VERSION ""

NS_ :

BS_:

BU_:IC_MMI AVM GW AC BCM DSM_D DSM_P FSCM CWC

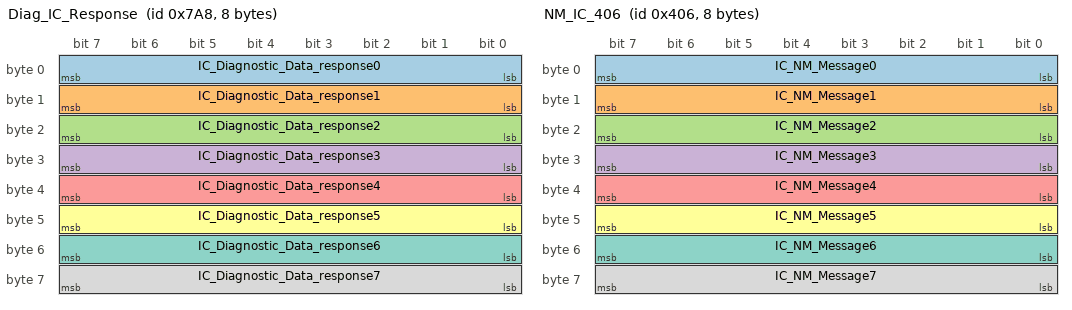
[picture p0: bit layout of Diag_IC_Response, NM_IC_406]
BO_ 1960 Diag_IC_Response: 8 IC_MMI
 SG_ IC_Diagnostic_Data_response0 : 7|8@0+ (1,0) [0|255] "" GW
 SG_ IC_Diagnostic_Data_response1 : 15|8@0+ (1,0) [0|255] "" GW
 SG_ IC_Diagnostic_Data_response2 : 23|8@0+ (1,0) [0|255] "" GW
 SG_ IC_Diagnostic_Data_response3 : 31|8@0+ (1,0) [0|255] "" GW
 SG_ IC_Diagnostic_Data_response4 : 39|8@0+ (1,0) [0|255] "" GW
 SG_ IC_Diagnostic_Data_response5 : 47|8@0+ (1,0) [0|255] "" GW
 SG_ IC_Diagnostic_Data_response6 : 55|8@0+ (1,0) [0|255] "" GW
 SG_ IC_Diagnostic_Data_response7 : 63|8@0+ (1,0) [0|255] "" GW

BO_ 1030 NM_IC_406: 8 IC_MMI
 SG_ IC_NM_Message0 : 7|8@0+ (1,0) [0|255] "" GW,AC,BCM
 SG_ IC_NM_Message1 : 15|8@0+ (1,0) [0|255] "" GW,AC,BCM
 SG_ IC_NM_Message2 : 23|8@0+ (1,0) [0|255] "" GW,AC,BCM
 SG_ IC_NM_Message3 : 31|8@0+ (1,0) [0|255] "" GW,AC,BCM
 SG_ IC_NM_Message4 : 39|8@0+ (1,0) [0|255] "" GW,AC,BCM
 SG_ IC_NM_Message5 : 47|8@0+ (1,0) [0|255] "" GW,AC,BCM
 SG_ IC_NM_Message6 : 55|8@0+ (1,0) [0|255] "" GW,AC,BCM
 SG_ IC_NM_Message7 : 63|8@0+ (1,0) [0|255] "" GW,AC,BCM

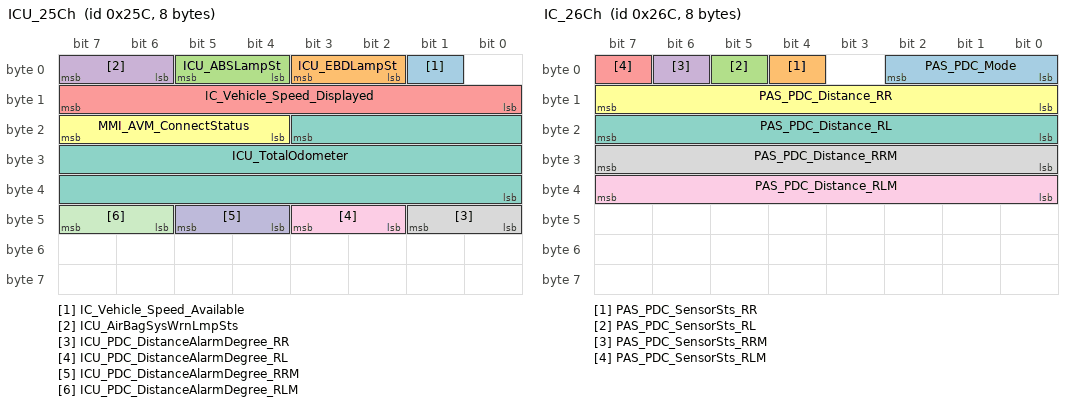
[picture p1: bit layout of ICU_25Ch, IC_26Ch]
BO_ 604 ICU_25Ch: 8 IC_MMI
 SG_ IC_Vehicle_Speed_Available : 1|1@0+ (1,0) [0|1] "" GW
 SG_ ICU_EBDLampSt : 3|2@0+ (1,0) [0|3] "" GW
 SG_ ICU_ABSLampSt : 5|2@0+ (1,0) [0|3] "" GW
 SG_ ICU_AirBagSysWrnLmpSts : 7|2@0+ (1,0) [0|3] "" GW
 SG_ IC_Vehicle_Speed_Displayed : 15|8@0+ (1,0) [0|255] "km/h" GW
 SG_ MMI_AVM_ConnectStatus : 23|4@0+ (1,0) [0|15] "" AVM,GW
 SG_ ICU_TotalOdometer : 19|20@0+ (1,0) [0|999999] "Km" AVM,GW,BCM
 SG_ ICU_PDC_DistanceAlarmDegree_RR : 41|2@0+ (1,0) [0|3] "" GW
 SG_ ICU_PDC_DistanceAlarmDegree_RL : 43|2@0+ (1,0) [0|3] "" GW
 SG_ ICU_PDC_DistanceAlarmDegree_RRM : 45|2@0+ (1,0) [0|3] "" GW
 SG_ ICU_PDC_DistanceAlarmDegree_RLM : 47|2@0+ (1,0) [0|3] "" GW

BO_ 620 IC_26Ch: 8 IC_MMI
 SG_ PAS_PDC_Mode : 2|3@0+ (1,0) [0|7] "" GW
 SG_ PAS_PDC_SensorSts_RR : 4|1@0+ (1,0) [0|1] "" GW
 SG_ PAS_PDC_SensorSts_RL : 5|1@0+ (1,0) [0|1] "" GW
 SG_ PAS_PDC_SensorSts_RRM : 6|1@0+ (1,0) [0|1] "" GW
 SG_ PAS_PDC_SensorSts_RLM : 7|1@0+ (1,0) [0|1] "" GW
 SG_ PAS_PDC_Distance_RR : 15|8@0+ (0.01,0) [0|1.5] "m" GW
 SG_ PAS_PDC_Distance_RL : 23|8@0+ (0.01,0) [0|1.5] "m" GW
 SG_ PAS_PDC_Distance_RRM : 31|8@0+ (0.01,0) [0|1.5] "m" GW
 SG_ PAS_PDC_Distance_RLM : 39|8@0+ (0.01,0) [0|1.5] "m" GW

BO_ 648 MMI_288h: 8 IC_MMI
 SG_ MMI_ACAUTOReqValid : 0|1@0+ (1,0) [0|1] "" GW,AC
 SG_ MMI_ACAUTOReq : 1|1@0+ (1,0) [0|1] "" GW,AC
 SG_ MMI_ACCompressorReqValid : 2|1@0+ (1,0) [0|1] "" GW,AC
 SG_ MMI_ACCompressorReq : 3|1@0+ (1,0) [0|1] "" GW,AC
 SG_ MMI_ACMaxReqValid : 4|1@0+ (1,0) [0|1] "" GW,AC
 SG_ MMI_ACMaxReq : 5|1@0+ (1,0) [0|1] "" GW,AC
 SG_ MMI_ACOFFReqValid : 6|1@0+ (1,0) [0|1] "" GW,AC
 SG_ MMI_ACOFFReq : 7|1@0+ (1,0) [0|1] "" GW,AC
 SG_ MMI_InsideTempIncDecReqValid : 8|1@0+ (1,0) [0|1] "" GW,AC
 SG_ MMI_InsideTempIncDecReq : 9|1@0+ (1,0) [0|1] "" GW,AC
 SG_ MMI_BLOWERReqValid : 10|1@0+ (1,0) [0|1] "" GW,AC
 SG_ MMI_BLOWERReq : 11|1@0+ (1,0) [0|1] "" GW,AC
 SG_ MMI_ACBlowModeReqValid : 12|1@0+ (1,0) [0|1] "" GW,AC
 SG_ MMI_ACBlowModeReq : 15|3@0+ (1,0) [0|7] "" GW,AC
 SG_ MMI_CirculatingModeSetValid : 16|1@0+ (1,0) [0|1] "" GW,AC
 SG_ MMI_CirculatingModeSet : 17|1@0+ (1,0) [0|1] "" GW,AC
 SG_ MMI_InsideTempSetValid : 18|1@0+ (1,0) [0|1] "" GW,AC
 SG_ MMI_InsideTempSet : 23|5@0+ (0.5,18) [18|32] "℃" GW,AC
 SG_ MMI_SeatHeatReq_right : 25|2@0+ (1,0) [0|3] "" GW,AC
 SG_ MMI_SeatHeatReq_left : 27|2@0+ (1,0) [0|3] "" GW,AC
 SG_ MMI_BLOWERGearSetValid : 28|1@0+ (1,0) [0|1] "" GW,AC
 SG_ MMI_BLOWERGearSet : 31|3@0+ (1,0) [0|7] "" GW,AC
 SG_ MMI_FrontDeforstReq : 33|2@0+ (1,0) [0|3] "" GW,AC
 SG_ MMI_RearDeforstReq : 35|2@0+ (1,0) [0|3] "" GW,AC
 SG_ MMI_EnergyRecoveryContr : 38|3@0+ (1,0) [0|7] "" GW
 SG_ MMI_RearViewMirrorHeatReq : 41|2@0+ (1,0) [0|3] "" GW,AC
 SG_ MMI_AnionNegativeIonReq : 43|2@0+ (1,0) [0|3] "" GW,AC

BO_ 370 MMI_172h: 8 IC_MMI
 SG_ MMI_LDW_Main_Switch : 0|1@0+ (1,0) [0|1] "" GW
 SG_ MMI_LDW_Switch_Available : 1|1@0+ (1,0) [0|1] "" GW
 SG_ MMI_FCW_Sensitivity : 3|2@0+ (1,0) [0|3] "" GW
 SG_ MMI_FCW_Main_Switch : 4|1@0+ (1,0) [0|1] "" GW
 SG_ MMI_FCW_Switch_Available : 5|1@0+ (1,0) [0|1] "" GW
 SG_ MMI_AEB_Main_Switch : 6|1@0+ (1,0) [0|1] "" GW
 SG_ MMI_AEB_Switch_Available : 7|1@0+ (1,0) [0|1] "" GW
 SG_ MMI_TSR_Main_Switch : 10|1@0+ (1,0) [0|1] "" GW
 SG_ MMI_TSR_Switch_Available : 11|1@0+ (1,0) [0|1] "" GW
 SG_ MMI_IHC_Main_Switch : 12|1@0+ (1,0) [0|1] "" GW
 SG_ MMI_IHC_Switch_Available : 13|1@0+ (1,0) [0|1] "" GW
 SG_ MMI_LDW_Sensitivity : 15|2@0+ (1,0) [0|3] "" GW
 SG_ MMI_BSD_Main_Switch : 16|1@0+ (1,0) [0|1] "" GW
 SG_ MMI_BSD_Switch_Available : 17|1@0+ (1,0) [0|1] "" GW
 SG_ MMI_BSD_Sensitivity : 19|2@0+ (1,0) [0|3] "" GW
 SG_ MMI_EPS_ModeSwitch : 22|3@0+ (1,0) [0|7] "" GW
 SG_ MMI_PauseContinueChrgRQ : 25|2@0+ (1,0) [0|3] "" GW
 SG_ MMI_WCBS_CstSwitch : 26|1@0+ (1,0) [0|1] "" GW
 SG_ MMI_OperationMode : 30|3@0+ (1,0) [0|7] "" GW
 SG_ MMI_ChrgMaxPower : 38|7@0+ (1,0) [0|100] "%" GW
 SG_ MMI_ChrgCurrentSet : 47|8@0+ (0.1,0) [0|25.5] "A" GW

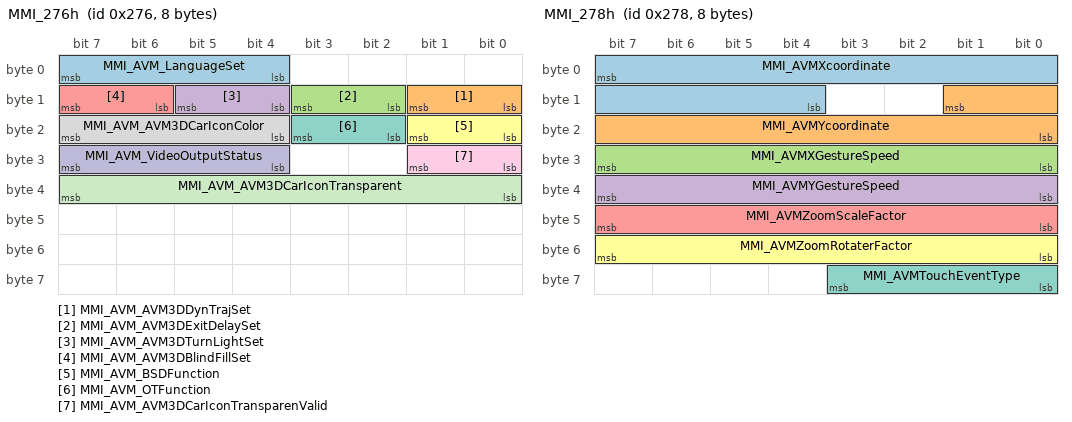
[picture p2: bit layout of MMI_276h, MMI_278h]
BO_ 630 MMI_276h: 8 IC_MMI
 SG_ MMI_AVM_LanguageSet : 7|4@0+ (1,0) [0|15] "" AVM,GW
 SG_ MMI_AVM_AVM3DDynTrajSet : 9|2@0+ (1,0) [0|3] "" AVM,GW
 SG_ MMI_AVM_AVM3DExitDelaySet : 11|2@0+ (1,0) [0|3] "" AVM,GW
 SG_ MMI_AVM_AVM3DTurnLightSet : 13|2@0+ (1,0) [0|3] "" AVM,GW
 SG_ MMI_AVM_AVM3DBlindFillSet : 15|2@0+ (1,0) [0|3] "" AVM,GW
 SG_ MMI_AVM_BSDFunction : 17|2@0+ (1,0) [0|3] "" AVM,GW
 SG_ MMI_AVM_OTFunction : 19|2@0+ (1,0) [0|3] "" AVM,GW
 SG_ MMI_AVM_AVM3DCarIconColor : 23|4@0+ (1,0) [0|15] "" AVM,GW
 SG_ MMI_AVM_AVM3DCarIconTransparenValid : 25|2@0+ (1,0) [0|3] "" AVM,GW
 SG_ MMI_AVM_VideoOutputStatus : 31|4@0+ (1,0) [0|15] "" AVM,GW
 SG_ MMI_AVM_AVM3DCarIconTransparent : 39|8@0+ (1,0) [0|100] "%" AVM,GW

BO_ 632 MMI_278h: 8 IC_MMI
 SG_ MMI_AVMXcoordinate : 7|12@0+ (1,0) [0|4094] "" AVM,GW
 SG_ MMI_AVMYcoordinate : 9|10@0+ (1,0) [0|1022] "" AVM,GW
 SG_ MMI_AVMXGestureSpeed : 31|8@0+ (1,0) [0|254] "pixels/100ms" AVM,GW
 SG_ MMI_AVMYGestureSpeed : 39|8@0+ (1,0) [0|254] "pixels/100ms" AVM,GW
 SG_ MMI_AVMZoomScaleFactor : 47|8@0+ (1,0) [0|254] "" AVM,GW
 SG_ MMI_AVMZoomRotaterFactor : 55|8@0+ (1,0) [0|254] "" AVM,GW
 SG_ MMI_AVMTouchEventType : 59|4@0+ (1,0) [0|15] "" AVM,GW

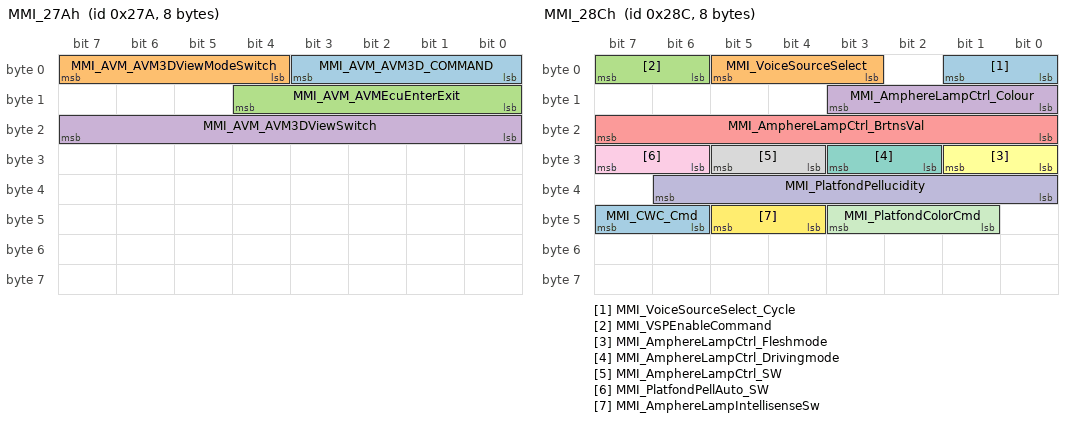
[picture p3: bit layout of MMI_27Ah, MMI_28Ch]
BO_ 634 MMI_27Ah: 8 IC_MMI
 SG_ MMI_AVM_AVM3D_COMMAND : 3|4@0+ (1,0) [0|15] "" AVM,GW
 SG_ MMI_AVM_AVM3DViewModeSwitch : 7|4@0+ (1,0) [0|15] "" AVM,GW
 SG_ MMI_AVM_AVMEcuEnterExit : 12|5@0+ (1,0) [0|31] "" AVM,GW
 SG_ MMI_AVM_AVM3DViewSwitch : 23|8@0+ (1,0) [0|255] "" AVM,GW

BO_ 652 MMI_28Ch: 8 IC_MMI
 SG_ MMI_VoiceSourceSelect_Cycle : 1|2@0+ (1,0) [0|3] "" GW
 SG_ MMI_VoiceSourceSelect : 5|3@0+ (1,0) [0|7] "" GW
 SG_ MMI_VSPEnableCommand : 7|2@0+ (1,0) [0|3] "" GW
 SG_ MMI_AmphereLampCtrl_Colour : 11|4@0+ (1,0) [0|15] "" GW
 SG_ MMI_AmphereLampCtrl_BrtnsVal : 23|8@0+ (1,0) [0|100] "" GW
 SG_ MMI_AmphereLampCtrl_Fleshmode : 25|2@0+ (1,0) [0|3] "" GW
 SG_ MMI_AmphereLampCtrl_Drivingmode : 27|2@0+ (1,0) [0|3] "" GW
 SG_ MMI_AmphereLampCtrl_SW : 29|2@0+ (1,0) [0|3] "" GW
 SG_ MMI_PlatfondPellAuto_SW : 31|2@0+ (1,0) [0|3] "" Vector__XXX
 SG_ MMI_PlatfondPellucidity : 38|7@0+ (1,0) [0|100] "%" Vector__XXX
 SG_ MMI_PlatfondColorCmd : 43|3@0+ (1,0) [0|7] "" GW
 SG_ MMI_AmphereLampIntellisenseSw : 45|2@0+ (1,0) [0|3] "" GW
 SG_ MMI_CWC_Cmd : 47|2@0+ (1,0) [0|3] "" GW,CWC

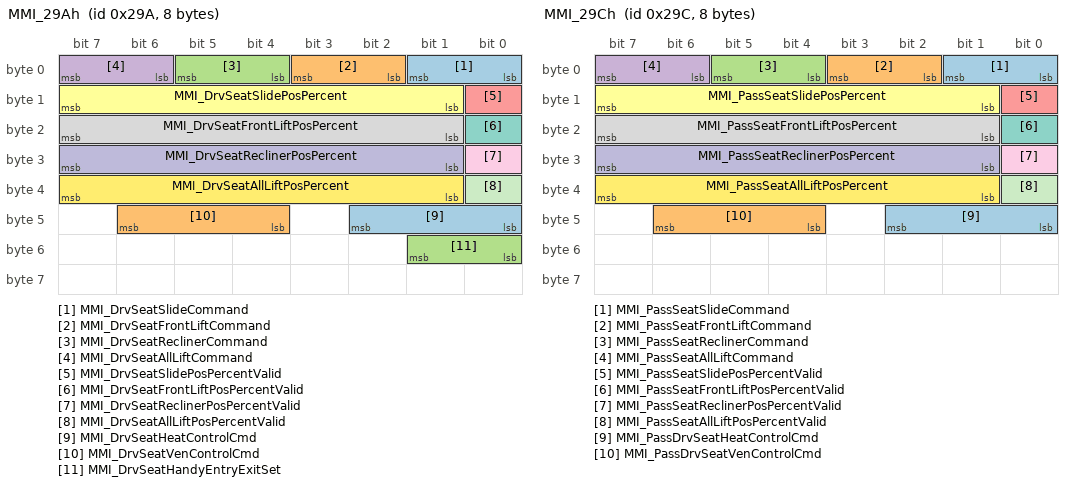
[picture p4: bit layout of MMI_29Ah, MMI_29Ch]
BO_ 666 MMI_29Ah: 8 IC_MMI
 SG_ MMI_DrvSeatSlideCommand : 1|2@0+ (1,0) [0|3] "" DSM_D
 SG_ MMI_DrvSeatFrontLiftCommand : 3|2@0+ (1,0) [0|3] "" DSM_D
 SG_ MMI_DrvSeatReclinerCommand : 5|2@0+ (1,0) [0|3] "" DSM_D
 SG_ MMI_DrvSeatAllLiftCommand : 7|2@0+ (1,0) [0|3] "" DSM_D
 SG_ MMI_DrvSeatSlidePosPercentValid : 8|1@0+ (1,0) [0|1] "" DSM_D
 SG_ MMI_DrvSeatSlidePosPercent : 15|7@0+ (1,0) [0|100] "%" DSM_D
 SG_ MMI_DrvSeatFrontLiftPosPercentValid : 16|1@0+ (1,0) [0|1] "" DSM_D
 SG_ MMI_DrvSeatFrontLiftPosPercent : 23|7@0+ (1,0) [0|100] "%" DSM_D
 SG_ MMI_DrvSeatReclinerPosPercentValid : 24|1@0+ (1,0) [0|1] "" DSM_D
 SG_ MMI_DrvSeatReclinerPosPercent : 31|7@0+ (1,0) [0|100] "%" DSM_D
 SG_ MMI_DrvSeatAllLiftPosPercentValid : 32|1@0+ (1,0) [0|1] "" DSM_D
 SG_ MMI_DrvSeatAllLiftPosPercent : 39|7@0+ (1,0) [0|100] "%" DSM_D
 SG_ MMI_DrvSeatHeatControlCmd : 42|3@0+ (1,0) [0|7] "" FSCM
 SG_ MMI_DrvSeatVenControlCmd : 46|3@0+ (1,0) [0|7] "" FSCM
 SG_ MMI_DrvSeatHandyEntryExitSet : 49|2@0+ (1,0) [0|3] "" DSM_D

BO_ 668 MMI_29Ch: 8 IC_MMI
 SG_ MMI_PassSeatSlideCommand : 1|2@0+ (1,0) [0|3] "" DSM_P
 SG_ MMI_PassSeatFrontLiftCommand : 3|2@0+ (1,0) [0|3] "" DSM_P
 SG_ MMI_PassSeatReclinerCommand : 5|2@0+ (1,0) [0|3] "" DSM_P
 SG_ MMI_PassSeatAllLiftCommand : 7|2@0+ (1,0) [0|3] "" DSM_P
 SG_ MMI_PassSeatSlidePosPercentValid : 8|1@0+ (1,0) [0|1] "" DSM_P
 SG_ MMI_PassSeatSlidePosPercent : 15|7@0+ (1,0) [0|100] "%" DSM_P
 SG_ MMI_PassSeatFrontLiftPosPercentValid : 16|1@0+ (1,0) [0|1] "" DSM_P
 SG_ MMI_PassSeatFrontLiftPosPercent : 23|7@0+ (1,0) [0|100] "%" DSM_P
 SG_ MMI_PassSeatReclinerPosPercentValid : 24|1@0+ (1,0) [0|1] "" DSM_P
 SG_ MMI_PassSeatReclinerPosPercent : 31|7@0+ (1,0) [0|100] "%" DSM_P
 SG_ MMI_PassSeatAllLiftPosPercentValid : 32|1@0+ (1,0) [0|1] "" DSM_P
 SG_ MMI_PassSeatAllLiftPosPercent : 39|7@0+ (1,0) [0|100] "%" DSM_P
 SG_ MMI_PassDrvSeatHeatControlCmd : 42|3@0+ (1,0) [0|7] "" FSCM
 SG_ MMI_PassDrvSeatVenControlCmd : 46|3@0+ (1,0) [0|7] "" FSCM

BO_ 670 MMI_29Eh: 8 IC_MMI
 SG_ MMI_HazardLightCmd : 1|2@0+ (1,0) [0|3] "" BCM
 SG_ MMI_BCMLightCmd : 3|2@0+ (1,0) [0|3] "" BCM
 SG_ MMI_TailgateCmd : 5|2@0+ (1,0) [0|3] "" BCM
 SG_ MMI_RearViewCmd : 7|2@0+ (1,0) [0|3] "" BCM
 SG_ MMI_DoorLockCmd : 11|2@0+ (1,0) [0|3] "" BCM
 SG_ MMI_LowBeamLightCmd : 13|2@0+ (1,0) [0|3] "" BCM
 SG_ MMI_HighBeamLightCmd : 15|2@0+ (1,0) [0|3] "" BCM
 SG_ MMI_FoglightCmd : 17|2@0+ (1,0) [0|3] "" BCM
 SG_ MMI_WiperCmd : 20|3@0+ (1,0) [0|7] "" BCM
 SG_ MMI_FronLeftDoorWindowCmd : 23|3@0+ (1,0) [0|7] "" BCM
 SG_ MMI_FronRightDoorWindowCmd : 26|3@0+ (1,0) [0|7] "" BCM
 SG_ MMI_RearLeftDoorWindowCmd : 29|3@0+ (1,0) [0|7] "" BCM
 SG_ MMI_FourDoorWindowCmd : 33|2@0+ (1,0) [0|3] "" BCM
 SG_ MMI_FrontDoorWindowCmd : 35|2@0+ (1,0) [0|3] "" BCM
 SG_ MMI_AutolightSWCmd : 37|2@0+ (1,0) [0|3] "" BCM
 SG_ MMI_RainAutoClsWindowCmd : 39|2@0+ (1,0) [0|3] "" BCM
 SG_ MMI_RearRightDoorWindowCmd : 42|3@0+ (1,0) [0|7] "" BCM
 SG_ MMI_RearViewMirrorSelect : 47|2@0+ (1,0) [0|3] "" BCM
 SG_ MMI_RearViewMirrorUpDown : 49|2@0+ (1,0) [0|3] "" BCM
 SG_ MMI_RearViewMirrorLeftRight : 51|2@0+ (1,0) [0|3] "" BCM
 SG_ MMI_LockVehicleWarmingTip : 53|2@0+ (1,0) [0|3] "" BCM
 SG_ MMI_UnlockVehicleOpenCourtesyLampSW : 55|2@0+ (1,0) [0|3] "" BCM
 SG_ MMI_AccLampSet : 59|2@0+ (1,0) [0|3] "" BCM
 SG_ MMI_RearViewMirrorAutoFoldFuc : 61|2@0+ (1,0) [0|3] "" BCM

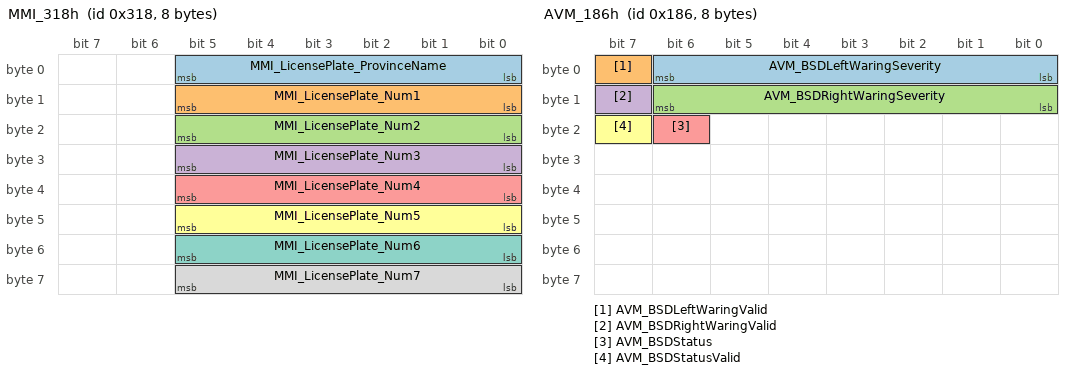
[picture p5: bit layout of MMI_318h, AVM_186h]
BO_ 792 MMI_318h: 8 IC_MMI
 SG_ MMI_LicensePlate_ProvinceName : 5|6@0+ (1,0) [0|31] "" AVM,GW
 SG_ MMI_LicensePlate_Num1 : 13|6@0+ (1,0) [0|36] "" AVM,GW
 SG_ MMI_LicensePlate_Num2 : 21|6@0+ (1,0) [0|36] "" AVM,GW
 SG_ MMI_LicensePlate_Num3 : 29|6@0+ (1,0) [0|36] "" AVM,GW
 SG_ MMI_LicensePlate_Num4 : 37|6@0+ (1,0) [0|36] "" AVM,GW
 SG_ MMI_LicensePlate_Num5 : 45|6@0+ (1,0) [0|36] "" AVM,GW
 SG_ MMI_LicensePlate_Num6 : 53|6@0+ (1,0) [0|36] "" AVM,GW
 SG_ MMI_LicensePlate_Num7 : 61|6@0+ (1,0) [0|36] "" AVM,GW

BO_ 390 AVM_186h: 8 AVM
 SG_ AVM_BSDLeftWaringSeverity : 6|7@0+ (1,0) [0|126] "" IC_MMI
 SG_ AVM_BSDLeftWaringValid : 7|1@0+ (1,0) [0|1] "" IC_MMI
 SG_ AVM_BSDRightWaringSeverity : 14|7@0+ (1,0) [0|126] "" IC_MMI
 SG_ AVM_BSDRightWaringValid : 15|1@0+ (1,0) [0|1] "" IC_MMI
 SG_ AVM_BSDStatus : 22|1@0+ (1,0) [0|1] "" IC_MMI
 SG_ AVM_BSDStatusValid : 23|1@0+ (1,0) [0|1] "" IC_MMI

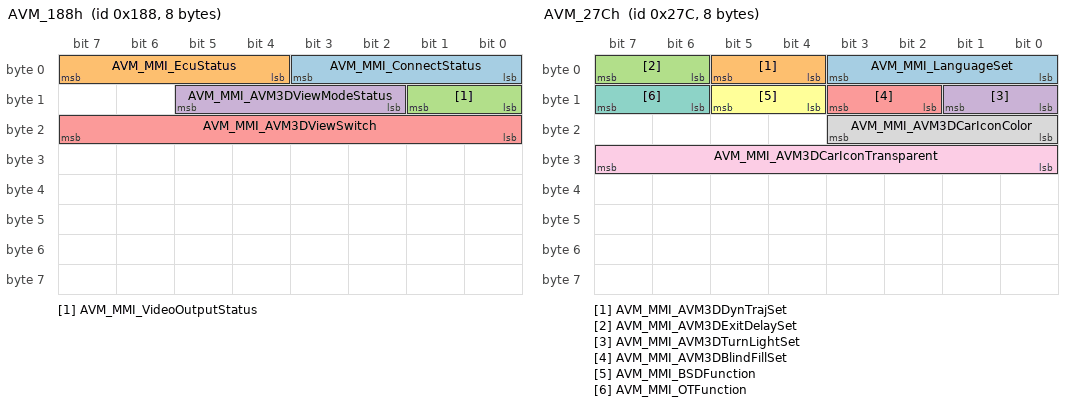
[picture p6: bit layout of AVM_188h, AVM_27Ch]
BO_ 392 AVM_188h: 8 AVM
 SG_ AVM_MMI_ConnectStatus : 3|4@0+ (1,0) [0|7] "" IC_MMI
 SG_ AVM_MMI_EcuStatus : 7|4@0+ (1,0) [0|3] "" IC_MMI
 SG_ AVM_MMI_VideoOutputStatus : 9|2@0+ (1,0) [0|3] "" IC_MMI
 SG_ AVM_MMI_AVM3DViewModeStatus : 13|4@0+ (1,0) [0|15] "" IC_MMI
 SG_ AVM_MMI_AVM3DViewSwitch : 23|8@0+ (1,0) [0|255] "" IC_MMI

BO_ 636 AVM_27Ch: 8 AVM
 SG_ AVM_MMI_LanguageSet : 3|4@0+ (1,0) [0|15] "" IC_MMI
 SG_ AVM_MMI_AVM3DDynTrajSet : 5|2@0+ (1,0) [0|3] "" IC_MMI
 SG_ AVM_MMI_AVM3DExitDelaySet : 7|2@0+ (1,0) [0|3] "" IC_MMI
 SG_ AVM_MMI_AVM3DTurnLightSet : 9|2@0+ (1,0) [0|3] "" IC_MMI
 SG_ AVM_MMI_AVM3DBlindFillSet : 11|2@0+ (1,0) [0|3] "" IC_MMI
 SG_ AVM_MMI_BSDFunction : 13|2@0+ (1,0) [0|3] "" IC_MMI
 SG_ AVM_MMI_OTFunction : 15|2@0+ (1,0) [0|3] "" IC_MMI
 SG_ AVM_MMI_AVM3DCarIconColor : 19|4@0+ (1,0) [0|15] "" IC_MMI
 SG_ AVM_MMI_AVM3DCarIconTransparent : 31|8@0+ (1,0) [0|100] "%" IC_MMI

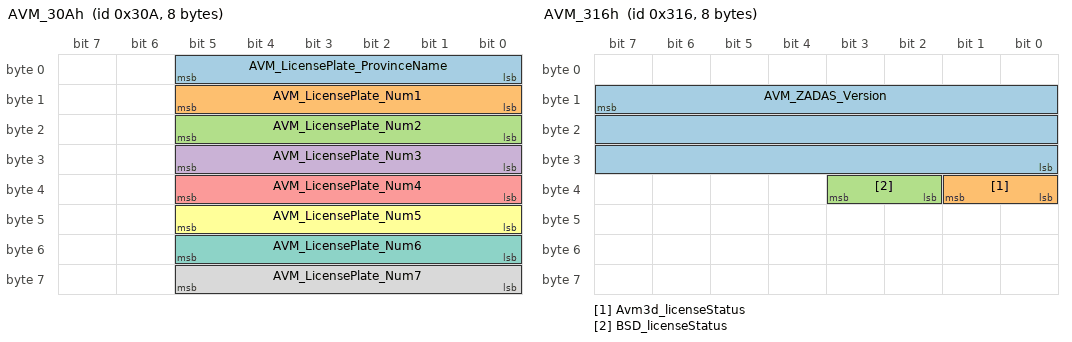
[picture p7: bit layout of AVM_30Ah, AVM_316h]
BO_ 778 AVM_30Ah: 8 AVM
 SG_ AVM_LicensePlate_ProvinceName : 5|6@0+ (1,0) [0|31] "" IC_MMI
 SG_ AVM_LicensePlate_Num1 : 13|6@0+ (1,0) [0|36] "" IC_MMI
 SG_ AVM_LicensePlate_Num2 : 21|6@0+ (1,0) [0|36] "" IC_MMI
 SG_ AVM_LicensePlate_Num3 : 29|6@0+ (1,0) [0|36] "" IC_MMI
 SG_ AVM_LicensePlate_Num4 : 37|6@0+ (1,0) [0|36] "" IC_MMI
 SG_ AVM_LicensePlate_Num5 : 45|6@0+ (1,0) [0|36] "" IC_MMI
 SG_ AVM_LicensePlate_Num6 : 53|6@0+ (1,0) [0|36] "" IC_MMI
 SG_ AVM_LicensePlate_Num7 : 61|6@0+ (1,0) [0|36] "" IC_MMI

BO_ 788 AVM_314h: 8 AVM
 SG_ AVM_MCU_Version : 15|24@0+ (1,0) [0|16777214] "" IC_MMI
 SG_ AVM_BSP_Version : 39|24@0+ (1,0) [0|16777214] "" IC_MMI

BO_ 790 AVM_316h: 8 AVM
 SG_ AVM_ZADAS_Version : 15|24@0+ (1,0) [0|16777214] "" IC_MMI
 SG_ Avm3d_licenseStatus : 33|2@0+ (1,0) [0|3] "" IC_MMI
 SG_ BSD_licenseStatus : 35|2@0+ (1,0) [0|3] "" IC_MMI

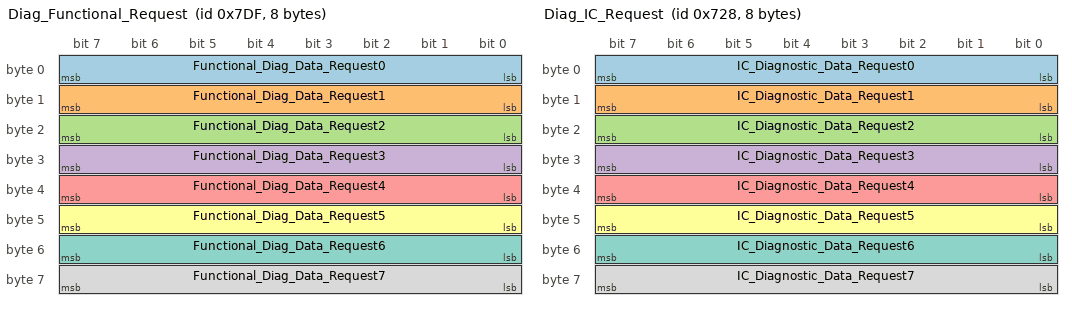
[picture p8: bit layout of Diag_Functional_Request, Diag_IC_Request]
BO_ 2015 Diag_Functional_Request: 8 GW
 SG_ Functional_Diag_Data_Request0 : 7|8@0+ (1,0) [0|255] "" IC_MMI,AVM,AC,BCM,DSM_D,DSM_P,FSCM,CWC
 SG_ Functional_Diag_Data_Request1 : 15|8@0+ (1,0) [0|255] "" IC_MMI,AVM,AC,BCM,DSM_D,DSM_P,FSCM,CWC
 SG_ Functional_Diag_Data_Request2 : 23|8@0+ (1,0) [0|255] "" IC_MMI,AVM,AC,BCM,DSM_D,DSM_P,FSCM,CWC
 SG_ Functional_Diag_Data_Request3 : 31|8@0+ (1,0) [0|255] "" IC_MMI,AVM,AC,BCM,DSM_D,DSM_P,FSCM,CWC
 SG_ Functional_Diag_Data_Request4 : 39|8@0+ (1,0) [0|255] "" IC_MMI,AVM,AC,BCM,DSM_D,DSM_P,FSCM,CWC
 SG_ Functional_Diag_Data_Request5 : 47|8@0+ (1,0) [0|255] "" IC_MMI,AVM,AC,BCM,DSM_D,DSM_P,FSCM,CWC
 SG_ Functional_Diag_Data_Request6 : 55|8@0+ (1,0) [0|255] "" IC_MMI,AVM,AC,BCM,DSM_D,DSM_P,FSCM,CWC
 SG_ Functional_Diag_Data_Request7 : 63|8@0+ (1,0) [0|255] "" IC_MMI,AVM,AC,BCM,DSM_D,DSM_P,FSCM,CWC

BO_ 1832 Diag_IC_Request: 8 GW
 SG_ IC_Diagnostic_Data_Request0 : 7|8@0+ (1,0) [0|255] "" IC_MMI
 SG_ IC_Diagnostic_Data_Request1 : 15|8@0+ (1,0) [0|255] "" IC_MMI
 SG_ IC_Diagnostic_Data_Request2 : 23|8@0+ (1,0) [0|255] "" IC_MMI
 SG_ IC_Diagnostic_Data_Request3 : 31|8@0+ (1,0) [0|255] "" IC_MMI
 SG_ IC_Diagnostic_Data_Request4 : 39|8@0+ (1,0) [0|255] "" IC_MMI
 SG_ IC_Diagnostic_Data_Request5 : 47|8@0+ (1,0) [0|255] "" IC_MMI
 SG_ IC_Diagnostic_Data_Request6 : 55|8@0+ (1,0) [0|255] "" IC_MMI
 SG_ IC_Diagnostic_Data_Request7 : 63|8@0+ (1,0) [0|255] "" IC_MMI

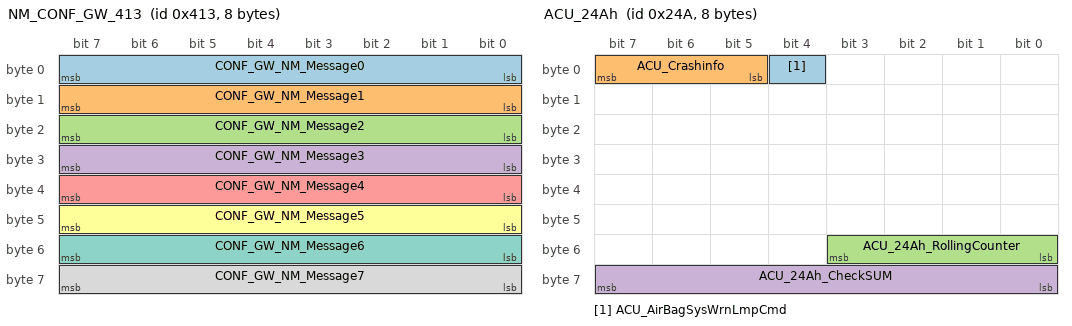
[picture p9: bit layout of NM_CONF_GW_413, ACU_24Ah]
BO_ 1043 NM_CONF_GW_413: 8 GW
 SG_ CONF_GW_NM_Message0 : 7|8@0+ (1,0) [0|255] "" IC_MMI,AC,BCM
 SG_ CONF_GW_NM_Message1 : 15|8@0+ (1,0) [0|255] "" IC_MMI,AC,BCM
 SG_ CONF_GW_NM_Message2 : 23|8@0+ (1,0) [0|255] "" IC_MMI,AC,BCM
 SG_ CONF_GW_NM_Message3 : 31|8@0+ (1,0) [0|255] "" IC_MMI,AC,BCM
 SG_ CONF_GW_NM_Message4 : 39|8@0+ (1,0) [0|255] "" IC_MMI,AC,BCM
 SG_ CONF_GW_NM_Message5 : 47|8@0+ (1,0) [0|255] "" IC_MMI,AC,BCM
 SG_ CONF_GW_NM_Message6 : 55|8@0+ (1,0) [0|255] "" IC_MMI,AC,BCM
 SG_ CONF_GW_NM_Message7 : 63|8@0+ (1,0) [0|255] "" IC_MMI,AC,BCM

BO_ 586 ACU_24Ah: 8 GW
 SG_ ACU_AirBagSysWrnLmpCmd : 4|1@0+ (1,0) [0|1] "" IC_MMI,BCM
 SG_ ACU_Crashinfo : 7|3@0+ (1,0) [0|7] "" IC_MMI,BCM
 SG_ ACU_24Ah_RollingCounter : 51|4@0+ (1,0) [0|15] "" IC_MMI,BCM
 SG_ ACU_24Ah_CheckSUM : 63|8@0+ (1,0) [0|255] "" IC_MMI,BCM

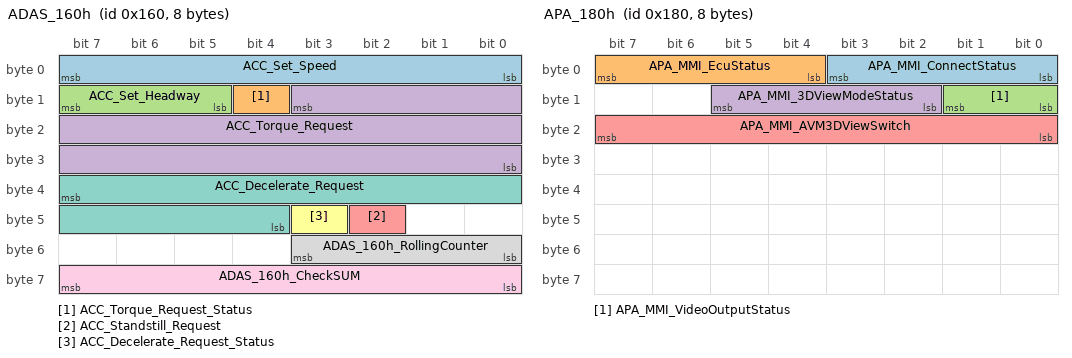
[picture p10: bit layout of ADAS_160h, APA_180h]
BO_ 352 ADAS_160h: 8 GW
 SG_ ACC_Set_Speed : 7|8@0+ (1,0) [0|255] "kph" IC_MMI
 SG_ ACC_Torque_Request_Status : 12|1@0+ (1,0) [0|1] "" IC_MMI
 SG_ ACC_Set_Headway : 15|3@0+ (1,0) [0|7] "" IC_MMI
 SG_ ACC_Torque_Request : 11|20@0+ (0.0625,-10000) [-10000|10000] "Nm" IC_MMI
 SG_ ACC_Standstill_Request : 42|1@0+ (1,0) [0|1] "" IC_MMI
 SG_ ACC_Decelerate_Request_Status : 43|1@0+ (1,0) [0|1] "" IC_MMI
 SG_ ACC_Decelerate_Request : 39|12@0+ (0.01,-20.47) [-20.47|20.47] "m/s2" IC_MMI
 SG_ ADAS_160h_RollingCounter : 51|4@0+ (1,0) [0|15] "" IC_MMI
 SG_ ADAS_160h_CheckSUM : 63|8@0+ (1,0) [0|255] "" IC_MMI

BO_ 354 ADAS_162h: 8 GW
 SG_ AEB_EHB_StopReq : 1|1@0+ (1,0) [0|1] "" IC_MMI
 SG_ AEB_Jerk_Request : 2|1@0+ (1,0) [0|1] "" IC_MMI
 SG_ AEB_Prefill_Request : 3|1@0+ (1,0) [0|1] "" IC_MMI
 SG_ AEB_Decelerate_Request_Status : 4|1@0+ (1,0) [0|1] "" IC_MMI
 SG_ AEB_State : 7|3@0+ (1,0) [0|7] "" IC_MMI
 SG_ FCW_State : 19|3@0+ (1,0) [0|7] "" IC_MMI
 SG_ AEB_Decelerate_Request : 15|12@0+ (0.01,-20.47) [-20.47|20.47] "m/s2" IC_MMI
 SG_ ADAS_Sensorstatus : 27|3@0+ (1,0) [0|7] "" IC_MMI
 SG_ HW_Warning_Level : 29|2@0+ (1,0) [0|3] "" IC_MMI
 SG_ FCW_Warning_Level : 31|2@0+ (1,0) [0|3] "" IC_MMI
 SG_ ACC_Override_Indicator : 32|1@0+ (1,0) [0|1] "" IC_MMI
 SG_ ACC_CIPV_Indicator : 33|1@0+ (1,0) [0|1] "" IC_MMI
 SG_ ACC_Auto_Cancel : 35|2@0+ (1,0) [0|2] "" IC_MMI
 SG_ ACC_Driver_Cancel : 36|1@0+ (1,0) [0|1] "" IC_MMI
 SG_ ACC_State : 39|3@0+ (1,0) [0|7] "" IC_MMI,AVM
 SG_ ACC_Go_Indicator : 46|1@0+ (1,0) [0|1] "" IC_MMI
 SG_ ACC_Takeover_Indicator : 47|1@0+ (1,0) [0|1] "" IC_MMI
 SG_ ADAS_162h_RollingCounter : 51|4@0+ (1,0) [0|15] "" IC_MMI
 SG_ ADAS_162h_CheckSUM : 63|8@0+ (1,0) [0|255] "" IC_MMI

BO_ 356 ADAS_164h: 8 GW
 SG_ TSR_State : 2|3@0+ (1,0) [0|4] "" IC_MMI
 SG_ DAS_TSR_Main_Switch : 3|1@0+ (1,0) [0|1] "" IC_MMI
 SG_ IHC_Mainbeam_Request : 4|1@0+ (1,0) [0|1] "" IC_MMI,BCM
 SG_ IHC_State : 7|3@0+ (1,0) [0|7] "" IC_MMI,BCM
 SG_ LDW_Line_Detect_Status : 10|3@0+ (1,0) [0|3] "" IC_MMI
 SG_ LDW_Warning : 12|2@0+ (1,0) [0|3] "" IC_MMI
 SG_ LDW_State : 15|3@0+ (1,0) [0|4] "" IC_MMI
 SG_ TSR_Targetspeed_Request : 23|8@0+ (1,0) [0|254] "km/h" IC_MMI
 SG_ LKA_Torque_Request_Status : 28|1@0+ (1,0) [0|1] "" IC_MMI
 SG_ LKA_State : 31|3@0+ (1,0) [0|5] "" IC_MMI
 SG_ LKA_Torque_Request : 26|11@0+ (0.01,-10.24) [-10.24|10.23] "Nm" IC_MMI
 SG_ ADAS_164h_RollingCounter : 43|4@0+ (1,0) [0|15] "" IC_MMI
 SG_ LKA_Takeover_Request : 46|1@0+ (1,0) [0|1] "" IC_MMI
 SG_ LKA_Hands_Off_Warning : 47|1@0+ (1,0) [0|1] "" IC_MMI
 SG_ DAS_LDW_Main_Switch : 48|1@0+ (1,0) [0|1] "" IC_MMI
 SG_ DAS_LDW_Sensitivity : 50|2@0+ (1,0) [0|3] "" IC_MMI
 SG_ DAS_FCW_Main_Switch : 51|1@0+ (1,0) [0|1] "" IC_MMI
 SG_ DAS_FCW_Sensitivity : 53|2@0+ (1,0) [0|3] "" IC_MMI
 SG_ DAS_AEB_Main_Switch : 54|1@0+ (1,0) [0|1] "" IC_MMI
 SG_ DAS_IHC_Main_Switch : 55|1@0+ (1,0) [0|1] "" IC_MMI
 SG_ ADAS_164h_CheckSUM : 63|8@0+ (1,0) [0|255] "" IC_MMI

BO_ 384 APA_180h: 8 GW
 SG_ APA_MMI_ConnectStatus : 3|4@0+ (1,0) [0|7] "" IC_MMI
 SG_ APA_MMI_EcuStatus : 7|4@0+ (1,0) [0|3] "" IC_MMI
 SG_ APA_MMI_VideoOutputStatus : 9|2@0+ (1,0) [0|3] "" IC_MMI
 SG_ APA_MMI_3DViewModeStatus : 13|4@0+ (1,0) [0|15] "" IC_MMI
 SG_ APA_MMI_AVM3DViewSwitch : 23|8@0+ (1,0) [0|255] "" IC_MMI

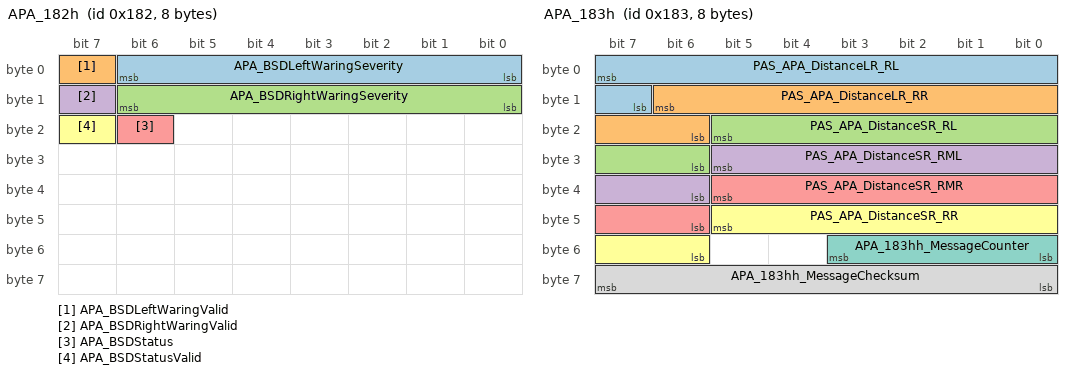
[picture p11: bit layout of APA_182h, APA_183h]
BO_ 386 APA_182h: 8 GW
 SG_ APA_BSDLeftWaringSeverity : 6|7@0+ (1,0) [0|126] "" IC_MMI
 SG_ APA_BSDLeftWaringValid : 7|1@0+ (1,0) [0|1] "" IC_MMI
 SG_ APA_BSDRightWaringSeverity : 14|7@0+ (1,0) [0|126] "" IC_MMI
 SG_ APA_BSDRightWaringValid : 15|1@0+ (1,0) [0|1] "" IC_MMI
 SG_ APA_BSDStatus : 22|1@0+ (1,0) [0|1] "" IC_MMI
 SG_ APA_BSDStatusValid : 23|1@0+ (1,0) [0|1] "" IC_MMI

BO_ 387 APA_183h: 8 GW
 SG_ PAS_APA_DistanceLR_RL : 7|9@0+ (0.01,0) [0|5] "m" IC_MMI
 SG_ PAS_APA_DistanceLR_RR : 14|9@0+ (0.01,0) [0|5] "m" IC_MMI
 SG_ PAS_APA_DistanceSR_RL : 21|8@0+ (0.01,0) [0|2.5] "m" IC_MMI
 SG_ PAS_APA_DistanceSR_RML : 29|8@0+ (0.01,0) [0|2.5] "m" IC_MMI
 SG_ PAS_APA_DistanceSR_RMR : 37|8@0+ (0.01,0) [0|2.5] "m" IC_MMI
 SG_ PAS_APA_DistanceSR_RR : 45|8@0+ (0.01,0) [0|2.5] "m" IC_MMI
 SG_ APA_183hh_MessageCounter : 51|4@0+ (1,0) [0|15] "" IC_MMI
 SG_ APA_183hh_MessageChecksum : 63|8@0+ (1,0) [0|255] "" IC_MMI

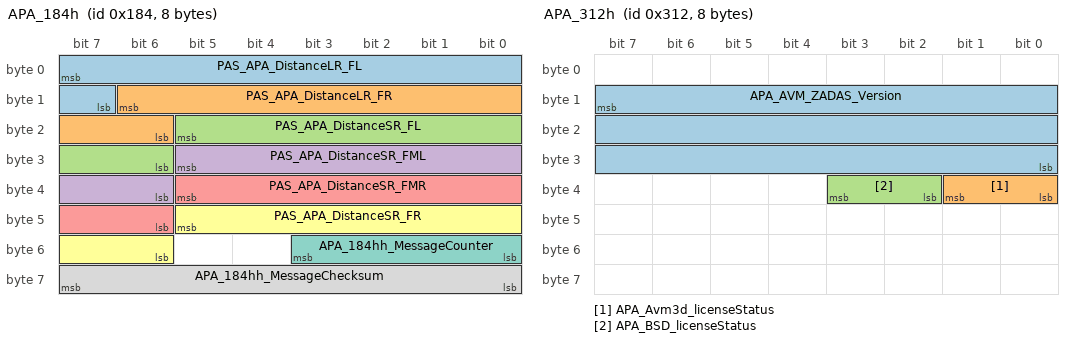
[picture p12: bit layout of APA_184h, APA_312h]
BO_ 388 APA_184h: 8 GW
 SG_ PAS_APA_DistanceLR_FL : 7|9@0+ (0.01,0) [0|5] "m" IC_MMI
 SG_ PAS_APA_DistanceLR_FR : 14|9@0+ (0.01,0) [0|5] "m" IC_MMI
 SG_ PAS_APA_DistanceSR_FL : 21|8@0+ (0.01,0) [0|2.5] "m" IC_MMI
 SG_ PAS_APA_DistanceSR_FML : 29|8@0+ (0.01,0) [0|2.5] "m" IC_MMI
 SG_ PAS_APA_DistanceSR_FMR : 37|8@0+ (0.01,0) [0|2.5] "m" IC_MMI
 SG_ PAS_APA_DistanceSR_FR : 45|8@0+ (0.01,0) [0|2.5] "m" IC_MMI
 SG_ APA_184hh_MessageCounter : 51|4@0+ (1,0) [0|15] "" IC_MMI
 SG_ APA_184hh_MessageChecksum : 63|8@0+ (1,0) [0|255] "" IC_MMI

BO_ 784 APA_310h: 8 GW
 SG_ APA_AVM_MCU_Version : 15|24@0+ (1,0) [0|16777214] "" IC_MMI
 SG_ APA_AVM_BSP_Version : 39|24@0+ (1,0) [0|16777214] "" IC_MMI

BO_ 786 APA_312h: 8 GW
 SG_ APA_AVM_ZADAS_Version : 15|24@0+ (1,0) [0|16777214] "" IC_MMI
 SG_ APA_Avm3d_licenseStatus : 33|2@0+ (1,0) [0|3] "" IC_MMI
 SG_ APA_BSD_licenseStatus : 35|2@0+ (1,0) [0|3] "" IC_MMI

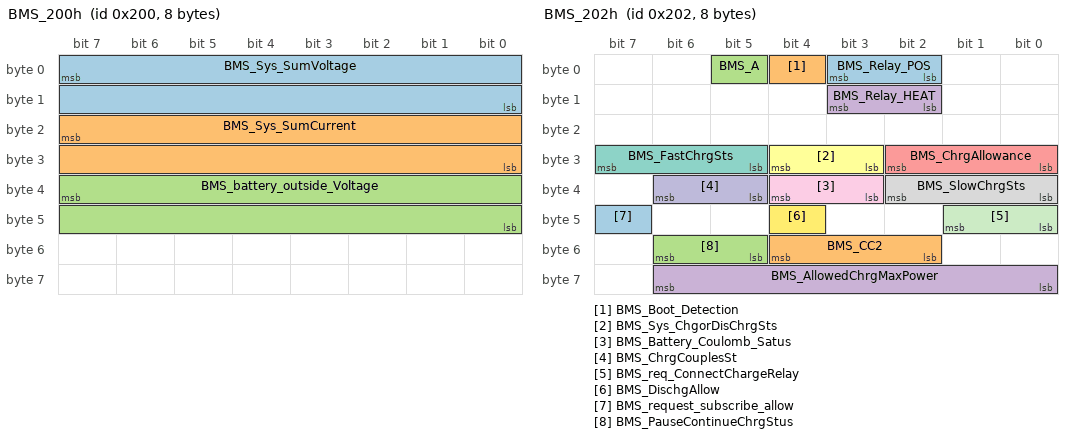
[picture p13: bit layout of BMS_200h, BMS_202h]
BO_ 512 BMS_200h: 8 GW
 SG_ BMS_Sys_SumVoltage : 7|16@0+ (0.1,0) [0|6000] "V" IC_MMI,AC
 SG_ BMS_Sys_SumCurrent : 23|16@0+ (0.1,-3000) [-3000|3000] "A" IC_MMI,AC
 SG_ BMS_battery_outside_Voltage : 39|16@0+ (0.1,0) [0|6000] "V" IC_MMI

BO_ 514 BMS_202h: 8 GW
 SG_ BMS_Relay_POS : 3|2@0+ (1,0) [0|3] "" IC_MMI
 SG_ BMS_Boot_Detection : 4|1@0+ (1,0) [0|1] "" IC_MMI
 SG_ BMS_A : 5|1@0+ (1,0) [0|1] "" IC_MMI
 SG_ BMS_Relay_HEAT : 11|2@0+ (1,0) [0|3] "" IC_MMI
 SG_ BMS_ChrgAllowance : 26|3@0+ (1,0) [0|7] "" IC_MMI
 SG_ BMS_Sys_ChgorDisChrgSts : 28|2@0+ (1,0) [0|3] "" IC_MMI,AC
 SG_ BMS_FastChrgSts : 31|3@0+ (1,0) [0|7] "" IC_MMI
 SG_ BMS_SlowChrgSts : 34|3@0+ (1,0) [0|7] "" IC_MMI
 SG_ BMS_Battery_Coulomb_Satus : 36|2@0+ (1,0) [0|3] "" IC_MMI
 SG_ BMS_ChrgCouplesSt : 38|2@0+ (1,0) [0|3] "" IC_MMI
 SG_ BMS_req_ConnectChargeRelay : 41|2@0+ (1,0) [0|3] "" IC_MMI
 SG_ BMS_DischgAllow : 44|1@0+ (1,0) [0|1] "" IC_MMI
 SG_ BMS_request_subscribe_allow : 47|1@0+ (1,0) [0|1] "" IC_MMI
 SG_ BMS_CC2 : 52|3@0+ (1,0) [0|7] "" IC_MMI
 SG_ BMS_PauseContinueChrgStus : 54|2@0+ (1,0) [0|3] "" IC_MMI
 SG_ BMS_AllowedChrgMaxPower : 62|7@0+ (1,0) [0|100] "%" IC_MMI

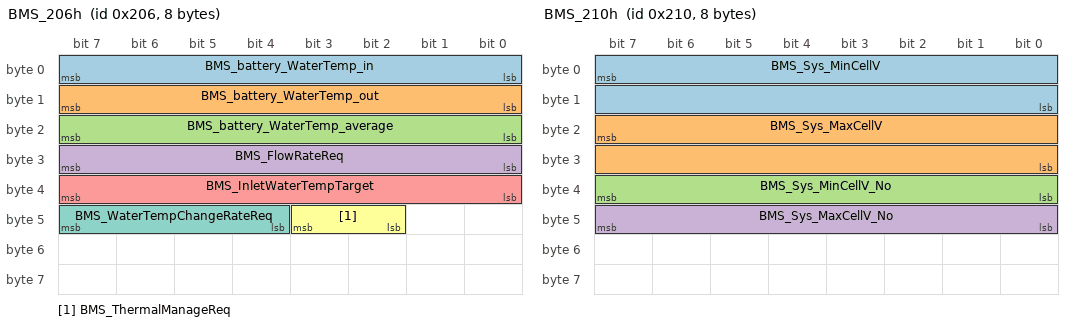
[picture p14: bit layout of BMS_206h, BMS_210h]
BO_ 518 BMS_206h: 8 GW
 SG_ BMS_battery_WaterTemp_in : 7|8@0+ (1,-40) [-40|214] "℃" IC_MMI,AC
 SG_ BMS_battery_WaterTemp_out : 15|8@0+ (1,-40) [-40|214] "℃" IC_MMI,AC
 SG_ BMS_battery_WaterTemp_average : 23|8@0+ (1,-40) [-40|214] "℃" IC_MMI,AC
 SG_ BMS_FlowRateReq : 31|8@0+ (0.1,0) [0|25.4] "L/min" IC_MMI,AC
 SG_ BMS_InletWaterTempTarget : 39|8@0+ (0.5,-40) [-40|87] "℃" IC_MMI,AC
 SG_ BMS_ThermalManageReq : 43|2@0+ (1,0) [0|3] "" IC_MMI,AC
 SG_ BMS_WaterTempChangeRateReq : 47|4@0+ (1,0) [0|15] "℃/min" IC_MMI,AC

BO_ 524 BMS_20Ch: 8 GW
 SG_ BMS_Powertrain_System_fault : 1|2@0+ (1,0) [0|3] "" IC_MMI
 SG_ BMS_cell_Voltage_low : 5|2@0+ (1,0) [0|3] "" IC_MMI
 SG_ BMS_cell_Voltage_High : 7|2@0+ (1,0) [0|3] "" IC_MMI
 SG_ BMS_Battery_LowTemp_warning : 9|2@0+ (1,0) [0|3] "" IC_MMI
 SG_ BMS_Battery_HighTemp_warning : 11|2@0+ (1,0) [0|3] "" IC_MMI
 SG_ BMS_SOCHigh_Warning : 17|2@0+ (1,0) [0|3] "" IC_MMI
 SG_ BMS_SOCLow_Warning : 19|2@0+ (1,0) [0|3] "" IC_MMI
 SG_ BMS_Battery_SumVoltage_High : 21|2@0+ (1,0) [0|3] "" IC_MMI
 SG_ BMS_Battery_SumVoltage_Low : 23|2@0+ (1,0) [0|3] "" IC_MMI
 SG_ BMS_HVBatCellDiffFalt : 25|2@0+ (1,0) [0|3] "" IC_MMI
 SG_ BMS_Err_OverVoltageFault : 27|2@0+ (1,0) [0|3] "" IC_MMI
 SG_ BMS_Battery_charge_Fault : 29|2@0+ (1,0) [0|3] "" IC_MMI
 SG_ BMS_SOCJump_Warning : 31|2@0+ (1,0) [0|3] "" IC_MMI
 SG_ BMS_Err_CellT_Low : 35|2@0+ (1,0) [0|3] "" IC_MMI
 SG_ BMS_Err_CellT_High : 37|2@0+ (1,0) [0|3] "" IC_MMI
 SG_ BMS_BatNotMatchFlt : 39|2@0+ (1,0) [0|3] "" IC_MMI
 SG_ BMS_Err_ISO_LOW : 41|2@0+ (1,0) [0|3] "" IC_MMI
 SG_ BMS_Err_ChgCurrent_High : 43|2@0+ (1,0) [0|3] "" IC_MMI
 SG_ BMS_Err_DchCurrent_High : 45|2@0+ (1,0) [0|3] "" IC_MMI
 SG_ BMS_Err_DtT_High : 47|2@0+ (1,0) [0|3] "" IC_MMI
 SG_ ThermalManage_System_fault : 49|2@0+ (1,0) [0|3] "" IC_MMI
 SG_ BMS_Err_comunicacion : 51|2@0+ (1,0) [0|3] "" IC_MMI
 SG_ BMS_Err_InterLock : 52|1@0+ (1,0) [0|1] "" IC_MMI
 SG_ BMS_Circuit_Protection : 53|1@0+ (1,0) [0|1] "" IC_MMI
 SG_ BMS_FeedFault : 55|2@0+ (1,0) [0|3] "" IC_MMI
 SG_ BMS_TotalErrNumber : 63|8@0+ (1,0) [0|254] "" IC_MMI

BO_ 528 BMS_210h: 8 GW
 SG_ BMS_Sys_MinCellV : 7|16@0+ (0.001,0) [0|5] "V" IC_MMI
 SG_ BMS_Sys_MaxCellV : 23|16@0+ (0.001,0) [0|5] "V" IC_MMI
 SG_ BMS_Sys_MinCellV_No : 39|8@0+ (1,0) [0|255] "" IC_MMI
 SG_ BMS_Sys_MaxCellV_No : 47|8@0+ (1,0) [0|255] "" IC_MMI

CM_ SG_ 604 IC_Vehicle_Speed_Available "indicates if IC is available
指示仪表车速信号是否可用";
CM_ SG_ 604 ICU_EBDLampSt "EBD灯的状态";
CM_ SG_ 604 ICU_ABSLampSt "ABS故障灯的状态";
CM_ SG_ 604 ICU_AirBagSysWrnLmpSts "Airbag System Warning Lamp Status
安全气囊报警指示灯状态";
CM_ SG_ 604 IC_Vehicle_Speed_Displayed "IPK displayed vehicle speed
仪表车速";
CM_ SG_ 604 MMI_AVM_ConnectStatus "MMI connect status
MMI 与AVM连接状态";
CM_ SG_ 604 ICU_TotalOdometer "Total Odometer 
总里程";
CM_ SG_ 604 ICU_PDC_DistanceAlarmDegree_RR "PDC rear right distance alarm degree
倒车雷达后右距离报警级别";
CM_ SG_ 604 ICU_PDC_DistanceAlarmDegree_RL "PDC rear left distance alarm degree
倒车雷达后左距离报警级别";
CM_ SG_ 604 ICU_PDC_DistanceAlarmDegree_RRM "PDC rear right midle distance alarm degree
倒车雷达后右中距离报警级别";
CM_ SG_ 604 ICU_PDC_DistanceAlarmDegree_RLM "PDC rear left midle distance alarm degree
倒车雷达后左中距离报警级别";
CM_ BO_ 620 "预留";
CM_ SG_ 620 PAS_PDC_Mode "PDC mode
倒车雷达的工作模式";
CM_ SG_ 620 PAS_PDC_SensorSts_RR "PDC Rear right sensor status
倒车雷达后右传感器状态";
CM_ SG_ 620 PAS_PDC_SensorSts_RL "PDC Rear left sensor status
倒车雷达后左传感器状态";
CM_ SG_ 620 PAS_PDC_SensorSts_RRM "PDC Rear right midle sensor status
倒车雷达后右中传感器状态";
CM_ SG_ 620 PAS_PDC_SensorSts_RLM "PDC Rear left midle sensor status
倒车雷达后左中传感器状态";
CM_ SG_ 620 PAS_PDC_Distance_RR "PDC Rear right distance display
倒车雷达后右区距离显示";
CM_ SG_ 620 PAS_PDC_Distance_RL "PDC Rear left distance display
倒车雷达后左区距离显示";
CM_ SG_ 620 PAS_PDC_Distance_RRM "PDC Rear right midle distance display
倒车雷达后右中区距离显示";
CM_ SG_ 620 PAS_PDC_Distance_RLM "PDC Rear left midle distance display
倒车雷达后左中区距离显示";
CM_ BO_ 648 "MMI发给空调的控制命令";
CM_ SG_ 648 MMI_ACAUTOReqValid "空调AUTO命令信号有效性";
CM_ SG_ 648 MMI_ACAUTOReq "空调AUTO命令";
CM_ SG_ 648 MMI_ACCompressorReqValid "空调压缩机命令信号有效性";
CM_ SG_ 648 MMI_ACCompressorReq "空调压缩机命令";
CM_ SG_ 648 MMI_ACMaxReqValid "最大制冷命令信号有效性";
CM_ SG_ 648 MMI_ACMaxReq "最大制冷命令请求";
CM_ SG_ 648 MMI_ACOFFReqValid "空调关机命令信号有效性";
CM_ SG_ 648 MMI_ACOFFReq "空调关机命令";
CM_ SG_ 648 MMI_InsideTempIncDecReqValid "温度增减命令信号有效性";
CM_ SG_ 648 MMI_InsideTempIncDecReq "温度增减命令
温度为18℃（LO）时，不响应温度减指令，温度为32℃（HI）时，不响应温度加指令；增减步进为0.5℃；";
CM_ SG_ 648 MMI_BLOWERReqValid "鼓风机风量增减命令信号有效性";
CM_ SG_ 648 MMI_BLOWERReq "鼓风机风量增减命令
风量为1档时，不执行风量减，风量为7时，不执行风量加指令";
CM_ SG_ 648 MMI_ACBlowModeReqValid "空调吹风模式命令信号有效性";
CM_ SG_ 648 MMI_ACBlowModeReq "空调吹风模式命令";
CM_ SG_ 648 MMI_CirculatingModeSetValid "循环模式设定信号有效性";
CM_ SG_ 648 MMI_CirculatingModeSet "循环模式设定";
CM_ SG_ 648 MMI_InsideTempSetValid "室内温度设定值命令信号有效性";
CM_ SG_ 648 MMI_InsideTempSet "室内温度设定值命令";
CM_ SG_ 648 MMI_SeatHeatReq_right "副驾座椅加热请求";
CM_ SG_ 648 MMI_SeatHeatReq_left "主驾座椅加热请求";
CM_ SG_ 648 MMI_BLOWERGearSetValid "鼓风机风量档位设定信号有效性";
CM_ SG_ 648 MMI_BLOWERGearSet "鼓风机风量档位设定
按照档位设定（1-7档），可在范围内设定；MMI下发指令设定风量时，直接赋值，不执行加减";
CM_ SG_ 648 MMI_FrontDeforstReq "前除霜控制命令";
CM_ SG_ 648 MMI_RearDeforstReq "后除霜控制命令";
CM_ SG_ 648 MMI_EnergyRecoveryContr "能量回收等级控制";
CM_ SG_ 648 MMI_RearViewMirrorHeatReq "外后视镜加热控制命令";
CM_ SG_ 648 MMI_AnionNegativeIonReq "负离子开关命令";
CM_ BO_ 370 "给ADAS、BSD、预约充电的开关信号";
CM_ SG_ 370 MMI_LDW_Main_Switch "LDW main switch status
LDW主开关状态";
CM_ SG_ 370 MMI_LDW_Switch_Available "indicates if LDW switch is available
指示LDW开关信号是否可用";
CM_ SG_ 370 MMI_FCW_Sensitivity "driver selected sensitivity level
驾驶员选择的FCW敏感等级";
CM_ SG_ 370 MMI_FCW_Main_Switch "FCW main switch status
FCW主开关状态";
CM_ SG_ 370 MMI_FCW_Switch_Available "indicates if FCW switch is available
指示FCW开关是否可用";
CM_ SG_ 370 MMI_AEB_Main_Switch "AEB main switch status
AEB主开关状态";
CM_ SG_ 370 MMI_AEB_Switch_Available "indicates if AEB switch is available
指示AEB开关信号是否可用";
CM_ SG_ 370 MMI_TSR_Main_Switch "TSR main switch status
TSR主开关状态";
CM_ SG_ 370 MMI_TSR_Switch_Available "indicates if TSR switch is available
指示TSR开关是否可用";
CM_ SG_ 370 MMI_IHC_Main_Switch "IHC main switch status
IHC主开关状态";
CM_ SG_ 370 MMI_IHC_Switch_Available "indicates if IHC switch is available
指示IHC开关信号是否可用";
CM_ SG_ 370 MMI_LDW_Sensitivity "driver selected sensitivity level
驾驶员选择的LDW敏感等级";
CM_ SG_ 370 MMI_BSD_Main_Switch "BSD main switch status
BSD主开关状态";
CM_ SG_ 370 MMI_BSD_Switch_Available "indicates if BSDswitch is available
指示BSD开关信号是否可用";
CM_ SG_ 370 MMI_BSD_Sensitivity "driver selected sensitivity level
驾驶员选择的BSD敏感等级";
CM_ SG_ 370 MMI_EPS_ModeSwitch "EPS Mode Select
EPS模式选择";
CM_ SG_ 370 MMI_PauseContinueChrgRQ "Pause/Continue charge Request
请求暂停/继续充电";
CM_ SG_ 370 MMI_WCBS_CstSwitch "Comfortable Brake Swtich
CST功能开关(预留)";
CM_ SG_ 370 MMI_OperationMode "Running mode
运行模式";
CM_ SG_ 370 MMI_ChrgMaxPower "Max Charging Power Set
最大充电电量设置";
CM_ SG_ 370 MMI_ChrgCurrentSet "Charge Current Set
充电电流设置";
CM_ BO_ 630 "MMI发给AVM的信号1(APA共用)";
CM_ SG_ 630 MMI_AVM_LanguageSet "语言设置";
CM_ SG_ 630 MMI_AVM_AVM3DDynTrajSet "AVM3D动态轨迹线设置";
CM_ SG_ 630 MMI_AVM_AVM3DExitDelaySet "AVM3D退出延迟设置";
CM_ SG_ 630 MMI_AVM_AVM3DTurnLightSet "AVM3D转向灯随动设置";
CM_ SG_ 630 MMI_AVM_AVM3DBlindFillSet "AVM3D车底盲区填充设置";
CM_ SG_ 630 MMI_AVM_BSDFunction "BSD功能是否开启";
CM_ SG_ 630 MMI_AVM_OTFunction "OTF功能是否开启";
CM_ SG_ 630 MMI_AVM_AVM3DCarIconColor "AVM车模颜色选择";
CM_ SG_ 630 MMI_AVM_AVM3DCarIconTransparenValid "AVM3D车模透明度是否有效";
CM_ SG_ 630 MMI_AVM_VideoOutputStatus "MMI AVM video outputstatus
MMI AVM 视频输出状态";
CM_ SG_ 630 MMI_AVM_AVM3DCarIconTransparent "AVM3D车模透明度";
CM_ BO_ 632 "MMI发给AVM的信号2";
CM_ SG_ 632 MMI_AVMXcoordinate "触摸点横坐标";
CM_ SG_ 632 MMI_AVMYcoordinate "触摸点纵坐标";
CM_ SG_ 632 MMI_AVMXGestureSpeed "手势横向速度";
CM_ SG_ 632 MMI_AVMYGestureSpeed "手势纵向速度";
CM_ SG_ 632 MMI_AVMZoomScaleFactor "缩放系数";
CM_ SG_ 632 MMI_AVMZoomRotaterFactor "旋转系数";
CM_ SG_ 632 MMI_AVMTouchEventType "触摸事件类型";
CM_ BO_ 634 "MMI发给AVM的信号3";
CM_ SG_ 634 MMI_AVM_AVM3D_COMMAND "AVM3D操作指令";
CM_ SG_ 634 MMI_AVM_AVM3DViewModeSwitch "AVM3D视角模式切换";
CM_ SG_ 634 MMI_AVM_AVMEcuEnterExit "AVM_ECU进入/退出";
CM_ SG_ 634 MMI_AVM_AVM3DViewSwitch "AVM3D视角状态";
CM_ BO_ 652 "VSP/氛围灯/CWC/EPS/天窗的控制命令";
CM_ SG_ 652 MMI_VoiceSourceSelect_Cycle "VSP声源循环切换";
CM_ SG_ 652 MMI_VoiceSourceSelect "VSP声源切换";
CM_ SG_ 652 MMI_VSPEnableCommand "VSP开关命令";
CM_ SG_ 652 MMI_AmphereLampCtrl_Colour "氛围灯颜色控制";
CM_ SG_ 652 MMI_AmphereLampCtrl_BrtnsVal "氛围灯亮度值控制（0-100%）";
CM_ SG_ 652 MMI_AmphereLampCtrl_Fleshmode "氛围灯呼吸模式控制";
CM_ SG_ 652 MMI_AmphereLampCtrl_Drivingmode "氛围灯驾驶模式控制";
CM_ SG_ 652 MMI_AmphereLampCtrl_SW "氛围灯开关控制";
CM_ SG_ 652 MMI_PlatfondPellAuto_SW "全景天窗透明度自动开关控制";
CM_ SG_ 652 MMI_PlatfondPellucidity "全景天窗透明度";
CM_ SG_ 652 MMI_PlatfondColorCmd "变色玻璃顶棚颜色控制命令";
CM_ SG_ 652 MMI_AmphereLampIntellisenseSw "氛围灯智能感应开关";
CM_ SG_ 652 MMI_CWC_Cmd "CWC_OPEN_CLS                                                                  对无线充电器的开启与关闭";
CM_ BO_ 666 "MMI发送给主座椅调节及通风、加热命令";
CM_ SG_ 666 MMI_DrvSeatSlideCommand "主驾座椅前后调节指令";
CM_ SG_ 666 MMI_DrvSeatFrontLiftCommand "主驾座椅前升降调节指令";
CM_ SG_ 666 MMI_DrvSeatReclinerCommand "主驾座椅靠背调角调节指令";
CM_ SG_ 666 MMI_DrvSeatAllLiftCommand "主驾座椅全升降调节指令";
CM_ SG_ 666 MMI_DrvSeatSlidePosPercentValid "主驾座椅前后调节设置有效性";
CM_ SG_ 666 MMI_DrvSeatSlidePosPercent "主驾座椅前后调节设置";
CM_ SG_ 666 MMI_DrvSeatFrontLiftPosPercentValid "主驾座椅前升降调节设置有效性";
CM_ SG_ 666 MMI_DrvSeatFrontLiftPosPercent "主驾座椅前升降调节设置";
CM_ SG_ 666 MMI_DrvSeatReclinerPosPercentValid "主驾座椅靠背调角调节设置有效性";
CM_ SG_ 666 MMI_DrvSeatReclinerPosPercent "主驾座椅靠背调角调节设置";
CM_ SG_ 666 MMI_DrvSeatAllLiftPosPercentValid "主驾座椅全升降调节设置有效性";
CM_ SG_ 666 MMI_DrvSeatAllLiftPosPercent "主驾座椅全升降调节设置";
CM_ SG_ 666 MMI_DrvSeatHeatControlCmd "Driver seat heat control command
主驾座椅加热控制命令";
CM_ SG_ 666 MMI_DrvSeatVenControlCmd "Driver seat ventilation control command
主驾座椅通风控制命令";
CM_ SG_ 666 MMI_DrvSeatHandyEntryExitSet "便利进出设置";
CM_ BO_ 668 "MMI发送给副座椅调节及通风、加热命令";
CM_ SG_ 668 MMI_PassSeatSlideCommand "副驾座椅前后调节指令";
CM_ SG_ 668 MMI_PassSeatFrontLiftCommand "副驾座椅前升降调节指令";
CM_ SG_ 668 MMI_PassSeatReclinerCommand "副驾座椅靠背调角调节指令";
CM_ SG_ 668 MMI_PassSeatAllLiftCommand "副驾座椅全升降调节指令";
CM_ SG_ 668 MMI_PassSeatSlidePosPercentValid "副驾座椅前后调节设置有效性";
CM_ SG_ 668 MMI_PassSeatSlidePosPercent "副驾座椅前后调节设置";
CM_ SG_ 668 MMI_PassSeatFrontLiftPosPercentValid "副驾座椅前升降调节设置有效性";
CM_ SG_ 668 MMI_PassSeatFrontLiftPosPercent "副驾座椅前升降调节设置";
CM_ SG_ 668 MMI_PassSeatReclinerPosPercentValid "副驾座椅靠背调角调节设置有效性";
CM_ SG_ 668 MMI_PassSeatReclinerPosPercent "副驾座椅靠背调角调节设置";
CM_ SG_ 668 MMI_PassSeatAllLiftPosPercentValid "副驾座椅全升降调节设置有效性";
CM_ SG_ 668 MMI_PassSeatAllLiftPosPercent "副驾座椅全升降调节设置";
CM_ SG_ 668 MMI_PassDrvSeatHeatControlCmd "Pass Driver seat heat control command
副驾座椅加热控制命令";
CM_ SG_ 668 MMI_PassDrvSeatVenControlCmd "Pass seat ventilation control command
副驾座椅通风控制命令";
CM_ BO_ 670 "发送给BCM的控制命令";
CM_ SG_ 670 MMI_HazardLightCmd "对双闪灯的控制命令";
CM_ SG_ 670 MMI_BCMLightCmd "对小灯的控制命令";
CM_ SG_ 670 MMI_TailgateCmd "对尾门的控制命令";
CM_ SG_ 670 MMI_RearViewCmd "对后视镜的控制命令";
CM_ SG_ 670 MMI_DoorLockCmd "对车门门锁的控制命令";
CM_ SG_ 670 MMI_LowBeamLightCmd "对近光灯的控制命令";
CM_ SG_ 670 MMI_HighBeamLightCmd "对远光灯的控制命令";
CM_ SG_ 670 MMI_FoglightCmd "发送给雾灯的控制命令";
CM_ SG_ 670 MMI_WiperCmd "发送给雨刮的控制命令";
CM_ SG_ 670 MMI_FronLeftDoorWindowCmd "主车窗的控制命令";
CM_ SG_ 670 MMI_FronRightDoorWindowCmd "副车窗的控制命令";
CM_ SG_ 670 MMI_RearLeftDoorWindowCmd "左后车窗的控制命令";
CM_ SG_ 670 MMI_FourDoorWindowCmd "四门车窗的控制命令";
CM_ SG_ 670 MMI_FrontDoorWindowCmd "前车窗的控制命令";
CM_ SG_ 670 MMI_AutolightSWCmd "自动大灯开关命令";
CM_ SG_ 670 MMI_RainAutoClsWindowCmd "雨天自动关闭四门车窗";
CM_ SG_ 670 MMI_RearRightDoorWindowCmd "右后车窗的控制命令";
CM_ SG_ 670 MMI_RearViewMirrorSelect "外后视镜选择控制命令(预留)";
CM_ SG_ 670 MMI_RearViewMirrorUpDown "视镜上下调节控制命令(预留)";
CM_ SG_ 670 MMI_RearViewMirrorLeftRight "视镜左右调节控制命令(预留)";
CM_ SG_ 670 MMI_LockVehicleWarmingTip "锁车提醒方式";
CM_ SG_ 670 MMI_UnlockVehicleOpenCourtesyLampSW "解锁车辆点亮迎宾灯开关";
CM_ SG_ 670 MMI_AccLampSet "伴我回家灯设置";
CM_ SG_ 670 MMI_RearViewMirrorAutoFoldFuc "后视镜自动折叠功能";
CM_ BO_ 792 "MMI发给AVM的信号4";
CM_ SG_ 792 MMI_LicensePlate_ProvinceName "Car License Plate Province
车牌号-省";
CM_ SG_ 792 MMI_LicensePlate_Num1 "Car License Plate Number 1
车牌号-数字号1";
CM_ SG_ 792 MMI_LicensePlate_Num2 "Car License Plate Number 2
车牌号-数字号2";
CM_ SG_ 792 MMI_LicensePlate_Num3 "Car License Plate Number 3
车牌号-数字号3";
CM_ SG_ 792 MMI_LicensePlate_Num4 "Car License Plate Number 4
车牌号-数字号4";
CM_ SG_ 792 MMI_LicensePlate_Num5 "Car License Plate Number 5
车牌号-数字号5";
CM_ SG_ 792 MMI_LicensePlate_Num6 "Car License Plate Number6
车牌号-数字号6";
CM_ SG_ 792 MMI_LicensePlate_Num7 "Car License Plate Number 7
车牌号-数字号7";
CM_ BO_ 390 "AVM发给MMI的信号2(预留)";
CM_ SG_ 390 AVM_BSDLeftWaringSeverity "BSD左侧报警严重度(预留)";
CM_ SG_ 390 AVM_BSDLeftWaringValid "BSD左侧报警有效(预留)";
CM_ SG_ 390 AVM_BSDRightWaringSeverity "BSD右侧报警严重度(预留)";
CM_ SG_ 390 AVM_BSDRightWaringValid "BSD右侧报警有效(预留)";
CM_ SG_ 390 AVM_BSDStatus "BSD状态(预留)";
CM_ SG_ 390 AVM_BSDStatusValid "BSD状态位是否有效(预留)";
CM_ BO_ 392 "AVM发给MMI的信号1";
CM_ SG_ 392 AVM_MMI_ConnectStatus "AVM  connect status
AVM  与MMI连接状态";
CM_ SG_ 392 AVM_MMI_EcuStatus "Signal from AVM to indicate ECU status 
AVM ECU状态(0xF: invalid/提示用户AVM_ECU状态异常)";
CM_ SG_ 392 AVM_MMI_VideoOutputStatus "AVM Ecu Video output status
AVM Ecu视频输出状态(0x3: invalid/显示MMI画面)";
CM_ SG_ 392 AVM_MMI_AVM3DViewModeStatus "AVM3D View Mode Status";
CM_ SG_ 392 AVM_MMI_AVM3DViewSwitch "AVM3D视角状态";
CM_ BO_ 636 "AVM发给MMI的信号5";
CM_ SG_ 636 AVM_MMI_LanguageSet "语言设置";
CM_ SG_ 636 AVM_MMI_AVM3DDynTrajSet "AVM3D动态轨迹线设置";
CM_ SG_ 636 AVM_MMI_AVM3DExitDelaySet "AVM3D退出延迟设置";
CM_ SG_ 636 AVM_MMI_AVM3DTurnLightSet "AVM3D转向灯随动设置";
CM_ SG_ 636 AVM_MMI_AVM3DBlindFillSet "AVM3D车底盲区填充设置";
CM_ SG_ 636 AVM_MMI_BSDFunction "BSD功能是否开启";
CM_ SG_ 636 AVM_MMI_OTFunction "OTF功能是否开启";
CM_ SG_ 636 AVM_MMI_AVM3DCarIconColor "AVM车模颜色选择";
CM_ SG_ 636 AVM_MMI_AVM3DCarIconTransparent "AVM3D车模透明度";
CM_ BO_ 778 "AVM发给MMI的信号6";
CM_ SG_ 778 AVM_LicensePlate_ProvinceName "Car License Plate Province
车牌号-省";
CM_ SG_ 778 AVM_LicensePlate_Num1 "Car License Plate Number 1
车牌号-数字号1";
CM_ SG_ 778 AVM_LicensePlate_Num2 "Car License Plate Number 2
车牌号-数字号2";
CM_ SG_ 778 AVM_LicensePlate_Num3 "Car License Plate Number 3
车牌号-数字号3";
CM_ SG_ 778 AVM_LicensePlate_Num4 "Car License Plate Number 4
车牌号-数字号4";
CM_ SG_ 778 AVM_LicensePlate_Num5 "Car License Plate Number 5
车牌号-数字号5";
CM_ SG_ 778 AVM_LicensePlate_Num6 "Car License Plate Number6
车牌号-数字号6";
CM_ SG_ 778 AVM_LicensePlate_Num7 "Car License Plate Number 7
车牌号-数字号7";
CM_ BO_ 788 "AVM发给MMI的信号3";
CM_ SG_ 788 AVM_MCU_Version "Signal from AVM to indicate MCU version
标识MCU版本";
CM_ SG_ 788 AVM_BSP_Version "Signal from AVM to indicate BSP version
标识BSP版本";
CM_ BO_ 790 "AVM发给MMI的信号4";
CM_ SG_ 790 AVM_ZADAS_Version "Signal from AVM to indicate Zadas version
标识ZADAS版本";
CM_ SG_ 790 Avm3d_licenseStatus "Signal from AVM to indicate if contained avm3d license
是否包含AVM 3D授权";
CM_ SG_ 790 BSD_licenseStatus "Signal from AVM to indicate if contained BSD license
是否包含BSD授权";
CM_ SG_ 586 ACU_AirBagSysWrnLmpCmd "Airbag system warning lamp request";
CM_ SG_ 586 ACU_Crashinfo "crash signal
无碰撞时100ms 有碰撞时20ms连续发10次";
CM_ SG_ 586 ACU_24Ah_RollingCounter "循环计数器";
CM_ SG_ 586 ACU_24Ah_CheckSUM "校检和 checksum = (Byte0+Byte1 …+ Byte6) XOR 0xFF";
CM_ SG_ 352 ACC_Set_Speed "driver selected cruise speed
驾驶员选择的巡航速度";
CM_ SG_ 352 ACC_Torque_Request_Status "indicate if there is a torque request
指示ACC是否有扭矩请求";
CM_ SG_ 352 ACC_Set_Headway "driver selected follow headway
驾驶员选择的跟车距离";
CM_ SG_ 352 ACC_Torque_Request "torque request value(Wheel_Total)
ACC请求的扭矩值(轮端总扭矩)";
CM_ SG_ 352 ACC_Standstill_Request "standstill request
ACC保持车辆静止请求";
CM_ SG_ 352 ACC_Decelerate_Request_Status "indicate if there is a decelerate request
指示ACC是否有减速请求";
CM_ SG_ 352 ACC_Decelerate_Request "decelerate request value
ACC请求的减速值";
CM_ SG_ 352 ADAS_160h_RollingCounter "循环计数器";
CM_ SG_ 352 ADAS_160h_CheckSUM "校检和 checksum = (Byte0+Byte1 …+ Byte6) XOR 0xFF";
CM_ SG_ 354 AEB_EHB_StopReq "AEB to EHB stop request
AEB 停车请求";
CM_ SG_ 354 AEB_Jerk_Request "jerk request
AEB jerk请求";
CM_ SG_ 354 AEB_Prefill_Request "prefill request
AEB制动预充请求";
CM_ SG_ 354 AEB_Decelerate_Request_Status "indicate if there is a decelerate request
指示AEB是否有减速请求";
CM_ SG_ 354 AEB_State "indicate system working state
指示AEB系统状态";
CM_ SG_ 354 FCW_State "indicate system working state
指示FCW工作状态";
CM_ SG_ 354 AEB_Decelerate_Request "decelerate request value
AEB请求的减速值";
CM_ SG_ 354 ADAS_Sensorstatus "Sensor Fault Status
传感器故障状态";
CM_ SG_ 354 HW_Warning_Level "indicate the current warning level
指示HW当前报警等级";
CM_ SG_ 354 FCW_Warning_Level "indicate the current warning level
指示FCW报警等级";
CM_ SG_ 354 ACC_Override_Indicator "Instruct driver to override through throttle
指示驾驶员通过油门超控";
CM_ SG_ 354 ACC_CIPV_Indicator "indicate CIPV detection status
指示最近在径前车状态";
CM_ SG_ 354 ACC_Auto_Cancel "indicate auto cancel 
指示系统自动取消了ACC功能";
CM_ SG_ 354 ACC_Driver_Cancel "indicate driver cancel operation
指示驾驶员取消ACC";
CM_ SG_ 354 ACC_State "indicate system working state
指示ACC系统工作状态";
CM_ SG_ 354 ACC_Go_Indicator "GO' notifier for stop & go function
 stop & go功能的前进指示";
CM_ SG_ 354 ACC_Takeover_Indicator "indicate driver takeover operation
请求驾驶员接管";
CM_ SG_ 354 ADAS_162h_RollingCounter "循环计数器";
CM_ SG_ 354 ADAS_162h_CheckSUM "校检和 checksum = (Byte0+Byte1 …+ Byte6) XOR 0xFF";
CM_ SG_ 356 TSR_State "indicate system working state
指示TSR系统工作状态";
CM_ SG_ 356 DAS_TSR_Main_Switch "Trafic Signal Recognise switch feedback status                  
 交通信号灯识别开关回馈状态";
CM_ SG_ 356 IHC_Mainbeam_Request "turn on or shut down high beam request
请求打开或关闭远光灯";
CM_ SG_ 356 IHC_State "indicate system working state
指示IHC工作状态";
CM_ SG_ 356 LDW_Line_Detect_Status "indicate system lane mark detection status
指示车道线检测状态";
CM_ SG_ 356 LDW_Warning "indicate the current warning direction
指示当前LDW报警等级";
CM_ SG_ 356 LDW_State "indicate system working state
指示LDW工作状态";
CM_ SG_ 356 TSR_Targetspeed_Request "Indicates the current identified speed limit
指示当前识别到的限速值";
CM_ SG_ 356 LKA_Torque_Request_Status "indicate if there is a steering wheel torque request
指示是否有转向扭矩请求";
CM_ SG_ 356 LKA_State "indicate system working state
指示LKA系统状态";
CM_ SG_ 356 LKA_Torque_Request "steering wheel torque request value
LKA系统请求的转向扭矩值";
CM_ SG_ 356 ADAS_164h_RollingCounter "循环计数器";
CM_ SG_ 356 LKA_Takeover_Request "warning when system detect current situation beyond system limit
LKA请求驾驶员接管";
CM_ SG_ 356 LKA_Hands_Off_Warning "warning when hands off detected
驾驶员手离开方向盘警告";
CM_ SG_ 356 DAS_LDW_Main_Switch "Lan Departure Warming switch feedback status                   道路偏离预警开关回馈状态";
CM_ SG_ 356 DAS_LDW_Sensitivity "Lan Departure Warming Sensitivity feedback status                                                             道路偏离预警灵敏度回馈状态";
CM_ SG_ 356 DAS_FCW_Main_Switch "Forward Collision switch feedback status                   前碰预警开关回馈状态";
CM_ SG_ 356 DAS_FCW_Sensitivity "Forward Collision sensitivity feedback status                   前碰预警开关灵敏度回馈状态";
CM_ SG_ 356 DAS_AEB_Main_Switch "Auto Emergency Break switch feedback status                   自动紧急制动主开关回馈状态";
CM_ SG_ 356 DAS_IHC_Main_Switch "Intergrade HeadLingt Control Main switch feedback status                                                                      自动大灯开关回馈状态";
CM_ SG_ 356 ADAS_164h_CheckSUM "校检和 checksum = (Byte0+Byte1 …+ Byte6) XOR 0xFF";
CM_ BO_ 384 "APA与MMI交互信号1";
CM_ SG_ 384 APA_MMI_ConnectStatus "APA connect status
APA与MMI连接状态";
CM_ SG_ 384 APA_MMI_EcuStatus "Signal from APA to indicate ECU status 
APA ECU状态";
CM_ SG_ 384 APA_MMI_VideoOutputStatus "APA Ecu Video output status
APA Ecu视频输出状态";
CM_ SG_ 384 APA_MMI_3DViewModeStatus "APA 3D View Mode Status";
CM_ SG_ 384 APA_MMI_AVM3DViewSwitch "APA3D视角状态";
CM_ BO_ 386 "APA与MMI交互信号2(预留)";
CM_ SG_ 386 APA_BSDLeftWaringSeverity "BSD左侧报警严重度(预留)";
CM_ SG_ 386 APA_BSDLeftWaringValid "BSD左侧报警有效(预留)";
CM_ SG_ 386 APA_BSDRightWaringSeverity "BSD右侧报警严重度(预留)";
CM_ SG_ 386 APA_BSDRightWaringValid "BSD右侧报警有效(预留)";
CM_ SG_ 386 APA_BSDStatus "BSD状态(预留)";
CM_ SG_ 386 APA_BSDStatusValid "BSD状态位是否有效(预留)";
CM_ BO_ 387 "APA后泊车雷达信号 APA与MMI交互信号3";
CM_ SG_ 387 PAS_APA_DistanceLR_RL "obstancle detection Distance by rear left radar(long distance)
左后长距离雷达探测障碍物距离值";
CM_ SG_ 387 PAS_APA_DistanceLR_RR "obstancle detection Distance by rear right radar(long distance)
右后长距离雷达探测障碍物距离值";
CM_ SG_ 387 PAS_APA_DistanceSR_RL "obstancle detection Distance by rear left radar(short distance)
左后短距离雷达探测障碍物距离值";
CM_ SG_ 387 PAS_APA_DistanceSR_RML "obstancle detection Distance by rear middle left radar(short distance)
左中后短距离雷达探测障碍物距离值";
CM_ SG_ 387 PAS_APA_DistanceSR_RMR "obstancle detection Distance by rear middle right radar(short distance)
右中后短距离雷达探测障碍物距离值";
CM_ SG_ 387 PAS_APA_DistanceSR_RR "obstancle detection Distance by rear right radar(short distance)
右后短距离雷达探测障碍物距离值";
CM_ SG_ 387 APA_183hh_MessageCounter "counter
计数器";
CM_ SG_ 387 APA_183hh_MessageChecksum "校检和 checksum = (Byte0+Byte1 …+ Byte6) XOR 0xFF";
CM_ BO_ 388 "APA前泊车雷达信号 APA与MMI交互信号4";
CM_ SG_ 388 PAS_APA_DistanceLR_FL "obstancle detection Distance by front left radar(long distance)
左前长距离雷达探测障碍物距离值";
CM_ SG_ 388 PAS_APA_DistanceLR_FR "obstancle detection Distance by front right radar(long distance)
右前长距离雷达探测障碍物距离值";
CM_ SG_ 388 PAS_APA_DistanceSR_FL "obstancle detection Distance by front left radar(short distance)
左前短距离雷达探测障碍物距离值";
CM_ SG_ 388 PAS_APA_DistanceSR_FML "obstancle detection Distance by front middle left radar(short distance)
左中前短距离雷达探测障碍物距离值";
CM_ SG_ 388 PAS_APA_DistanceSR_FMR "obstancle detection Distance by front middle right radar(short distance)
右中前短距离雷达探测障碍物距离值";
CM_ SG_ 388 PAS_APA_DistanceSR_FR "obstancle detection Distance by front right radar(short distance)
右前短距离雷达探测障碍物距离值";
CM_ SG_ 388 APA_184hh_MessageCounter "counter
计数器";
CM_ SG_ 388 APA_184hh_MessageChecksum "校检和 checksum = (Byte0+Byte1 …+ Byte6) XOR 0xFF";
CM_ BO_ 784 "APA与MMI交互信号3";
CM_ SG_ 784 APA_AVM_MCU_Version "Signal from AVM to indicate MCU version
标识MCU版本 eg.0x030008: 3.0.8";
CM_ SG_ 784 APA_AVM_BSP_Version "Signal from AVM to indicate BSP version
标识BSP版本 eg.0x030008: 3.0.8";
CM_ BO_ 786 "APA与MMI交互信号4";
CM_ SG_ 786 APA_AVM_ZADAS_Version "Signal from AVM to indicate Zadas version
标识ZADAS版本 eg.0x030008: 3.0.8";
CM_ SG_ 786 APA_Avm3d_licenseStatus "Signal from AVM to indicate if contained avm3d license
是否包含AVM 3D授权";
CM_ SG_ 786 APA_BSD_licenseStatus "Signal from AVM to indicate if contained BSD license
是否包含BSD授权";
CM_ SG_ 512 BMS_Sys_SumVoltage "Total battery voltage
电池总电压";
CM_ SG_ 512 BMS_Sys_SumCurrent "Total Battery Current
电池总电流";
CM_ SG_ 512 BMS_battery_outside_Voltage "Battery pack External Total pressure
That is, the busbar voltage
电池包外部总压
即母线电压";
CM_ SG_ 514 BMS_Relay_POS "Relay Status-discharge relays
继电器状态-放电继电器";
CM_ SG_ 514 BMS_Boot_Detection "Boot detection
开机检测";
CM_ SG_ 514 BMS_A "A+ singnal
A+信号";
CM_ SG_ 514 BMS_Relay_HEAT "Relay Status-Heating
继电器状态-加热（预留）";
CM_ SG_ 514 BMS_ChrgAllowance "Charging allowed
充电允许";
CM_ SG_ 514 BMS_Sys_ChgorDisChrgSts "Battery pack charging and discharging status
电池包充放电状态";
CM_ SG_ 514 BMS_FastChrgSts "BMS FastCharge Status
BMS快充充电状态";
CM_ SG_ 514 BMS_SlowChrgSts "BMS SlowCharge Status
BMS慢充充电状态";
CM_ SG_ 514 BMS_Battery_Coulomb_Satus "Battery capacity Status
电池容量状态";
CM_ SG_ 514 BMS_ChrgCouplesSt "Fast charge connection status
快充连接状态";
CM_ SG_ 514 BMS_req_ConnectChargeRelay "Request Connect Charge Relay
请求吸和充电继电器";
CM_ SG_ 514 BMS_DischgAllow "BMS discharge allows
BMS放电允许";
CM_ SG_ 514 BMS_request_subscribe_allow "Reservation charging allowed
预约充电允许";
CM_ SG_ 514 BMS_CC2 "CC2
直充连接信号";
CM_ SG_ 514 BMS_PauseContinueChrgStus "Pause/Continue charge status feedback
请求暂停/继续充电状态反馈";
CM_ SG_ 514 BMS_AllowedChrgMaxPower "Max Allowed Charge Power
最大允许充电电量";
CM_ SG_ 518 BMS_battery_WaterTemp_in "the temperature of inlet water
电池包进水口冷却液温度";
CM_ SG_ 518 BMS_battery_WaterTemp_out "the temperature of inlet water
电池包出水口冷却液温度";
CM_ SG_ 518 BMS_battery_WaterTemp_average "the average water temp of Battery
电池包冷却液平均温度";
CM_ SG_ 518 BMS_FlowRateReq "flow rate request to AC
电池热管理对流量的需求";
CM_ SG_ 518 BMS_InletWaterTempTarget "The Target temperature request
电池对冷却回路进水口目标温度请求";
CM_ SG_ 518 BMS_ThermalManageReq "BMS request AC to cooling or heating
热管理请求";
CM_ SG_ 518 BMS_WaterTempChangeRateReq "water temperature change rate request
电池对冷却回路水温变化速率需求";
CM_ SG_ 524 BMS_Powertrain_System_fault "Battery system failure
电池系统故障";
CM_ SG_ 524 BMS_cell_Voltage_low "Battery monomer power down fault
电池单体电压低故障";
CM_ SG_ 524 BMS_cell_Voltage_High "High voltage fault of battery monomer
电池单体电压高故障";
CM_ SG_ 524 BMS_Battery_LowTemp_warning "Battery pack Temperature Low fault
电池组温度低故障";
CM_ SG_ 524 BMS_Battery_HighTemp_warning "Battery pack Temperature High fault
电池组温度高故障";
CM_ SG_ 524 BMS_SOCHigh_Warning "Soc High Alarm
SOC高报警";
CM_ SG_ 524 BMS_SOCLow_Warning "Soc Low Alarm
SOC低报警";
CM_ SG_ 524 BMS_Battery_SumVoltage_High "High total voltage of battery pack failure
电池包总电压高故障";
CM_ SG_ 524 BMS_Battery_SumVoltage_Low "Battery pack total power down fault
电池包总电压低故障";
CM_ SG_ 524 BMS_HVBatCellDiffFalt "Battery Monomer Consistency Difference failure
电池单体一致性差故障";
CM_ SG_ 524 BMS_Err_OverVoltageFault "Battery pack monomer over-voltage failure
电池包单体过压故障";
CM_ SG_ 524 BMS_Battery_charge_Fault "Battery pack Charging failure
电池组充电故障";
CM_ SG_ 524 BMS_SOCJump_Warning "Soc Jump Alarm
SOC跳变报警";
CM_ SG_ 524 BMS_Err_CellT_Low "Low fault of monomer temperature
单体温度过低故障";
CM_ SG_ 524 BMS_Err_CellT_High "Excessive fault of monomer temperature
单体温度过高故障";
CM_ SG_ 524 BMS_BatNotMatchFlt "Battery mismatch Alarm
电池不匹配报警";
CM_ SG_ 524 BMS_Err_ISO_LOW "Insulation Low fault
绝缘低故障";
CM_ SG_ 524 BMS_Err_ChgCurrent_High "Charging current is too large fault
充电电流过大故障";
CM_ SG_ 524 BMS_Err_DchCurrent_High "Too large discharge current failure
放电电流过大故障";
CM_ SG_ 524 BMS_Err_DtT_High "The temperature difference is too big fault
温差过大故障";
CM_ SG_ 524 ThermalManage_System_fault "Thermal manage system fault
热管理系统故障";
CM_ SG_ 524 BMS_Err_comunicacion "BMS Communication failure
BMS通讯故障";
CM_ SG_ 524 BMS_Err_InterLock "BMS Interlock fault
BMS互锁故障";
CM_ SG_ 524 BMS_Circuit_Protection "Short Circuit protection
短路保护";
CM_ SG_ 524 BMS_FeedFault "BMS feed fault
蓄电池馈电故障";
CM_ SG_ 524 BMS_TotalErrNumber "Total number of BMS faults
BMS故障总个数";
CM_ SG_ 528 BMS_Sys_MinCellV "Minimum monomer voltage
最小单体电压";
CM_ SG_ 528 BMS_Sys_MaxCellV "Maximum electrical voltage
最大电体电压";
CM_ SG_ 528 BMS_Sys_MinCellV_No "Minimum monomer voltage position
最小单体电压位置";
CM_ SG_ 528 BMS_Sys_MaxCellV_No "Maximum electrical voltage position
最大电体电压位置";
BA_DEF_ BO_  "NmMessage" ENUM "No","Yes";
BA_DEF_ BO_  "DiagState" ENUM  "No","Yes";
BA_DEF_ BO_  "DiagResponse" ENUM  "No","Yes";
BA_DEF_ BO_  "GenMsgSendType" ENUM  "NoSendType","Cycle","Event","IfActive","CE","CA";
BA_DEF_ BO_  "GenMsgCycleTime" INT 0 0;
BA_DEF_ SG_  "GenSigSendType" ENUM  "NoSendType","Cycle","OnWrite","OnWriteWithRepetition","OnChange","OnChangeWithRepetition","IfActive","IfActiveWithRepetition";
BA_DEF_ SG_  "GenSigStartValue" INT 0 0;
BA_DEF_ SG_  "GenSigInvalidValue" STRING;
BA_DEF_ BO_  "GenMsgCycleTimeFast" INT 0 0;
BA_DEF_ BO_  "GenMsgNrOfRepetition" INT 0 0;
BA_DEF_ BO_  "GenMsgDelayTime" INT 0 0;
BA_DEF_  "DBName" STRING ;
BA_DEF_ BU_  "NodeLayerModules" STRING ;
BA_DEF_ BU_  "NmNode" ENUM  "Not","Yes";
BA_DEF_  "NmBaseAddress" HEX 0 2047;
BA_DEF_  "NmMessageCount" INT 0 255;
BA_DEF_  "BusType" STRING ;

BA_DEF_DEF_  "NmMessage" "No";
BA_DEF_DEF_  "DiagState" "No";
BA_DEF_DEF_  "DiagResponse" "No";
BA_DEF_DEF_  "GenMsgSendType" "Cycle";
BA_DEF_DEF_  "GenMsgCycleTime" 0;
BA_DEF_DEF_  "GenSigSendType" "Cycle";
BA_DEF_DEF_  "GenSigStartValue" 0;
BA_DEF_DEF_  "GenSigInvalidValue" "";
BA_DEF_DEF_  "GenMsgCycleTimeFast" 0;
BA_DEF_DEF_  "GenMsgNrOfRepetition" 0;
BA_DEF_DEF_  "GenMsgDelayTime" 0;
BA_DEF_DEF_  "DBName" "";
BA_DEF_DEF_  "NodeLayerModules" "oseknm01.dll,osek_tp.dll,CANoeILNLVector.dll";
BA_DEF_DEF_  "NmNode" "Not";
BA_DEF_DEF_  "NmBaseAddress" 1024;
BA_DEF_DEF_  "NmMessageCount" 128;
BA_DEF_DEF_  "BusType" "CAN";
BA_ "DBName" "ICU_MMI";
BA_ "DiagState" BO_ 1960 1 ;
BA_ "DiagResponse" BO_ 1960 1 ;
BA_ "GenMsgSendType" BO_ 1960 2;
BA_ "GenSigSendType" SG_ 1960 IC_Diagnostic_Data_response0 2;
BA_ "GenSigSendType" SG_ 1960 IC_Diagnostic_Data_response1 2;
BA_ "GenSigSendType" SG_ 1960 IC_Diagnostic_Data_response2 2;
BA_ "GenSigSendType" SG_ 1960 IC_Diagnostic_Data_response3 2;
BA_ "GenSigSendType" SG_ 1960 IC_Diagnostic_Data_response4 2;
BA_ "GenSigSendType" SG_ 1960 IC_Diagnostic_Data_response5 2;
BA_ "GenSigSendType" SG_ 1960 IC_Diagnostic_Data_response6 2;
BA_ "GenSigSendType" SG_ 1960 IC_Diagnostic_Data_response7 2;
BA_ "NmMessage" BO_ 1030 1 ;
BA_ "GenMsgSendType" BO_ 1030 2;
BA_ "GenSigSendType" SG_ 1030 IC_NM_Message0 2;
BA_ "GenSigSendType" SG_ 1030 IC_NM_Message1 2;
BA_ "GenSigSendType" SG_ 1030 IC_NM_Message2 2;
BA_ "GenSigSendType" SG_ 1030 IC_NM_Message3 2;
BA_ "GenSigSendType" SG_ 1030 IC_NM_Message4 2;
BA_ "GenSigSendType" SG_ 1030 IC_NM_Message5 2;
BA_ "GenSigSendType" SG_ 1030 IC_NM_Message6 2;
BA_ "GenSigSendType" SG_ 1030 IC_NM_Message7 2;
BA_ "GenMsgCycleTime" BO_ 604 100 ;
BA_ "GenSigInvalidValue" SG_ 604 MMI_AVM_ConnectStatus "0xf";
BA_ "GenSigInvalidValue" SG_ 604 ICU_TotalOdometer "0xFFFFF";
BA_ "GenMsgCycleTime" BO_ 620 100 ;
BA_ "GenSigInvalidValue" SG_ 620 PAS_PDC_Distance_RR "0xF";
BA_ "GenSigInvalidValue" SG_ 620 PAS_PDC_Distance_RL "0xF";
BA_ "GenSigInvalidValue" SG_ 620 PAS_PDC_Distance_RRM "0xF";
BA_ "GenSigInvalidValue" SG_ 620 PAS_PDC_Distance_RLM "0xF";
BA_ "GenMsgSendType" BO_ 648 2;
BA_ "GenMsgCycleTimeFast" BO_ 648 100 ;
BA_ "GenMsgNrOfRepetition" BO_ 648 3 ;
BA_ "GenSigSendType" SG_ 648 MMI_ACAUTOReqValid 3;
BA_ "GenSigInvalidValue" SG_ 648 MMI_ACAUTOReqValid "0x0";
BA_ "GenSigSendType" SG_ 648 MMI_ACAUTOReq 3;
BA_ "GenSigSendType" SG_ 648 MMI_ACCompressorReqValid 3;
BA_ "GenSigInvalidValue" SG_ 648 MMI_ACCompressorReqValid "0x0";
BA_ "GenSigSendType" SG_ 648 MMI_ACCompressorReq 3;
BA_ "GenSigSendType" SG_ 648 MMI_ACMaxReqValid 3;
BA_ "GenSigInvalidValue" SG_ 648 MMI_ACMaxReqValid "0x0";
BA_ "GenSigSendType" SG_ 648 MMI_ACMaxReq 3;
BA_ "GenSigSendType" SG_ 648 MMI_ACOFFReqValid 3;
BA_ "GenSigInvalidValue" SG_ 648 MMI_ACOFFReqValid "0x0";
BA_ "GenSigSendType" SG_ 648 MMI_ACOFFReq 3;
BA_ "GenSigSendType" SG_ 648 MMI_InsideTempIncDecReqValid 3;
BA_ "GenSigInvalidValue" SG_ 648 MMI_InsideTempIncDecReqValid "0x0";
BA_ "GenSigSendType" SG_ 648 MMI_InsideTempIncDecReq 3;
BA_ "GenSigSendType" SG_ 648 MMI_BLOWERReqValid 3;
BA_ "GenSigInvalidValue" SG_ 648 MMI_BLOWERReqValid "0x0";
BA_ "GenSigSendType" SG_ 648 MMI_BLOWERReq 3;
BA_ "GenSigSendType" SG_ 648 MMI_ACBlowModeReqValid 3;
BA_ "GenSigInvalidValue" SG_ 648 MMI_ACBlowModeReqValid "0x0";
BA_ "GenSigSendType" SG_ 648 MMI_ACBlowModeReq 3;
BA_ "GenSigSendType" SG_ 648 MMI_CirculatingModeSetValid 3;
BA_ "GenSigInvalidValue" SG_ 648 MMI_CirculatingModeSetValid "0x0";
BA_ "GenSigSendType" SG_ 648 MMI_CirculatingModeSet 3;
BA_ "GenSigSendType" SG_ 648 MMI_InsideTempSetValid 3;
BA_ "GenSigInvalidValue" SG_ 648 MMI_InsideTempSetValid "0x0";
BA_ "GenSigSendType" SG_ 648 MMI_InsideTempSet 3;
BA_ "GenSigSendType" SG_ 648 MMI_SeatHeatReq_right 3;
BA_ "GenSigInvalidValue" SG_ 648 MMI_SeatHeatReq_right "0x0";
BA_ "GenSigSendType" SG_ 648 MMI_SeatHeatReq_left 3;
BA_ "GenSigInvalidValue" SG_ 648 MMI_SeatHeatReq_left "0x0";
BA_ "GenSigSendType" SG_ 648 MMI_BLOWERGearSetValid 3;
BA_ "GenSigInvalidValue" SG_ 648 MMI_BLOWERGearSetValid "0x0";
BA_ "GenSigSendType" SG_ 648 MMI_BLOWERGearSet 3;
BA_ "GenSigSendType" SG_ 648 MMI_FrontDeforstReq 3;
BA_ "GenSigInvalidValue" SG_ 648 MMI_FrontDeforstReq "0x0";
BA_ "GenSigSendType" SG_ 648 MMI_RearDeforstReq 3;
BA_ "GenSigInvalidValue" SG_ 648 MMI_RearDeforstReq "0x0";
BA_ "GenSigSendType" SG_ 648 MMI_EnergyRecoveryContr 3;
BA_ "GenSigInvalidValue" SG_ 648 MMI_EnergyRecoveryContr "0x0";
BA_ "GenSigSendType" SG_ 648 MMI_RearViewMirrorHeatReq 3;
BA_ "GenSigInvalidValue" SG_ 648 MMI_RearViewMirrorHeatReq "0x0";
BA_ "GenSigSendType" SG_ 648 MMI_AnionNegativeIonReq 3;
BA_ "GenSigInvalidValue" SG_ 648 MMI_AnionNegativeIonReq "0x0";
BA_ "GenMsgSendType" BO_ 370 2;
BA_ "GenMsgCycleTimeFast" BO_ 370 100 ;
BA_ "GenMsgNrOfRepetition" BO_ 370 3 ;
BA_ "GenSigSendType" SG_ 370 MMI_LDW_Main_Switch 3;
BA_ "GenSigSendType" SG_ 370 MMI_LDW_Switch_Available 3;
BA_ "GenSigStartValue" SG_ 370 MMI_LDW_Switch_Available 1;
BA_ "GenSigSendType" SG_ 370 MMI_FCW_Sensitivity 3;
BA_ "GenSigSendType" SG_ 370 MMI_FCW_Main_Switch 3;
BA_ "GenSigSendType" SG_ 370 MMI_FCW_Switch_Available 3;
BA_ "GenSigStartValue" SG_ 370 MMI_FCW_Switch_Available 1;
BA_ "GenSigSendType" SG_ 370 MMI_AEB_Main_Switch 3;
BA_ "GenSigSendType" SG_ 370 MMI_AEB_Switch_Available 3;
BA_ "GenSigStartValue" SG_ 370 MMI_AEB_Switch_Available 1;
BA_ "GenSigSendType" SG_ 370 MMI_TSR_Main_Switch 3;
BA_ "GenSigSendType" SG_ 370 MMI_TSR_Switch_Available 3;
BA_ "GenSigStartValue" SG_ 370 MMI_TSR_Switch_Available 1;
BA_ "GenSigSendType" SG_ 370 MMI_IHC_Main_Switch 3;
BA_ "GenSigSendType" SG_ 370 MMI_IHC_Switch_Available 3;
BA_ "GenSigStartValue" SG_ 370 MMI_IHC_Switch_Available 1;
BA_ "GenSigSendType" SG_ 370 MMI_LDW_Sensitivity 3;
BA_ "GenSigSendType" SG_ 370 MMI_BSD_Main_Switch 3;
BA_ "GenSigSendType" SG_ 370 MMI_BSD_Switch_Available 3;
BA_ "GenSigSendType" SG_ 370 MMI_BSD_Sensitivity 3;
BA_ "GenSigSendType" SG_ 370 MMI_EPS_ModeSwitch 3;
BA_ "GenSigInvalidValue" SG_ 370 MMI_EPS_ModeSwitch "0x0";
BA_ "GenSigSendType" SG_ 370 MMI_PauseContinueChrgRQ 3;
BA_ "GenSigInvalidValue" SG_ 370 MMI_PauseContinueChrgRQ "0x0";
BA_ "GenSigSendType" SG_ 370 MMI_WCBS_CstSwitch 3;
BA_ "GenSigSendType" SG_ 370 MMI_ChrgMaxPower 3;
BA_ "GenSigInvalidValue" SG_ 370 MMI_ChrgMaxPower "0x7F";
BA_ "GenSigSendType" SG_ 370 MMI_ChrgCurrentSet 3;
BA_ "GenSigInvalidValue" SG_ 370 MMI_ChrgCurrentSet "0x0";
BA_ "GenMsgSendType" BO_ 630 2;
BA_ "GenMsgCycleTimeFast" BO_ 630 20 ;
BA_ "GenMsgNrOfRepetition" BO_ 630 3 ;
BA_ "GenSigInvalidValue" SG_ 630 MMI_AVM_LanguageSet "0xf";
BA_ "GenSigInvalidValue" SG_ 630 MMI_AVM_AVM3DDynTrajSet "0x3";
BA_ "GenSigInvalidValue" SG_ 630 MMI_AVM_AVM3DExitDelaySet "0x3";
BA_ "GenSigInvalidValue" SG_ 630 MMI_AVM_AVM3DTurnLightSet "0x3";
BA_ "GenSigInvalidValue" SG_ 630 MMI_AVM_AVM3DBlindFillSet "0x3";
BA_ "GenSigInvalidValue" SG_ 630 MMI_AVM_BSDFunction "0x3";
BA_ "GenSigInvalidValue" SG_ 630 MMI_AVM_OTFunction "0x3";
BA_ "GenSigInvalidValue" SG_ 630 MMI_AVM_AVM3DCarIconColor "0xf";
BA_ "GenSigInvalidValue" SG_ 630 MMI_AVM_AVM3DCarIconTransparenValid "0x3";
BA_ "GenSigInvalidValue" SG_ 630 MMI_AVM_VideoOutputStatus "0xf";
BA_ "GenSigInvalidValue" SG_ 630 MMI_AVM_AVM3DCarIconTransparent "0xFF";
BA_ "GenMsgSendType" BO_ 632 2;
BA_ "GenMsgCycleTimeFast" BO_ 632 20 ;
BA_ "GenMsgNrOfRepetition" BO_ 632 3 ;
BA_ "GenSigSendType" SG_ 632 MMI_AVMXcoordinate 3;
BA_ "GenSigInvalidValue" SG_ 632 MMI_AVMXcoordinate "0xFFF";
BA_ "GenSigSendType" SG_ 632 MMI_AVMYcoordinate 3;
BA_ "GenSigInvalidValue" SG_ 632 MMI_AVMYcoordinate "0x3FF";
BA_ "GenSigSendType" SG_ 632 MMI_AVMXGestureSpeed 3;
BA_ "GenSigInvalidValue" SG_ 632 MMI_AVMXGestureSpeed "0xFF";
BA_ "GenSigSendType" SG_ 632 MMI_AVMYGestureSpeed 3;
BA_ "GenSigInvalidValue" SG_ 632 MMI_AVMYGestureSpeed "0xFF";
BA_ "GenSigSendType" SG_ 632 MMI_AVMZoomScaleFactor 3;
BA_ "GenSigInvalidValue" SG_ 632 MMI_AVMZoomScaleFactor "0xFF";
BA_ "GenSigSendType" SG_ 632 MMI_AVMZoomRotaterFactor 3;
BA_ "GenSigInvalidValue" SG_ 632 MMI_AVMZoomRotaterFactor "0xFF";
BA_ "GenSigSendType" SG_ 632 MMI_AVMTouchEventType 3;
BA_ "GenSigInvalidValue" SG_ 632 MMI_AVMTouchEventType "0x0";
BA_ "GenMsgSendType" BO_ 634 2;
BA_ "GenMsgCycleTimeFast" BO_ 634 20 ;
BA_ "GenMsgNrOfRepetition" BO_ 634 3 ;
BA_ "GenSigSendType" SG_ 634 MMI_AVM_AVM3D_COMMAND 3;
BA_ "GenSigInvalidValue" SG_ 634 MMI_AVM_AVM3D_COMMAND "0xf";
BA_ "GenSigSendType" SG_ 634 MMI_AVM_AVM3DViewModeSwitch 3;
BA_ "GenSigInvalidValue" SG_ 634 MMI_AVM_AVM3DViewModeSwitch "0xf";
BA_ "GenSigSendType" SG_ 634 MMI_AVM_AVMEcuEnterExit 3;
BA_ "GenSigSendType" SG_ 634 MMI_AVM_AVM3DViewSwitch 3;
BA_ "GenMsgSendType" BO_ 652 2;
BA_ "GenMsgCycleTimeFast" BO_ 652 100 ;
BA_ "GenMsgNrOfRepetition" BO_ 652 3 ;
BA_ "GenSigSendType" SG_ 652 MMI_VoiceSourceSelect_Cycle 3;
BA_ "GenSigInvalidValue" SG_ 652 MMI_VoiceSourceSelect_Cycle "0x0";
BA_ "GenSigSendType" SG_ 652 MMI_VoiceSourceSelect 3;
BA_ "GenSigInvalidValue" SG_ 652 MMI_VoiceSourceSelect "0x0";
BA_ "GenSigSendType" SG_ 652 MMI_VSPEnableCommand 3;
BA_ "GenSigInvalidValue" SG_ 652 MMI_VSPEnableCommand "0x0";
BA_ "GenSigSendType" SG_ 652 MMI_AmphereLampCtrl_Colour 3;
BA_ "GenSigSendType" SG_ 652 MMI_AmphereLampCtrl_BrtnsVal 3;
BA_ "GenSigStartValue" SG_ 652 MMI_AmphereLampCtrl_BrtnsVal 255;
BA_ "GenSigInvalidValue" SG_ 652 MMI_AmphereLampCtrl_BrtnsVal "0xFF";
BA_ "GenSigSendType" SG_ 652 MMI_AmphereLampCtrl_Fleshmode 3;
BA_ "GenSigInvalidValue" SG_ 652 MMI_AmphereLampCtrl_Fleshmode "0x0";
BA_ "GenSigSendType" SG_ 652 MMI_AmphereLampCtrl_Drivingmode 3;
BA_ "GenSigInvalidValue" SG_ 652 MMI_AmphereLampCtrl_Drivingmode "0x0";
BA_ "GenSigSendType" SG_ 652 MMI_AmphereLampCtrl_SW 3;
BA_ "GenSigInvalidValue" SG_ 652 MMI_AmphereLampCtrl_SW "0x0";
BA_ "GenSigSendType" SG_ 652 MMI_PlatfondPellAuto_SW 3;
BA_ "GenSigInvalidValue" SG_ 652 MMI_PlatfondPellAuto_SW "0x0";
BA_ "GenSigSendType" SG_ 652 MMI_PlatfondPellucidity 3;
BA_ "GenSigInvalidValue" SG_ 652 MMI_PlatfondPellucidity "0x7f";
BA_ "GenSigSendType" SG_ 652 MMI_PlatfondColorCmd 3;
BA_ "GenSigInvalidValue" SG_ 652 MMI_PlatfondColorCmd "0x0";
BA_ "GenSigSendType" SG_ 652 MMI_AmphereLampIntellisenseSw 3;
BA_ "GenSigInvalidValue" SG_ 652 MMI_AmphereLampIntellisenseSw "0x0";
BA_ "GenSigSendType" SG_ 652 MMI_CWC_Cmd 3;
BA_ "GenSigInvalidValue" SG_ 652 MMI_CWC_Cmd "0x0";
BA_ "GenMsgSendType" BO_ 666 2;
BA_ "GenMsgCycleTimeFast" BO_ 666 100 ;
BA_ "GenMsgNrOfRepetition" BO_ 666 3 ;
BA_ "GenSigSendType" SG_ 666 MMI_DrvSeatSlideCommand 3;
BA_ "GenSigInvalidValue" SG_ 666 MMI_DrvSeatSlideCommand "0x0";
BA_ "GenSigSendType" SG_ 666 MMI_DrvSeatFrontLiftCommand 3;
BA_ "GenSigInvalidValue" SG_ 666 MMI_DrvSeatFrontLiftCommand "0x0";
BA_ "GenSigSendType" SG_ 666 MMI_DrvSeatReclinerCommand 3;
BA_ "GenSigInvalidValue" SG_ 666 MMI_DrvSeatReclinerCommand "0x0";
BA_ "GenSigSendType" SG_ 666 MMI_DrvSeatAllLiftCommand 3;
BA_ "GenSigInvalidValue" SG_ 666 MMI_DrvSeatAllLiftCommand "0x0";
BA_ "GenSigSendType" SG_ 666 MMI_DrvSeatSlidePosPercentValid 3;
BA_ "GenSigInvalidValue" SG_ 666 MMI_DrvSeatSlidePosPercentValid "0x0";
BA_ "GenSigSendType" SG_ 666 MMI_DrvSeatSlidePosPercent 3;
BA_ "GenSigStartValue" SG_ 666 MMI_DrvSeatSlidePosPercent 63;
BA_ "GenSigInvalidValue" SG_ 666 MMI_DrvSeatSlidePosPercent "0x3F";
BA_ "GenSigSendType" SG_ 666 MMI_DrvSeatFrontLiftPosPercentValid 3;
BA_ "GenSigInvalidValue" SG_ 666 MMI_DrvSeatFrontLiftPosPercentValid "0x0";
BA_ "GenSigSendType" SG_ 666 MMI_DrvSeatFrontLiftPosPercent 3;
BA_ "GenSigStartValue" SG_ 666 MMI_DrvSeatFrontLiftPosPercent 63;
BA_ "GenSigInvalidValue" SG_ 666 MMI_DrvSeatFrontLiftPosPercent "0x3F";
BA_ "GenSigSendType" SG_ 666 MMI_DrvSeatReclinerPosPercentValid 3;
BA_ "GenSigInvalidValue" SG_ 666 MMI_DrvSeatReclinerPosPercentValid "0x0";
BA_ "GenSigSendType" SG_ 666 MMI_DrvSeatReclinerPosPercent 3;
BA_ "GenSigStartValue" SG_ 666 MMI_DrvSeatReclinerPosPercent 63;
BA_ "GenSigInvalidValue" SG_ 666 MMI_DrvSeatReclinerPosPercent "0x3F";
BA_ "GenSigSendType" SG_ 666 MMI_DrvSeatAllLiftPosPercentValid 3;
BA_ "GenSigInvalidValue" SG_ 666 MMI_DrvSeatAllLiftPosPercentValid "0x0";
BA_ "GenSigSendType" SG_ 666 MMI_DrvSeatAllLiftPosPercent 3;
BA_ "GenSigStartValue" SG_ 666 MMI_DrvSeatAllLiftPosPercent 63;
BA_ "GenSigInvalidValue" SG_ 666 MMI_DrvSeatAllLiftPosPercent "0x3F";
BA_ "GenSigSendType" SG_ 666 MMI_DrvSeatHeatControlCmd 3;
BA_ "GenSigInvalidValue" SG_ 666 MMI_DrvSeatHeatControlCmd "0x0";
BA_ "GenSigSendType" SG_ 666 MMI_DrvSeatVenControlCmd 3;
BA_ "GenSigInvalidValue" SG_ 666 MMI_DrvSeatVenControlCmd "0x0";
BA_ "GenSigSendType" SG_ 666 MMI_DrvSeatHandyEntryExitSet 3;
BA_ "GenSigInvalidValue" SG_ 666 MMI_DrvSeatHandyEntryExitSet "0x0";
BA_ "GenMsgSendType" BO_ 668 2;
BA_ "GenMsgCycleTimeFast" BO_ 668 100 ;
BA_ "GenMsgNrOfRepetition" BO_ 668 3 ;
BA_ "GenSigSendType" SG_ 668 MMI_PassSeatSlideCommand 3;
BA_ "GenSigInvalidValue" SG_ 668 MMI_PassSeatSlideCommand "0x0";
BA_ "GenSigSendType" SG_ 668 MMI_PassSeatFrontLiftCommand 3;
BA_ "GenSigInvalidValue" SG_ 668 MMI_PassSeatFrontLiftCommand "0x0";
BA_ "GenSigSendType" SG_ 668 MMI_PassSeatReclinerCommand 3;
BA_ "GenSigInvalidValue" SG_ 668 MMI_PassSeatReclinerCommand "0x0";
BA_ "GenSigSendType" SG_ 668 MMI_PassSeatAllLiftCommand 3;
BA_ "GenSigInvalidValue" SG_ 668 MMI_PassSeatAllLiftCommand "0x0";
BA_ "GenSigSendType" SG_ 668 MMI_PassSeatSlidePosPercentValid 3;
BA_ "GenSigInvalidValue" SG_ 668 MMI_PassSeatSlidePosPercentValid "0x0";
BA_ "GenSigSendType" SG_ 668 MMI_PassSeatSlidePosPercent 3;
BA_ "GenSigStartValue" SG_ 668 MMI_PassSeatSlidePosPercent 63;
BA_ "GenSigInvalidValue" SG_ 668 MMI_PassSeatSlidePosPercent "0x3F";
BA_ "GenSigSendType" SG_ 668 MMI_PassSeatFrontLiftPosPercentValid 3;
BA_ "GenSigInvalidValue" SG_ 668 MMI_PassSeatFrontLiftPosPercentValid "0x0";
BA_ "GenSigSendType" SG_ 668 MMI_PassSeatFrontLiftPosPercent 3;
BA_ "GenSigStartValue" SG_ 668 MMI_PassSeatFrontLiftPosPercent 63;
BA_ "GenSigInvalidValue" SG_ 668 MMI_PassSeatFrontLiftPosPercent "0x3F";
BA_ "GenSigSendType" SG_ 668 MMI_PassSeatReclinerPosPercentValid 3;
BA_ "GenSigInvalidValue" SG_ 668 MMI_PassSeatReclinerPosPercentValid "0x0";
BA_ "GenSigSendType" SG_ 668 MMI_PassSeatReclinerPosPercent 3;
BA_ "GenSigStartValue" SG_ 668 MMI_PassSeatReclinerPosPercent 63;
BA_ "GenSigInvalidValue" SG_ 668 MMI_PassSeatReclinerPosPercent "0x3F";
BA_ "GenSigSendType" SG_ 668 MMI_PassSeatAllLiftPosPercentValid 3;
BA_ "GenSigInvalidValue" SG_ 668 MMI_PassSeatAllLiftPosPercentValid "0x0";
BA_ "GenSigSendType" SG_ 668 MMI_PassSeatAllLiftPosPercent 3;
BA_ "GenSigStartValue" SG_ 668 MMI_PassSeatAllLiftPosPercent 63;
BA_ "GenSigInvalidValue" SG_ 668 MMI_PassSeatAllLiftPosPercent "0x3F";
BA_ "GenSigSendType" SG_ 668 MMI_PassDrvSeatHeatControlCmd 3;
BA_ "GenSigInvalidValue" SG_ 668 MMI_PassDrvSeatHeatControlCmd "0x0";
BA_ "GenSigSendType" SG_ 668 MMI_PassDrvSeatVenControlCmd 3;
BA_ "GenSigInvalidValue" SG_ 668 MMI_PassDrvSeatVenControlCmd "0x0";
BA_ "GenMsgSendType" BO_ 670 2;
BA_ "GenMsgCycleTimeFast" BO_ 670 20 ;
BA_ "GenMsgNrOfRepetition" BO_ 670 3 ;
BA_ "GenSigSendType" SG_ 670 MMI_HazardLightCmd 3;
BA_ "GenSigSendType" SG_ 670 MMI_BCMLightCmd 3;
BA_ "GenSigSendType" SG_ 670 MMI_TailgateCmd 3;
BA_ "GenSigSendType" SG_ 670 MMI_RearViewCmd 3;
BA_ "GenSigSendType" SG_ 670 MMI_DoorLockCmd 3;
BA_ "GenSigSendType" SG_ 670 MMI_LowBeamLightCmd 3;
BA_ "GenSigSendType" SG_ 670 MMI_HighBeamLightCmd 3;
BA_ "GenSigSendType" SG_ 670 MMI_FoglightCmd 3;
BA_ "GenSigSendType" SG_ 670 MMI_WiperCmd 3;
BA_ "GenSigSendType" SG_ 670 MMI_FronLeftDoorWindowCmd 3;
BA_ "GenSigInvalidValue" SG_ 670 MMI_FronLeftDoorWindowCmd "0x0";
BA_ "GenSigSendType" SG_ 670 MMI_FronRightDoorWindowCmd 3;
BA_ "GenSigInvalidValue" SG_ 670 MMI_FronRightDoorWindowCmd "0x0";
BA_ "GenSigSendType" SG_ 670 MMI_RearLeftDoorWindowCmd 3;
BA_ "GenSigInvalidValue" SG_ 670 MMI_RearLeftDoorWindowCmd "0x0";
BA_ "GenSigSendType" SG_ 670 MMI_FourDoorWindowCmd 3;
BA_ "GenSigInvalidValue" SG_ 670 MMI_FourDoorWindowCmd "0x0";
BA_ "GenSigSendType" SG_ 670 MMI_FrontDoorWindowCmd 3;
BA_ "GenSigInvalidValue" SG_ 670 MMI_FrontDoorWindowCmd "0x0";
BA_ "GenSigSendType" SG_ 670 MMI_AutolightSWCmd 3;
BA_ "GenSigSendType" SG_ 670 MMI_RainAutoClsWindowCmd 3;
BA_ "GenSigInvalidValue" SG_ 670 MMI_RainAutoClsWindowCmd "0";
BA_ "GenSigSendType" SG_ 670 MMI_RearRightDoorWindowCmd 3;
BA_ "GenSigInvalidValue" SG_ 670 MMI_RearRightDoorWindowCmd "0x0";
BA_ "GenSigSendType" SG_ 670 MMI_RearViewMirrorSelect 3;
BA_ "GenSigInvalidValue" SG_ 670 MMI_RearViewMirrorSelect "0x0";
BA_ "GenSigSendType" SG_ 670 MMI_RearViewMirrorUpDown 3;
BA_ "GenSigInvalidValue" SG_ 670 MMI_RearViewMirrorUpDown "0x0";
BA_ "GenSigSendType" SG_ 670 MMI_RearViewMirrorLeftRight 3;
BA_ "GenSigInvalidValue" SG_ 670 MMI_RearViewMirrorLeftRight "0x0";
BA_ "GenSigSendType" SG_ 670 MMI_LockVehicleWarmingTip 3;
BA_ "GenSigInvalidValue" SG_ 670 MMI_LockVehicleWarmingTip "0";
BA_ "GenSigSendType" SG_ 670 MMI_UnlockVehicleOpenCourtesyLampSW 3;
BA_ "GenSigInvalidValue" SG_ 670 MMI_UnlockVehicleOpenCourtesyLampSW "0";
BA_ "GenSigSendType" SG_ 670 MMI_AccLampSet 3;
BA_ "GenSigInvalidValue" SG_ 670 MMI_AccLampSet "0";
BA_ "GenSigSendType" SG_ 670 MMI_RearViewMirrorAutoFoldFuc 3;
BA_ "GenSigInvalidValue" SG_ 670 MMI_RearViewMirrorAutoFoldFuc "0";
BA_ "GenMsgSendType" BO_ 792 2;
BA_ "GenMsgCycleTimeFast" BO_ 792 20 ;
BA_ "GenMsgNrOfRepetition" BO_ 792 3 ;
BA_ "GenSigStartValue" SG_ 792 MMI_LicensePlate_ProvinceName 63;
BA_ "GenSigInvalidValue" SG_ 792 MMI_LicensePlate_ProvinceName "0x3f";
BA_ "GenSigStartValue" SG_ 792 MMI_LicensePlate_Num1 63;
BA_ "GenSigInvalidValue" SG_ 792 MMI_LicensePlate_Num1 "0x3f";
BA_ "GenSigStartValue" SG_ 792 MMI_LicensePlate_Num2 63;
BA_ "GenSigInvalidValue" SG_ 792 MMI_LicensePlate_Num2 "0x3f";
BA_ "GenSigStartValue" SG_ 792 MMI_LicensePlate_Num3 63;
BA_ "GenSigInvalidValue" SG_ 792 MMI_LicensePlate_Num3 "0x3f";
BA_ "GenSigStartValue" SG_ 792 MMI_LicensePlate_Num4 63;
BA_ "GenSigInvalidValue" SG_ 792 MMI_LicensePlate_Num4 "0x3f";
BA_ "GenSigStartValue" SG_ 792 MMI_LicensePlate_Num5 63;
BA_ "GenSigInvalidValue" SG_ 792 MMI_LicensePlate_Num5 "0x3f";
BA_ "GenSigStartValue" SG_ 792 MMI_LicensePlate_Num6 63;
BA_ "GenSigInvalidValue" SG_ 792 MMI_LicensePlate_Num6 "0x3f";
BA_ "GenSigStartValue" SG_ 792 MMI_LicensePlate_Num7 63;
BA_ "GenSigInvalidValue" SG_ 792 MMI_LicensePlate_Num7 "0x3f";
BA_ "GenMsgCycleTime" BO_ 390 50 ;
BA_ "GenSigInvalidValue" SG_ 390 AVM_BSDLeftWaringSeverity "0x7F";
BA_ "GenSigInvalidValue" SG_ 390 AVM_BSDLeftWaringValid "0x0";
BA_ "GenSigInvalidValue" SG_ 390 AVM_BSDRightWaringSeverity "0x7F";
BA_ "GenSigInvalidValue" SG_ 390 AVM_BSDRightWaringValid "0x0";
BA_ "GenSigInvalidValue" SG_ 390 AVM_BSDStatusValid "0x0";
BA_ "GenMsgCycleTime" BO_ 392 50 ;
BA_ "GenSigInvalidValue" SG_ 392 AVM_MMI_ConnectStatus "0xf";
BA_ "GenSigInvalidValue" SG_ 392 AVM_MMI_EcuStatus "0xf";
BA_ "GenSigInvalidValue" SG_ 392 AVM_MMI_VideoOutputStatus "0x3";
BA_ "GenSigInvalidValue" SG_ 392 AVM_MMI_AVM3DViewModeStatus "0xf";
BA_ "GenMsgCycleTime" BO_ 636 100 ;
BA_ "GenSigInvalidValue" SG_ 636 AVM_MMI_LanguageSet "0xf";
BA_ "GenSigInvalidValue" SG_ 636 AVM_MMI_AVM3DDynTrajSet "0x3";
BA_ "GenSigInvalidValue" SG_ 636 AVM_MMI_AVM3DExitDelaySet "0x3";
BA_ "GenSigInvalidValue" SG_ 636 AVM_MMI_AVM3DTurnLightSet "0x3";
BA_ "GenSigInvalidValue" SG_ 636 AVM_MMI_AVM3DBlindFillSet "0x3";
BA_ "GenSigInvalidValue" SG_ 636 AVM_MMI_BSDFunction "0x3";
BA_ "GenSigInvalidValue" SG_ 636 AVM_MMI_OTFunction "0x3";
BA_ "GenSigInvalidValue" SG_ 636 AVM_MMI_AVM3DCarIconColor "0xf";
BA_ "GenSigInvalidValue" SG_ 636 AVM_MMI_AVM3DCarIconTransparent "0xFF";
BA_ "GenMsgCycleTime" BO_ 778 500 ;
BA_ "GenSigStartValue" SG_ 778 AVM_LicensePlate_ProvinceName 63;
BA_ "GenSigInvalidValue" SG_ 778 AVM_LicensePlate_ProvinceName "0x3f";
BA_ "GenSigStartValue" SG_ 778 AVM_LicensePlate_Num1 63;
BA_ "GenSigInvalidValue" SG_ 778 AVM_LicensePlate_Num1 "0x3f";
BA_ "GenSigStartValue" SG_ 778 AVM_LicensePlate_Num2 63;
BA_ "GenSigInvalidValue" SG_ 778 AVM_LicensePlate_Num2 "0x3f";
BA_ "GenSigStartValue" SG_ 778 AVM_LicensePlate_Num3 63;
BA_ "GenSigInvalidValue" SG_ 778 AVM_LicensePlate_Num3 "0x3f";
BA_ "GenSigStartValue" SG_ 778 AVM_LicensePlate_Num4 63;
BA_ "GenSigInvalidValue" SG_ 778 AVM_LicensePlate_Num4 "0x3f";
BA_ "GenSigStartValue" SG_ 778 AVM_LicensePlate_Num5 63;
BA_ "GenSigInvalidValue" SG_ 778 AVM_LicensePlate_Num5 "0x3f";
BA_ "GenSigStartValue" SG_ 778 AVM_LicensePlate_Num6 63;
BA_ "GenSigInvalidValue" SG_ 778 AVM_LicensePlate_Num6 "0x3f";
BA_ "GenSigStartValue" SG_ 778 AVM_LicensePlate_Num7 63;
BA_ "GenSigInvalidValue" SG_ 778 AVM_LicensePlate_Num7 "0x3f";
BA_ "GenMsgCycleTime" BO_ 788 2000 ;
BA_ "GenSigInvalidValue" SG_ 788 AVM_MCU_Version "0xFFFFFF";
BA_ "GenSigInvalidValue" SG_ 788 AVM_BSP_Version "0xFFFFFF";
BA_ "GenMsgCycleTime" BO_ 790 2000 ;
BA_ "GenSigInvalidValue" SG_ 790 AVM_ZADAS_Version "0xFFFFFF";
BA_ "GenSigInvalidValue" SG_ 790 Avm3d_licenseStatus "0x3";
BA_ "GenSigInvalidValue" SG_ 790 BSD_licenseStatus "0x3";
BA_ "DiagState" BO_ 2015 1 ;
BA_ "DiagResponse" BO_ 2015 1 ;
BA_ "GenMsgSendType" BO_ 2015 2;
BA_ "GenSigSendType" SG_ 2015 Functional_Diag_Data_Request0 2;
BA_ "GenSigSendType" SG_ 2015 Functional_Diag_Data_Request1 2;
BA_ "GenSigSendType" SG_ 2015 Functional_Diag_Data_Request2 2;
BA_ "GenSigSendType" SG_ 2015 Functional_Diag_Data_Request3 2;
BA_ "GenSigSendType" SG_ 2015 Functional_Diag_Data_Request4 2;
BA_ "GenSigSendType" SG_ 2015 Functional_Diag_Data_Request5 2;
BA_ "GenSigSendType" SG_ 2015 Functional_Diag_Data_Request6 2;
BA_ "GenSigSendType" SG_ 2015 Functional_Diag_Data_Request7 2;
BA_ "DiagState" BO_ 1832 1 ;
BA_ "DiagResponse" BO_ 1832 1 ;
BA_ "GenMsgSendType" BO_ 1832 2;
BA_ "GenSigSendType" SG_ 1832 IC_Diagnostic_Data_Request0 2;
BA_ "GenSigSendType" SG_ 1832 IC_Diagnostic_Data_Request1 2;
BA_ "GenSigSendType" SG_ 1832 IC_Diagnostic_Data_Request2 2;
BA_ "GenSigSendType" SG_ 1832 IC_Diagnostic_Data_Request3 2;
BA_ "GenSigSendType" SG_ 1832 IC_Diagnostic_Data_Request4 2;
BA_ "GenSigSendType" SG_ 1832 IC_Diagnostic_Data_Request5 2;
BA_ "GenSigSendType" SG_ 1832 IC_Diagnostic_Data_Request6 2;
BA_ "GenSigSendType" SG_ 1832 IC_Diagnostic_Data_Request7 2;
BA_ "NmMessage" BO_ 1043 1 ;
BA_ "GenMsgSendType" BO_ 1043 2;
BA_ "GenSigSendType" SG_ 1043 CONF_GW_NM_Message0 2;
BA_ "GenSigSendType" SG_ 1043 CONF_GW_NM_Message1 2;
BA_ "GenSigSendType" SG_ 1043 CONF_GW_NM_Message2 2;
BA_ "GenSigSendType" SG_ 1043 CONF_GW_NM_Message3 2;
BA_ "GenSigSendType" SG_ 1043 CONF_GW_NM_Message4 2;
BA_ "GenSigSendType" SG_ 1043 CONF_GW_NM_Message5 2;
BA_ "GenSigSendType" SG_ 1043 CONF_GW_NM_Message6 2;
BA_ "GenSigSendType" SG_ 1043 CONF_GW_NM_Message7 2;
BA_ "GenMsgSendType" BO_ 586 4;
BA_ "GenMsgCycleTime" BO_ 586 100 ;
BA_ "GenMsgCycleTimeFast" BO_ 586 20 ;
BA_ "GenMsgNrOfRepetition" BO_ 586 10 ;
BA_ "GenSigInvalidValue" SG_ 586 ACU_Crashinfo "0x7";
BA_ "GenMsgCycleTime" BO_ 352 20 ;
BA_ "GenSigInvalidValue" SG_ 352 ACC_Set_Headway "0x7";
BA_ "GenSigInvalidValue" SG_ 352 ACC_Torque_Request "0xFFFF";
BA_ "GenSigInvalidValue" SG_ 352 ACC_Decelerate_Request "0xFFF";
BA_ "GenMsgCycleTime" BO_ 354 20 ;
BA_ "GenSigInvalidValue" SG_ 354 AEB_Decelerate_Request "0xFFF";
BA_ "GenMsgCycleTime" BO_ 356 20 ;
BA_ "GenSigInvalidValue" SG_ 356 TSR_Targetspeed_Request "0xFF";
BA_ "GenMsgCycleTime" BO_ 384 50 ;
BA_ "GenSigInvalidValue" SG_ 384 APA_MMI_ConnectStatus "0xF";
BA_ "GenSigInvalidValue" SG_ 384 APA_MMI_3DViewModeStatus "0xF";
BA_ "GenMsgCycleTime" BO_ 386 50 ;
BA_ "GenSigInvalidValue" SG_ 386 APA_BSDLeftWaringSeverity "0x7F";
BA_ "GenSigInvalidValue" SG_ 386 APA_BSDLeftWaringValid "0x0";
BA_ "GenSigInvalidValue" SG_ 386 APA_BSDRightWaringSeverity "0x7F";
BA_ "GenSigInvalidValue" SG_ 386 APA_BSDRightWaringValid "0x0";
BA_ "GenSigInvalidValue" SG_ 386 APA_BSDStatusValid "0x0";
BA_ "GenMsgCycleTime" BO_ 387 50 ;
BA_ "GenSigInvalidValue" SG_ 387 PAS_APA_DistanceLR_RL "0x1FF";
BA_ "GenSigInvalidValue" SG_ 387 PAS_APA_DistanceLR_RR "0x1FF";
BA_ "GenSigInvalidValue" SG_ 387 PAS_APA_DistanceSR_RL "0xFF";
BA_ "GenSigInvalidValue" SG_ 387 PAS_APA_DistanceSR_RML "0xFF";
BA_ "GenSigInvalidValue" SG_ 387 PAS_APA_DistanceSR_RMR "0xFF";
BA_ "GenSigInvalidValue" SG_ 387 PAS_APA_DistanceSR_RR "0xFF";
BA_ "GenMsgCycleTime" BO_ 388 50 ;
BA_ "GenSigInvalidValue" SG_ 388 PAS_APA_DistanceLR_FL "0x1FF";
BA_ "GenSigInvalidValue" SG_ 388 PAS_APA_DistanceLR_FR "0x1FF";
BA_ "GenSigInvalidValue" SG_ 388 PAS_APA_DistanceSR_FL "0xFF";
BA_ "GenSigInvalidValue" SG_ 388 PAS_APA_DistanceSR_FML "0xFF";
BA_ "GenSigInvalidValue" SG_ 388 PAS_APA_DistanceSR_FMR "0xFF";
BA_ "GenSigInvalidValue" SG_ 388 PAS_APA_DistanceSR_FR "0xFF";
BA_ "GenMsgCycleTime" BO_ 784 200 ;
BA_ "GenSigInvalidValue" SG_ 784 APA_AVM_MCU_Version "0xFFFFFF";
BA_ "GenSigInvalidValue" SG_ 784 APA_AVM_BSP_Version "0xFFFFFF";
BA_ "GenMsgCycleTime" BO_ 786 2000 ;
BA_ "GenSigInvalidValue" SG_ 786 APA_AVM_ZADAS_Version "0xFFFFFF";
BA_ "GenSigInvalidValue" SG_ 786 APA_Avm3d_licenseStatus "0x3";
BA_ "GenSigInvalidValue" SG_ 786 APA_BSD_licenseStatus "0x3";
BA_ "GenMsgCycleTime" BO_ 512 100 ;
BA_ "GenSigInvalidValue" SG_ 512 BMS_battery_outside_Voltage "0xFFFF";
BA_ "GenMsgCycleTime" BO_ 514 100 ;
BA_ "GenSigInvalidValue" SG_ 514 BMS_ChrgAllowance "0x0";
BA_ "GenSigInvalidValue" SG_ 514 BMS_Sys_ChgorDisChrgSts "0x0";
BA_ "GenSigInvalidValue" SG_ 514 BMS_FastChrgSts "0x0";
BA_ "GenSigInvalidValue" SG_ 514 BMS_SlowChrgSts "0x0";
BA_ "GenSigInvalidValue" SG_ 514 BMS_PauseContinueChrgStus "0x0";
BA_ "GenSigInvalidValue" SG_ 514 BMS_AllowedChrgMaxPower "0x7F";
BA_ "GenMsgCycleTime" BO_ 518 100 ;
BA_ "GenSigInvalidValue" SG_ 518 BMS_battery_WaterTemp_in "0xFF";
BA_ "GenSigInvalidValue" SG_ 518 BMS_battery_WaterTemp_out "0xFF";
BA_ "GenSigInvalidValue" SG_ 518 BMS_battery_WaterTemp_average "0xFF";
BA_ "GenSigInvalidValue" SG_ 518 BMS_FlowRateReq "0xFF";
BA_ "GenSigStartValue" SG_ 518 BMS_InletWaterTempTarget 130;
BA_ "GenSigInvalidValue" SG_ 518 BMS_InletWaterTempTarget "0xFF";
BA_ "GenMsgCycleTime" BO_ 524 100 ;
BA_ "GenSigInvalidValue" SG_ 524 BMS_TotalErrNumber "0xFF";
BA_ "GenMsgCycleTime" BO_ 528 100 ;
BA_ "GenSigInvalidValue" SG_ 528 BMS_Sys_MinCellV "0xFFFF";
BA_ "GenSigInvalidValue" SG_ 528 BMS_Sys_MaxCellV "0xFFFF";
VAL_ 604 IC_Vehicle_Speed_Available 0 " Unavailable" 1 " Available"  ;
VAL_ 604 ICU_EBDLampSt 0 " LightOff_with no failure" 1 " LightOn_with no failure" 2 " not used" 3 " Off - failure present"  ;
VAL_ 604 ICU_ABSLampSt 0 " LightOff_with no failure" 1 " LightOn_with no failure" 2 " not used" 3 " Off - failure present"  ;
VAL_ 604 ICU_AirBagSysWrnLmpSts 0 " LightOff_with no failure" 1 " LightOn_with no failure" 2 " not used" 3 " Off - failure present"  ;
VAL_ 604 MMI_AVM_ConnectStatus 0 " none(解决车机晚于AVM启动。AVM侧此状态可认为车机默认为已连接处理)" 1 " disconnect" 2 " connected" 15 " invalid"  ;
VAL_ 604 ICU_PDC_DistanceAlarmDegree_RR 0 " no alarm；" 1 " alarm 1(距离<40cm)；" 2 " alarm 2(40cm<距离<65cm)；" 3 " reserved"  ;
VAL_ 604 ICU_PDC_DistanceAlarmDegree_RL 0 " no alarm；" 1 " alarm 1(距离<40cm)；" 2 " alarm 2(40cm<距离<65cm)；" 3 " reserved"  ;
VAL_ 604 ICU_PDC_DistanceAlarmDegree_RRM 0 " no alarm；" 1 " alarm 1(距离<40cm)；" 2 " alarm 2(40cm<距离<100cm)；" 3 " alarm 3(100cm<距离<150cm)；"  ;
VAL_ 604 ICU_PDC_DistanceAlarmDegree_RLM 0 " no alarm；" 1 " alarm 1(距离<40cm)；" 2 " alarm 2(40cm<距离<100cm)；" 3 " alarm 3(100cm<距离<150cm)；"  ;
VAL_ 620 PAS_PDC_Mode 0 " 车型请求模式" 1 " 自检模式" 2 " 正常工作模式" 3 " 停止" 4 " 通讯超时故障" 5 " Reserved" 6 " Reserved" 7 " Reserved"  ;
VAL_ 620 PAS_PDC_SensorSts_RR 0 " normal" 1 " fault"  ;
VAL_ 620 PAS_PDC_SensorSts_RL 0 " normal" 1 " fault"  ;
VAL_ 620 PAS_PDC_SensorSts_RRM 0 " normal" 1 " fault"  ;
VAL_ 620 PAS_PDC_SensorSts_RLM 0 " normal" 1 " fault"  ;
VAL_ 648 MMI_ACAUTOReqValid 0 " Invalid" 1 " Valid"  ;
VAL_ 648 MMI_ACAUTOReq 0 " OFF" 1 " ON"  ;
VAL_ 648 MMI_ACCompressorReqValid 0 " Invalid" 1 " Valid"  ;
VAL_ 648 MMI_ACCompressorReq 0 " OFF" 1 " ON"  ;
VAL_ 648 MMI_ACMaxReqValid 0 " Invalid" 1 " Valid"  ;
VAL_ 648 MMI_ACMaxReq 0 " No Req" 1 " Req"  ;
VAL_ 648 MMI_ACOFFReqValid 0 " Invalid" 1 " Valid"  ;
VAL_ 648 MMI_ACOFFReq 0 " No Req" 1 " OFF"  ;
VAL_ 648 MMI_InsideTempIncDecReqValid 0 " Invalid" 1 " Valid"  ;
VAL_ 648 MMI_InsideTempIncDecReq 0 " Up" 1 " Down"  ;
VAL_ 648 MMI_BLOWERReqValid 0 " Invalid" 1 " Valid"  ;
VAL_ 648 MMI_BLOWERReq 0 " Up" 1 " Down"  ;
VAL_ 648 MMI_ACBlowModeReqValid 0 " Invalid" 1 " Valid"  ;
VAL_ 648 MMI_ACBlowModeReq 0 " No Req" 1 " Face" 2 " Reserved" 3 " FootAndDefrost" 4 " Foot" 5 " FaceAndFoot" 6 " reserved" 7 " reserved"  ;
VAL_ 648 MMI_CirculatingModeSetValid 0 " Invalid" 1 " Valid"  ;
VAL_ 648 MMI_CirculatingModeSet 0 " 车内循环" 1 " 车外循环"  ;
VAL_ 648 MMI_InsideTempSetValid 0 " Invalid" 1 " Valid"  ;
VAL_ 648 MMI_SeatHeatReq_right 0 " Invalid" 1 " off" 2 " 1档" 3 " 2档"  ;
VAL_ 648 MMI_SeatHeatReq_left 0 " Invalid" 1 " off" 2 " 1档" 3 " 2档"  ;
VAL_ 648 MMI_BLOWERGearSetValid 0 " Invalid" 1 " Valid"  ;
VAL_ 648 MMI_BLOWERGearSet 0 " No req" 1 " Gear1" 2 " Gear2" 3 " Gear3" 4 " Gear4" 5 " Gear5" 6 " Gear6" 7 " Gear7"  ;
VAL_ 648 MMI_FrontDeforstReq 0 " Invalid" 1 " On" 2 " Off" 3 " Reserved"  ;
VAL_ 648 MMI_RearDeforstReq 0 " Invalid" 1 " On" 2 " Off" 3 " Reserved"  ;
VAL_ 648 MMI_EnergyRecoveryContr 0 " Invalid" 1 " Lev0" 2 " Lev1" 3 " Lev2" 4 " Lev3" 5 " reserved" 6 " reserved" 7 " reserved"  ;
VAL_ 648 MMI_RearViewMirrorHeatReq 0 " invalid" 1 " open" 2 " close" 3 " reserved"  ;
VAL_ 648 MMI_AnionNegativeIonReq 0 " Invalid" 1 " On" 2 " Off" 3 " Reserved"  ;
VAL_ 370 MMI_LDW_Main_Switch 0 " Off" 1 " On"  ;
VAL_ 370 MMI_LDW_Switch_Available 0 " Available" 1 " Unavailable"  ;
VAL_ 370 MMI_FCW_Sensitivity 0 " Reserved" 1 " Level 1" 2 " Level 2" 3 " Level 3"  ;
VAL_ 370 MMI_FCW_Main_Switch 0 " Off" 1 " On"  ;
VAL_ 370 MMI_FCW_Switch_Available 0 " Available" 1 " Unavailable"  ;
VAL_ 370 MMI_AEB_Main_Switch 0 " Off" 1 " On"  ;
VAL_ 370 MMI_AEB_Switch_Available 0 " Available" 1 " Unavailable"  ;
VAL_ 370 MMI_TSR_Main_Switch 0 " Off" 1 " On"  ;
VAL_ 370 MMI_TSR_Switch_Available 0 " Available" 1 " Unavailable"  ;
VAL_ 370 MMI_IHC_Main_Switch 0 " Off" 1 " On"  ;
VAL_ 370 MMI_IHC_Switch_Available 0 " Available" 1 " Unavailable"  ;
VAL_ 370 MMI_LDW_Sensitivity 0 " Reserved" 1 " Low" 2 " Normal" 3 " High"  ;
VAL_ 370 MMI_BSD_Main_Switch 0 " Off" 1 " On"  ;
VAL_ 370 MMI_BSD_Switch_Available 0 " Unavailable" 1 " Available"  ;
VAL_ 370 MMI_BSD_Sensitivity 0 " Reserved" 1 " Low" 2 " Normal" 3 " High"  ;
VAL_ 370 MMI_EPS_ModeSwitch 0 " Invalid" 1 " Conf舒适" 2 " Standard标准" 3 " Sport运动" 4 " Snowfield雪地" 5 " Reserved" 6 " Reserved" 7 " Reserved"  ;
VAL_ 370 MMI_PauseContinueChrgRQ 0 " invalid" 1 " 暂停充电" 2 " 继续充电" 3 " reserved"  ;
VAL_ 370 MMI_WCBS_CstSwitch 0 " Off" 1 " On"  ;
VAL_ 370 MMI_OperationMode 0 " Reserved保留" 1 " normal正常" 2 " Economic经济" 3 " Sport运动" 4 " User define自定义" 5 " Reserved" 6 " Reserved" 7 " Reserved"  ;
VAL_ 370 MMI_ChrgCurrentSet 0 " invalid"  ;
VAL_ 630 MMI_AVM_LanguageSet 0 " none" 1 " English" 2 " Chinese" 3 " reserved" 4 " reserved" 5 " reserved" 6 " reserved" 7 " reserved" 8 " reserved" 9 " reserved" 10 " reserved" 11 " reserved" 12 " reserved" 13 " reserved" 14 " reserved" 15 " invalid"  ;
VAL_ 630 MMI_AVM_AVM3DDynTrajSet 0 " none" 1 " off" 2 " on" 3 " invalid"  ;
VAL_ 630 MMI_AVM_AVM3DExitDelaySet 0 " none" 1 " off" 2 " on" 3 " invalid"  ;
VAL_ 630 MMI_AVM_AVM3DTurnLightSet 0 " none" 1 " off" 2 " on" 3 " invalid"  ;
VAL_ 630 MMI_AVM_AVM3DBlindFillSet 0 " none" 1 " off" 2 " on" 3 " invalid"  ;
VAL_ 630 MMI_AVM_BSDFunction 0 " none" 1 " off" 2 " on" 3 " invalid"  ;
VAL_ 630 MMI_AVM_OTFunction 0 " none" 1 " off" 2 " on" 3 " invalid"  ;
VAL_ 630 MMI_AVM_AVM3DCarIconColor 0 " none" 1 "red" 2 "yellow" 3 "blue" 4 "white" 5 "black" 6 " reserved" 7 " reserved" 8 " reserved" 9 " reserved" 10 " reserved" 11 " reserved" 12 " reserved" 13 " reserved" 14 " reserved" 15 " invalid"  ;
VAL_ 630 MMI_AVM_AVM3DCarIconTransparenValid 0 " none" 1 " valid/有效时，才能使用AVM3D车模透明度" 2 " reserved" 3 " invalid"  ;
VAL_ 630 MMI_AVM_VideoOutputStatus 0 " none/显示MMI画面" 1 " off/显示MMI画面" 2 " on/显示AVM画面" 3 " invalid/显示MMI画面" 4 " reserved" 5 " reserved" 6 " reserved" 7 " reserved" 8 " reserved" 9 " reserved" 10 " reserved" 11 " reserved" 12 " reserved" 13 " reserved" 14 " reserved" 15 " invalid"  ;
VAL_ 630 MMI_AVM_AVM3DCarIconTransparent 0 " 车模透明度的0~100%" 1 " 车模透明度的0~100%" 2 " 车模透明度的0~100%" 3 " 车模透明度的0~100%" 4 " 车模透明度的0~100%" 5 " 车模透明度的0~100%" 6 " 车模透明度的0~100%" 7 " 车模透明度的0~100%" 8 " 车模透明度的0~100%" 9 " 车模透明度的0~100%" 10 " 车模透明度的0~100%" 11 " 车模透明度的0~100%" 12 " 车模透明度的0~100%" 13 " 车模透明度的0~100%" 14 " 车模透明度的0~100%" 15 " 车模透明度的0~100%" 16 " 车模透明度的0~100%" 17 " 车模透明度的0~100%" 18 " 车模透明度的0~100%" 19 " 车模透明度的0~100%" 20 " 车模透明度的0~100%" 21 " 车模透明度的0~100%" 22 " 车模透明度的0~100%" 23 " 车模透明度的0~100%" 24 " 车模透明度的0~100%" 25 " 车模透明度的0~100%" 26 " 车模透明度的0~100%" 27 " 车模透明度的0~100%" 28 " 车模透明度的0~100%" 29 " 车模透明度的0~100%" 30 " 车模透明度的0~100%" 31 " 车模透明度的0~100%" 32 " 车模透明度的0~100%" 33 " 车模透明度的0~100%" 34 " 车模透明度的0~100%" 35 " 车模透明度的0~100%" 36 " 车模透明度的0~100%" 37 " 车模透明度的0~100%" 38 " 车模透明度的0~100%" 39 " 车模透明度的0~100%" 40 " 车模透明度的0~100%" 41 " 车模透明度的0~100%" 42 " 车模透明度的0~100%" 43 " 车模透明度的0~100%" 44 " 车模透明度的0~100%" 45 " 车模透明度的0~100%" 46 " 车模透明度的0~100%" 47 " 车模透明度的0~100%" 48 " 车模透明度的0~100%" 49 " 车模透明度的0~100%" 50 " 车模透明度的0~100%" 51 " 车模透明度的0~100%" 52 " 车模透明度的0~100%" 53 " 车模透明度的0~100%" 54 " 车模透明度的0~100%" 55 " 车模透明度的0~100%" 56 " 车模透明度的0~100%" 57 " 车模透明度的0~100%" 58 " 车模透明度的0~100%" 59 " 车模透明度的0~100%" 60 " 车模透明度的0~100%" 61 " 车模透明度的0~100%" 62 " 车模透明度的0~100%" 63 " 车模透明度的0~100%" 64 " 车模透明度的0~100%" 65 " 车模透明度的0~100%" 66 " 车模透明度的0~100%" 67 " 车模透明度的0~100%" 68 " 车模透明度的0~100%" 69 " 车模透明度的0~100%" 70 " 车模透明度的0~100%" 71 " 车模透明度的0~100%" 72 " 车模透明度的0~100%" 73 " 车模透明度的0~100%" 74 " 车模透明度的0~100%" 75 " 车模透明度的0~100%" 76 " 车模透明度的0~100%" 77 " 车模透明度的0~100%" 78 " 车模透明度的0~100%" 79 " 车模透明度的0~100%" 80 " 车模透明度的0~100%" 81 " 车模透明度的0~100%" 82 " 车模透明度的0~100%" 83 " 车模透明度的0~100%" 84 " 车模透明度的0~100%" 85 " 车模透明度的0~100%" 86 " 车模透明度的0~100%" 87 " 车模透明度的0~100%" 88 " 车模透明度的0~100%" 89 " 车模透明度的0~100%" 90 " 车模透明度的0~100%" 91 " 车模透明度的0~100%" 92 " 车模透明度的0~100%" 93 " 车模透明度的0~100%" 94 " 车模透明度的0~100%" 95 " 车模透明度的0~100%" 96 " 车模透明度的0~100%" 97 " 车模透明度的0~100%" 98 " 车模透明度的0~100%" 99 " 车模透明度的0~100%" 100 " 车模透明度的0~100%" 255 "invalid"  ;
VAL_ 632 MMI_AVMTouchEventType 0 " Invalid" 1 " GESTURE_ONE_FINGER_DOWN" 2 " GESTURE_ONE_FINGER_UP" 3 " GESTURE_ONE_FINGER_SINGLE_CLICK" 4 " GESTURE_ONE_FINGER_DOUBLE_CLICK" 5 " GESTURE_ONE_FINGER_LONG_PRESS" 6 " GESTURE_ONE_FINGER_MOVING" 7 " GESTURE_ONE_FINGER_SWIPE" 8 " GESTURE_ZOOM_IN" 9 " GESTURE_ZOOM_OUT" 10 " GESTURE_ROTATE" 11 " Reserved" 12 " Reserved" 13 " Reserved" 14 " Reserved" 15 " Reserved"  ;
VAL_ 634 MMI_AVM_AVM3D_COMMAND 0 " none" 1 " clear otf calibration data" 15 " invalid"  ;
VAL_ 634 MMI_AVM_AVM3DViewModeSwitch 0 " none" 1 " 2d" 2 " 3d" 3 " speed3D" 4 " Ctv_Front" 5 " Ctv_Rear" 6 " Rim_Front" 7 " Rim_Rear" 8 " reserved" 9 " reserved" 10 " reserved" 11 " reserved" 12 " reserved" 13 " reserved" 14 " reserved" 15 " invalid"  ;
VAL_ 634 MMI_AVM_AVMEcuEnterExit 0 " none" 1 " avm3d_enter_softkey" 2 " avm3d_enter_hardkey" 3 " avm3d_enter_gesture" 4 " avm3d_enter_recognition" 5 " reserved" 6 " reserved" 7 " reserved" 8 " avm3d_exit_softkey" 9 " avm3d_exit_hardkey" 10 " avm3d_exit_gesture" 11 " avm3d_exit_recognition" 16 " reserved" 17 " calibration enter/标定只有进入，禁止从车机请求退出"  ;
VAL_ 634 MMI_AVM_AVM3DViewSwitch 0 " none" 1 " 2d_front" 2 " 2d_right" 3 " 2d_left" 4 " 2d_rear" 5 " reserved" 6 " reserved" 7 " reserved" 8 " reserved" 9 " reserved" 10 " reserved" 11 " reserved" 12 " reserved" 13 " reserved" 14 " reserved" 15 " reserved" 16 " reserved" 17 " 3d_front" 18 " 3d_right" 19 " 3d_left" 20 " 3d_rear" 21 " 3d_right_front" 22 " 3d_left_front" 23 " 3d_left_rear" 24 " 3d_right_rear" 25 " reserved" 26 " reserved" 27 " reserved" 28 " reserved" 29 " reserved" 30 " reserved" 31 " reserved" 32 " reserved" 33 " reserved" 34 " reserved" 35 " reserved" 36 " reserved" 37 " reserved" 38 " reserved" 39 " reserved" 40 " reserved" 41 " reserved" 42 " reserved" 43 " reserved" 44 " reserved" 45 " reserved" 46 " reserved" 47 " reserved" 48 " reserved" 49 " reserved" 50 " reserved" 51 " reserved" 52 " reserved" 53 " reserved" 54 " reserved" 55 " reserved" 56 " reserved" 57 " reserved" 58 " reserved" 59 " reserved" 60 " reserved" 61 " reserved" 62 " reserved" 63 " reserved" 64 " reserved" 65 " reserved" 66 " reserved" 67 " reserved" 68 " reserved" 69 " reserved" 70 " reserved" 71 " reserved" 72 " reserved" 73 " reserved" 74 " reserved" 75 " reserved" 76 " reserved" 77 " reserved" 78 " reserved" 79 " reserved" 80 " reserved" 81 " reserved" 82 " reserved" 83 " reserved" 84 " reserved" 85 " reserved" 86 " reserved" 87 " reserved" 88 " reserved" 89 " reserved" 90 " reserved" 91 " reserved" 92 " reserved" 93 " reserved" 94 " reserved" 95 " reserved" 96 " reserved" 97 " reserved" 98 " reserved" 99 " reserved" 100 " reserved" 101 " reserved" 102 " reserved" 103 " reserved" 104 " reserved" 105 " reserved" 106 " reserved" 107 " reserved" 108 " reserved" 109 " reserved" 110 " reserved" 111 " reserved" 112 " reserved" 113 " reserved" 114 " reserved" 115 " reserved" 116 " reserved" 117 " reserved" 118 " reserved" 119 " reserved" 120 " reserved" 121 " reserved" 122 " reserved" 123 " reserved" 124 " reserved" 125 " reserved" 126 " reserved" 127 " reserved" 128 " reserved" 129 " reserved" 130 " reserved" 131 " reserved" 132 " reserved" 133 " reserved" 134 " reserved" 135 " reserved" 136 " reserved" 137 " reserved" 138 " reserved" 139 " reserved" 140 " reserved" 141 " reserved" 142 " reserved" 143 " reserved" 144 " reserved" 145 " reserved" 146 " reserved" 147 " reserved" 148 " reserved" 149 " reserved" 150 " reserved" 151 " reserved" 152 " reserved" 153 " reserved" 154 " reserved" 155 " reserved" 156 " reserved" 157 " reserved" 158 " reserved" 159 " reserved" 160 " reserved" 161 " reserved" 162 " reserved" 163 " reserved" 164 " reserved" 165 " reserved" 166 " reserved" 167 " reserved" 168 " reserved" 169 " reserved" 170 " reserved" 171 " reserved" 172 " reserved" 173 " reserved" 174 " reserved" 175 " reserved" 176 " reserved" 177 " reserved" 178 " reserved" 179 " reserved" 180 " reserved" 181 " reserved" 182 " reserved" 183 " reserved" 184 " reserved" 185 " reserved" 186 " reserved" 187 " reserved" 188 " reserved" 189 " reserved" 190 " reserved" 191 " reserved" 192 " reserved" 193 " reserved" 194 " reserved" 195 " reserved" 196 " reserved" 197 " reserved" 198 " reserved" 199 " reserved" 200 " reserved" 201 " reserved" 202 " reserved" 203 " reserved" 204 " reserved" 205 " reserved" 206 " reserved" 207 " reserved" 208 " reserved" 209 " reserved" 210 " reserved" 211 " reserved" 212 " reserved" 213 " reserved" 214 " reserved" 215 " reserved" 216 " reserved" 217 " reserved" 218 " reserved" 219 " reserved" 220 " reserved" 221 " reserved" 222 " reserved" 223 " reserved" 224 " reserved" 225 " reserved" 226 " reserved" 227 " reserved" 228 " reserved" 229 " reserved" 230 " reserved" 231 " reserved" 232 " reserved" 233 " reserved" 234 " reserved" 235 " reserved" 236 " reserved" 237 " reserved" 238 " reserved" 239 " reserved" 240 " reserved" 241 " reserved" 242 " reserved" 243 " reserved" 244 " reserved" 245 " reserved" 246 " reserved" 247 " reserved" 248 " reserved" 249 " reserved" 250 " reserved" 251 " reserved" 252 " reserved" 253 " reserved" 254 " reserved" 255 " reserved"  ;
VAL_ 652 MMI_VoiceSourceSelect_Cycle 0 " Invalid" 1 " Select_ON" 2 " Select_OFF" 3 " reserved"  ;
VAL_ 652 MMI_VoiceSourceSelect 0 " Invalid" 1 " 选择声源1" 2 " 选择声源2" 3 " 选择声源3" 4 " 选择声源4" 5 " 选择声源5" 6 " 选择声源6" 7 " 选择声源7"  ;
VAL_ 652 MMI_VSPEnableCommand 0 " Invalid" 1 " 开启VSP命令（默认" 2 " 关闭VSP命令" 3 " 打开停车模拟（车辆READY，非N档，VSP响）"  ;
VAL_ 652 MMI_AmphereLampCtrl_Colour 0 " 默认颜色" 1 " 红色" 2 " 橙色" 3 " 黄色" 4 " 绿色" 5 " 青色" 6 " 蓝色" 7 " 紫色" 8 " Reserved" 9 " Reserved" 10 " Reserved" 11 " Reserved" 12 " Reserved" 13 " Reserved" 14 " Reserved" 15 " Reserved"  ;
VAL_ 652 MMI_AmphereLampCtrl_Fleshmode 0 " Invalid" 1 " 打开呼吸模式" 2 " 关闭呼吸模式" 3 " 保留"  ;
VAL_ 652 MMI_AmphereLampCtrl_Drivingmode 0 " Invalid" 1 " 打开驾驶模式" 2 " 关闭驾驶模式" 3 " 保留"  ;
VAL_ 652 MMI_AmphereLampCtrl_SW 0 " Invalid" 1 " OFF" 2 " ON" 3 " Reserved"  ;
VAL_ 652 MMI_PlatfondPellAuto_SW 0 " Invalid" 1 " OFF" 2 " ON" 3 " Reserved"  ;
VAL_ 652 MMI_PlatfondPellucidity 127 " Invalid" 0 "0%~100%" 1 "0%~100%" 2 "0%~100%" 3 "0%~100%" 4 "0%~100%" 5 "0%~100%" 6 "0%~100%" 7 "0%~100%" 8 "0%~100%" 9 "0%~100%" 10 "0%~100%" 11 "0%~100%" 12 "0%~100%" 13 "0%~100%" 14 "0%~100%" 15 "0%~100%" 16 "0%~100%" 17 "0%~100%" 18 "0%~100%" 19 "0%~100%" 20 "0%~100%" 21 "0%~100%" 22 "0%~100%" 23 "0%~100%" 24 "0%~100%" 25 "0%~100%" 26 "0%~100%" 27 "0%~100%" 28 "0%~100%" 29 "0%~100%" 30 "0%~100%" 31 "0%~100%" 32 "0%~100%" 33 "0%~100%" 34 "0%~100%" 35 "0%~100%" 36 "0%~100%" 37 "0%~100%" 38 "0%~100%" 39 "0%~100%" 40 "0%~100%" 41 "0%~100%" 42 "0%~100%" 43 "0%~100%" 44 "0%~100%" 45 "0%~100%" 46 "0%~100%" 47 "0%~100%" 48 "0%~100%" 49 "0%~100%" 50 "0%~100%" 51 "0%~100%" 52 "0%~100%" 53 "0%~100%" 54 "0%~100%" 55 "0%~100%" 56 "0%~100%" 57 "0%~100%" 58 "0%~100%" 59 "0%~100%" 60 "0%~100%" 61 "0%~100%" 62 "0%~100%" 63 "0%~100%" 64 "0%~100%" 65 "0%~100%" 66 "0%~100%" 67 "0%~100%" 68 "0%~100%" 69 "0%~100%" 70 "0%~100%" 71 "0%~100%" 72 "0%~100%" 73 "0%~100%" 74 "0%~100%" 75 "0%~100%" 76 "0%~100%" 77 "0%~100%" 78 "0%~100%" 79 "0%~100%" 80 "0%~100%" 81 "0%~100%" 82 "0%~100%" 83 "0%~100%" 84 "0%~100%" 85 "0%~100%" 86 "0%~100%" 87 "0%~100%" 88 "0%~100%" 89 "0%~100%" 90 "0%~100%" 91 "0%~100%" 92 "0%~100%" 93 "0%~100%" 94 "0%~100%" 95 "0%~100%" 96 "0%~100%" 97 "0%~100%" 98 "0%~100%" 99 "0%~100%" 100 "0%~100%"  ;
VAL_ 652 MMI_PlatfondColorCmd 0 " Invalid" 1 " Red红" 2 " Yellow黄" 3 " Blue蓝" 4 " Green绿" 5 " reserved保留" 6 " reserved保留" 7 " reserved保留"  ;
VAL_ 652 MMI_AmphereLampIntellisenseSw 0 " Invalid" 1 " 打开驾驶模式" 2 " 关闭驾驶模式" 3 " 保留"  ;
VAL_ 652 MMI_CWC_Cmd 0 " Invalid" 1 " 打开" 2 " 关闭" 3 " reserve"  ;
VAL_ 666 MMI_DrvSeatSlideCommand 0 " invalid" 1 " 停止调节" 2 " 向前调节" 3 " 向后调节"  ;
VAL_ 666 MMI_DrvSeatFrontLiftCommand 0 " invalid" 1 " 停止调节" 2 " 向上调节" 3 " 向下调节"  ;
VAL_ 666 MMI_DrvSeatReclinerCommand 0 " invalid" 1 " 停止调节" 2 " 向前调节" 3 " 向后调节"  ;
VAL_ 666 MMI_DrvSeatAllLiftCommand 0 " invalid" 1 " 停止调节" 2 " 向上调节" 3 " 向下调节"  ;
VAL_ 666 MMI_DrvSeatSlidePosPercentValid 0 " invalid" 1 " 有效"  ;
VAL_ 666 MMI_DrvSeatFrontLiftPosPercentValid 0 " invalid" 1 " 有效"  ;
VAL_ 666 MMI_DrvSeatReclinerPosPercentValid 0 " invalid" 1 " 有效"  ;
VAL_ 666 MMI_DrvSeatAllLiftPosPercentValid 0 " invalid" 1 " 有效"  ;
VAL_ 666 MMI_DrvSeatHeatControlCmd 0 " Invalid" 1 " OFF" 2 " Heating Level 1" 3 " Heating Level 2" 4 " Heating Level 3" 5 " reserved" 6 " reserved" 7 " reserved"  ;
VAL_ 666 MMI_DrvSeatVenControlCmd 0 " Invalid" 1 " OFF" 2 " Venting Level 1" 3 " Venting Level 2" 4 " Venting Level 3" 5 " reserved" 6 " reserved" 7 " reserved"  ;
VAL_ 666 MMI_DrvSeatHandyEntryExitSet 0 " invalid" 1 " Open" 2 " Close" 3 " Reserved"  ;
VAL_ 668 MMI_PassSeatSlideCommand 0 " invalid" 1 " 停止调节" 2 " 向前调节" 3 " 向后调节"  ;
VAL_ 668 MMI_PassSeatFrontLiftCommand 0 " invalid" 1 " 停止调节" 2 " 向上调节" 3 " 向下调节"  ;
VAL_ 668 MMI_PassSeatReclinerCommand 0 " invalid" 1 " 停止调节" 2 " 向前调节" 3 " 向后调节"  ;
VAL_ 668 MMI_PassSeatAllLiftCommand 0 " invalid" 1 " 停止调节" 2 " 向上调节" 3 " 向下调节"  ;
VAL_ 668 MMI_PassSeatSlidePosPercentValid 0 " invalid" 1 " 有效"  ;
VAL_ 668 MMI_PassSeatFrontLiftPosPercentValid 0 " invalid" 1 " 有效"  ;
VAL_ 668 MMI_PassSeatReclinerPosPercentValid 0 " invalid" 1 " 有效"  ;
VAL_ 668 MMI_PassSeatAllLiftPosPercentValid 0 " invalid" 1 " 有效"  ;
VAL_ 668 MMI_PassDrvSeatHeatControlCmd 0 " Invalid" 1 " OFF" 2 " Heating Level 1" 3 " Heating Level 2" 4 " Heating Level 3" 5 " reserved" 6 " reserved" 7 " reserved"  ;
VAL_ 668 MMI_PassDrvSeatVenControlCmd 0 " Invalid" 1 " OFF" 2 " Venting Level 1" 3 " Venting Level 2" 4 " Venting Level 3" 5 " reserved" 6 " reserved" 7 " reserved"  ;
VAL_ 670 MMI_HazardLightCmd 0 " 无指令" 1 " 打开" 2 " 关闭"  ;
VAL_ 670 MMI_BCMLightCmd 0 " 无指令" 1 " 打开" 2 " 关闭"  ;
VAL_ 670 MMI_TailgateCmd 0 " 无指令" 1 " 尾门打开" 2 " 尾门关闭"  ;
VAL_ 670 MMI_RearViewCmd 0 " 无指令" 1 " 后视镜折叠" 2 " 后视镜展开"  ;
VAL_ 670 MMI_DoorLockCmd 0 " 无指令" 1 " 打开锁" 2 " 关闭锁"  ;
VAL_ 670 MMI_LowBeamLightCmd 0 " 无指令" 1 " 打开" 2 " 关闭"  ;
VAL_ 670 MMI_HighBeamLightCmd 0 " 无指令" 1 " 打开" 2 " 关闭"  ;
VAL_ 670 MMI_FoglightCmd 0 " 无指令" 1 " 打开" 2 " 关闭"  ;
VAL_ 670 MMI_WiperCmd 0 " 无指令" 1 " 点动" 2 " 间歇1档" 3 " 间歇2档" 4 " 间歇3档" 5 " 低速" 6 " 高速" 7 " 停止"  ;
VAL_ 670 MMI_FronLeftDoorWindowCmd 0 " Invalid" 1 " 一键降主驾窗" 2 " 一键升主驾窗" 3 " 点动降主驾窗" 4 " 点动升主驾窗                                                                    0x5～0x7"  ;
VAL_ 670 MMI_FronRightDoorWindowCmd 0 " Invalid" 1 " 一键降副驾窗" 2 " 一键升副驾窗" 3 " 点动降副驾窗" 4 " 点动升副驾窗                                                                    0x5～0x7"  ;
VAL_ 670 MMI_RearLeftDoorWindowCmd 0 " Invalid" 1 " 一键降左后窗" 2 " 一键升左后窗" 3 " 点动降左后窗" 4 " 点动升左后窗                                                                    0x5～0x7"  ;
VAL_ 670 MMI_FourDoorWindowCmd 0 " Invalid" 1 " 一键降四门车窗" 2 " 一键升四门车窗" 3 " Reserved"  ;
VAL_ 670 MMI_FrontDoorWindowCmd 0 " Invalid" 1 " 一键降前车窗至10%(透气)" 2 " 一键降前车窗至30%(通风)" 3 " Reserved"  ;
VAL_ 670 MMI_AutolightSWCmd 0 " 无指令" 1 " 打开" 2 " 关闭"  ;
VAL_ 670 MMI_RainAutoClsWindowCmd 0 " invalid" 1 " Open" 2 " Close" 3 " Reserved"  ;
VAL_ 670 MMI_RearRightDoorWindowCmd 0 " Invalid" 1 " 一键降右后窗" 2 " 一键升右后窗" 3 " 点动降右后窗" 4 " 点动升右后窗                                                                    0x5～0x7"  ;
VAL_ 670 MMI_RearViewMirrorSelect 0 " Invalid" 1 " 左后视镜" 2 " 右后视镜" 3 " Reserved"  ;
VAL_ 670 MMI_RearViewMirrorUpDown 0 " Invalid" 1 " 上调" 2 " 下调" 3 " Reserved"  ;
VAL_ 670 MMI_RearViewMirrorLeftRight 0 " Invalid" 1 " 左调" 2 " 右调" 3 " Reserved"  ;
VAL_ 670 MMI_LockVehicleWarmingTip 0 " invalid" 1 " flash" 2 " flash with horn" 3 " Reserved"  ;
VAL_ 670 MMI_UnlockVehicleOpenCourtesyLampSW 0 " invalid" 1 " close" 2 " open" 3 " Reserved"  ;
VAL_ 670 MMI_AccLampSet 0 " invalid" 1 " close" 2 " 开启(延迟30s关闭)" 3 " 开启(延迟60s关闭)"  ;
VAL_ 670 MMI_RearViewMirrorAutoFoldFuc 0 " invalid" 1 " close" 2 " open" 3 " Reserved"  ;
VAL_ 792 MMI_LicensePlate_ProvinceName 0 " none；" 1 " 京；" 2 " 津；" 3 " 沪；" 4 " 渝；" 5 " 冀；" 6 " 晋；" 7 " 辽；" 8 " 吉；" 9 " 黑；" 10 " 苏；" 11 " 浙；" 12 " 皖；" 13 " 闽；" 14 " 赣；" 15 " 鲁；" 16 " 豫；" 17 " 鄂；" 18 " 湘；" 19 " 粤；" 20 " 琼；" 21 " 川；" 22 " 贵；" 23 " 云；" 24 " 陕；" 25 " 甘；" 26 " 青；" 27 " 桂；" 28 " 蒙；" 29 " 藏；" 30 " 宁；" 31 " 新；" 63 " invalid"  ;
VAL_ 792 MMI_LicensePlate_Num1 0 " none；" 1 " A；" 2 " B；" 3 " C；" 4 " D；" 5 " E；" 6 " F；" 7 " G；" 8 " H；" 9 " I；" 10 " J；" 11 " K；" 12 " L；" 13 " M；" 14 " N；" 15 " O；" 16 " P；" 17 " Q；" 18 " R；" 19 " S；" 20 " T；" 21 " U；" 22 " V；" 23 " W；" 24 " X；" 25 " Y；" 26 " Z；" 27 " 0；" 28 " 1" 29 " 2；" 30 " 3；" 31 " 4；" 32 " 5；" 33 " 6" 34 " 7；" 35 " 8；" 36 " 9；" 63 " invalid"  ;
VAL_ 792 MMI_LicensePlate_Num2 0 " none；" 1 " A；" 2 " B；" 3 " C；" 4 " D；" 5 " E；" 6 " F；" 7 " G；" 8 " H；" 9 " I；" 10 " J；" 11 " K；" 12 " L；" 13 " M；" 14 " N；" 15 " O；" 16 " P；" 17 " Q；" 18 " R；" 19 " S；" 20 " T；" 21 " U；" 22 " V；" 23 " W；" 24 " X；" 25 " Y；" 26 " Z；" 27 " 0；" 28 " 1" 29 " 2；" 30 " 3；" 31 " 4；" 32 " 5；" 33 " 6" 34 " 7；" 35 " 8；" 36 " 9；" 63 " invalid"  ;
VAL_ 792 MMI_LicensePlate_Num3 0 " none；" 1 " A；" 2 " B；" 3 " C；" 4 " D；" 5 " E；" 6 " F；" 7 " G；" 8 " H；" 9 " I；" 10 " J；" 11 " K；" 12 " L；" 13 " M；" 14 " N；" 15 " O；" 16 " P；" 17 " Q；" 18 " R；" 19 " S；" 20 " T；" 21 " U；" 22 " V；" 23 " W；" 24 " X；" 25 " Y；" 26 " Z；" 27 " 0；" 28 " 1" 29 " 2；" 30 " 3；" 31 " 4；" 32 " 5；" 33 " 6" 34 " 7；" 35 " 8；" 36 " 9；" 63 " invalid"  ;
VAL_ 792 MMI_LicensePlate_Num4 0 " none；" 1 " A；" 2 " B；" 3 " C；" 4 " D；" 5 " E；" 6 " F；" 7 " G；" 8 " H；" 9 " I；" 10 " J；" 11 " K；" 12 " L；" 13 " M；" 14 " N；" 15 " O；" 16 " P；" 17 " Q；" 18 " R；" 19 " S；" 20 " T；" 21 " U；" 22 " V；" 23 " W；" 24 " X；" 25 " Y；" 26 " Z；" 27 " 0；" 28 " 1" 29 " 2；" 30 " 3；" 31 " 4；" 32 " 5；" 33 " 6" 34 " 7；" 35 " 8；" 36 " 9；" 63 " invalid"  ;
VAL_ 792 MMI_LicensePlate_Num5 0 " none；" 1 " A；" 2 " B；" 3 " C；" 4 " D；" 5 " E；" 6 " F；" 7 " G；" 8 " H；" 9 " I；" 10 " J；" 11 " K；" 12 " L；" 13 " M；" 14 " N；" 15 " O；" 16 " P；" 17 " Q；" 18 " R；" 19 " S；" 20 " T；" 21 " U；" 22 " V；" 23 " W；" 24 " X；" 25 " Y；" 26 " Z；" 27 " 0；" 28 " 1" 29 " 2；" 30 " 3；" 31 " 4；" 32 " 5；" 33 " 6" 34 " 7；" 35 " 8；" 36 " 9；" 63 " invalid"  ;
VAL_ 792 MMI_LicensePlate_Num6 0 " none；" 1 " A；" 2 " B；" 3 " C；" 4 " D；" 5 " E；" 6 " F；" 7 " G；" 8 " H；" 9 " I；" 10 " J；" 11 " K；" 12 " L；" 13 " M；" 14 " N；" 15 " O；" 16 " P；" 17 " Q；" 18 " R；" 19 " S；" 20 " T；" 21 " U；" 22 " V；" 23 " W；" 24 " X；" 25 " Y；" 26 " Z；" 27 " 0；" 28 " 1" 29 " 2；" 30 " 3；" 31 " 4；" 32 " 5；" 33 " 6" 34 " 7；" 35 " 8；" 36 " 9；" 63 " invalid"  ;
VAL_ 792 MMI_LicensePlate_Num7 0 " none；" 1 " A；" 2 " B；" 3 " C；" 4 " D；" 5 " E；" 6 " F；" 7 " G；" 8 " H；" 9 " I；" 10 " J；" 11 " K；" 12 " L；" 13 " M；" 14 " N；" 15 " O；" 16 " P；" 17 " Q；" 18 " R；" 19 " S；" 20 " T；" 21 " U；" 22 " V；" 23 " W；" 24 " X；" 25 " Y；" 26 " Z；" 27 " 0；" 28 " 1" 29 " 2；" 30 " 3；" 31 " 4；" 32 " 5；" 33 " 6" 34 " 7；" 35 " 8；" 36 " 9；" 63 " invalid"  ;
VAL_ 390 AVM_BSDLeftWaringSeverity 0 " level0" 1 " level1" 2 " level2" 3 " level3" 127 " invalid"  ;
VAL_ 390 AVM_BSDLeftWaringValid 0 " invalid" 1 " valid"  ;
VAL_ 390 AVM_BSDRightWaringSeverity 0 " level0" 1 " level1" 2 " level2" 3 " level3" 127 " invalid"  ;
VAL_ 390 AVM_BSDRightWaringValid 0 " invalid" 1 " valid"  ;
VAL_ 390 AVM_BSDStatus 0 " BSD not run" 1 " BSD run"  ;
VAL_ 390 AVM_BSDStatusValid 0 " invalid" 1 " valid"  ;
VAL_ 392 AVM_MMI_ConnectStatus 0 " none/提示用户AVM_ECU等待连接" 1 " disconnect/提示用户AVM_ECU断开连接" 2 " connected" 15 " invalid/提示用户AVM_ECU连接异常"  ;
VAL_ 392 AVM_MMI_EcuStatus 0 " none/提示用户AVM_ECU上电中" 1 " power off/提示用户AVM_ECU已下电" 2 " power on" 3 " reserved" 4 " reserved" 5 " reserved" 6 " reserved" 7 " reserved" 8 " reserved" 9 " reserved" 10 " reserved" 11 " reserved" 12 " reserved" 13 " reserved" 14 " reserved" 15 " invalid"  ;
VAL_ 392 AVM_MMI_VideoOutputStatus 0 " none/显示MMI画面" 1 " off/显示MMI画面" 2 " on/显示AVM画面" 3 " invalid"  ;
VAL_ 392 AVM_MMI_AVM3DViewModeStatus 0 " none" 1 " 2d" 2 " 3d" 3 " speed3D" 4 " Ctv_Front" 5 " Ctv_Rear" 6 " Rim_Front" 7 " Rim_Rear" 8 " reserved" 9 " reserved" 10 " reserved" 11 " reserved" 12 " reserved" 13 " reserved" 14 " reserved" 15 " invalid"  ;
VAL_ 392 AVM_MMI_AVM3DViewSwitch 0 " none" 1 " 2d_front" 2 " 2d_right" 3 " 2d_left" 4 " 2d_rear" 5 " reserved" 6 " reserved" 7 " reserved" 8 " reserved" 9 " reserved" 10 " reserved" 11 " reserved" 12 " reserved" 13 " reserved" 14 " reserved" 15 " reserved" 16 " reserved" 17 " 3d_front" 18 " 3d_right" 19 " 3d_left" 20 " 3d_rear" 21 " 3d_right_front" 22 " 3d_left_front" 23 " 3d_left_rear" 24 " 3d_right_rear" 25 " reserved" 26 " reserved" 27 " reserved" 28 " reserved" 29 " reserved" 30 " reserved" 31 " reserved" 32 " reserved" 33 " reserved" 34 " reserved" 35 " reserved" 36 " reserved" 37 " reserved" 38 " reserved" 39 " reserved" 40 " reserved" 41 " reserved" 42 " reserved" 43 " reserved" 44 " reserved" 45 " reserved" 46 " reserved" 47 " reserved" 48 " reserved" 49 " reserved" 50 " reserved" 51 " reserved" 52 " reserved" 53 " reserved" 54 " reserved" 55 " reserved" 56 " reserved" 57 " reserved" 58 " reserved" 59 " reserved" 60 " reserved" 61 " reserved" 62 " reserved" 63 " reserved" 64 " reserved" 65 " reserved" 66 " reserved" 67 " reserved" 68 " reserved" 69 " reserved" 70 " reserved" 71 " reserved" 72 " reserved" 73 " reserved" 74 " reserved" 75 " reserved" 76 " reserved" 77 " reserved" 78 " reserved" 79 " reserved" 80 " reserved" 81 " reserved" 82 " reserved" 83 " reserved" 84 " reserved" 85 " reserved" 86 " reserved" 87 " reserved" 88 " reserved" 89 " reserved" 90 " reserved" 91 " reserved" 92 " reserved" 93 " reserved" 94 " reserved" 95 " reserved" 96 " reserved" 97 " reserved" 98 " reserved" 99 " reserved" 100 " reserved" 101 " reserved" 102 " reserved" 103 " reserved" 104 " reserved" 105 " reserved" 106 " reserved" 107 " reserved" 108 " reserved" 109 " reserved" 110 " reserved" 111 " reserved" 112 " reserved" 113 " reserved" 114 " reserved" 115 " reserved" 116 " reserved" 117 " reserved" 118 " reserved" 119 " reserved" 120 " reserved" 121 " reserved" 122 " reserved" 123 " reserved" 124 " reserved" 125 " reserved" 126 " reserved" 127 " reserved" 128 " reserved" 129 " reserved" 130 " reserved" 131 " reserved" 132 " reserved" 133 " reserved" 134 " reserved" 135 " reserved" 136 " reserved" 137 " reserved" 138 " reserved" 139 " reserved" 140 " reserved" 141 " reserved" 142 " reserved" 143 " reserved" 144 " reserved" 145 " reserved" 146 " reserved" 147 " reserved" 148 " reserved" 149 " reserved" 150 " reserved" 151 " reserved" 152 " reserved" 153 " reserved" 154 " reserved" 155 " reserved" 156 " reserved" 157 " reserved" 158 " reserved" 159 " reserved" 160 " reserved" 161 " reserved" 162 " reserved" 163 " reserved" 164 " reserved" 165 " reserved" 166 " reserved" 167 " reserved" 168 " reserved" 169 " reserved" 170 " reserved" 171 " reserved" 172 " reserved" 173 " reserved" 174 " reserved" 175 " reserved" 176 " reserved" 177 " reserved" 178 " reserved" 179 " reserved" 180 " reserved" 181 " reserved" 182 " reserved" 183 " reserved" 184 " reserved" 185 " reserved" 186 " reserved" 187 " reserved" 188 " reserved" 189 " reserved" 190 " reserved" 191 " reserved" 192 " reserved" 193 " reserved" 194 " reserved" 195 " reserved" 196 " reserved" 197 " reserved" 198 " reserved" 199 " reserved" 200 " reserved" 201 " reserved" 202 " reserved" 203 " reserved" 204 " reserved" 205 " reserved" 206 " reserved" 207 " reserved" 208 " reserved" 209 " reserved" 210 " reserved" 211 " reserved" 212 " reserved" 213 " reserved" 214 " reserved" 215 " reserved" 216 " reserved" 217 " reserved" 218 " reserved" 219 " reserved" 220 " reserved" 221 " reserved" 222 " reserved" 223 " reserved" 224 " reserved" 225 " reserved" 226 " reserved" 227 " reserved" 228 " reserved" 229 " reserved" 230 " reserved" 231 " reserved" 232 " reserved" 233 " reserved" 234 " reserved" 235 " reserved" 236 " reserved" 237 " reserved" 238 " reserved" 239 " reserved" 240 " reserved" 241 " reserved" 242 " reserved" 243 " reserved" 244 " reserved" 245 " reserved" 246 " reserved" 247 " reserved" 248 " reserved" 249 " reserved" 250 " reserved" 251 " reserved" 252 " reserved" 253 " reserved" 254 " reserved" 255 " reserved"  ;
VAL_ 636 AVM_MMI_LanguageSet 0 " none" 1 " English" 2 " Chinese" 3 " reserved" 4 " reserved" 5 " reserved" 6 " reserved" 7 " reserved" 8 " reserved" 9 " reserved" 10 " reserved" 11 " reserved" 12 " reserved" 13 " reserved" 14 " reserved" 15 " invalid"  ;
VAL_ 636 AVM_MMI_AVM3DDynTrajSet 0 " none" 1 " off" 2 " on" 3 " invalid"  ;
VAL_ 636 AVM_MMI_AVM3DExitDelaySet 0 " none" 1 " off" 2 " on" 3 " invalid"  ;
VAL_ 636 AVM_MMI_AVM3DTurnLightSet 0 " none" 1 " off" 2 " on" 3 " invalid"  ;
VAL_ 636 AVM_MMI_AVM3DBlindFillSet 0 " none" 1 " off" 2 " on" 3 " invalid"  ;
VAL_ 636 AVM_MMI_BSDFunction 0 " none" 1 " off" 2 " on" 3 " invalid"  ;
VAL_ 636 AVM_MMI_OTFunction 0 " none" 1 " off" 2 " on" 3 " invalid"  ;
VAL_ 636 AVM_MMI_AVM3DCarIconColor 0 " none" 1 "red" 2 "yellow" 3 "blue" 4 "white" 5 "black" 6 " reserved" 7 " reserved" 8 " reserved" 9 " reserved" 10 " reserved" 11 " reserved" 12 " reserved" 13 " reserved" 14 " reserved" 15 " invalid"  ;
VAL_ 636 AVM_MMI_AVM3DCarIconTransparent 0 " 车模透明度的0~100%" 1 " 车模透明度的0~100%" 2 " 车模透明度的0~100%" 3 " 车模透明度的0~100%" 4 " 车模透明度的0~100%" 5 " 车模透明度的0~100%" 6 " 车模透明度的0~100%" 7 " 车模透明度的0~100%" 8 " 车模透明度的0~100%" 9 " 车模透明度的0~100%" 10 " 车模透明度的0~100%" 11 " 车模透明度的0~100%" 12 " 车模透明度的0~100%" 13 " 车模透明度的0~100%" 14 " 车模透明度的0~100%" 15 " 车模透明度的0~100%" 16 " 车模透明度的0~100%" 17 " 车模透明度的0~100%" 18 " 车模透明度的0~100%" 19 " 车模透明度的0~100%" 20 " 车模透明度的0~100%" 21 " 车模透明度的0~100%" 22 " 车模透明度的0~100%" 23 " 车模透明度的0~100%" 24 " 车模透明度的0~100%" 25 " 车模透明度的0~100%" 26 " 车模透明度的0~100%" 27 " 车模透明度的0~100%" 28 " 车模透明度的0~100%" 29 " 车模透明度的0~100%" 30 " 车模透明度的0~100%" 31 " 车模透明度的0~100%" 32 " 车模透明度的0~100%" 33 " 车模透明度的0~100%" 34 " 车模透明度的0~100%" 35 " 车模透明度的0~100%" 36 " 车模透明度的0~100%" 37 " 车模透明度的0~100%" 38 " 车模透明度的0~100%" 39 " 车模透明度的0~100%" 40 " 车模透明度的0~100%" 41 " 车模透明度的0~100%" 42 " 车模透明度的0~100%" 43 " 车模透明度的0~100%" 44 " 车模透明度的0~100%" 45 " 车模透明度的0~100%" 46 " 车模透明度的0~100%" 47 " 车模透明度的0~100%" 48 " 车模透明度的0~100%" 49 " 车模透明度的0~100%" 50 " 车模透明度的0~100%" 51 " 车模透明度的0~100%" 52 " 车模透明度的0~100%" 53 " 车模透明度的0~100%" 54 " 车模透明度的0~100%" 55 " 车模透明度的0~100%" 56 " 车模透明度的0~100%" 57 " 车模透明度的0~100%" 58 " 车模透明度的0~100%" 59 " 车模透明度的0~100%" 60 " 车模透明度的0~100%" 61 " 车模透明度的0~100%" 62 " 车模透明度的0~100%" 63 " 车模透明度的0~100%" 64 " 车模透明度的0~100%" 65 " 车模透明度的0~100%" 66 " 车模透明度的0~100%" 67 " 车模透明度的0~100%" 68 " 车模透明度的0~100%" 69 " 车模透明度的0~100%" 70 " 车模透明度的0~100%" 71 " 车模透明度的0~100%" 72 " 车模透明度的0~100%" 73 " 车模透明度的0~100%" 74 " 车模透明度的0~100%" 75 " 车模透明度的0~100%" 76 " 车模透明度的0~100%" 77 " 车模透明度的0~100%" 78 " 车模透明度的0~100%" 79 " 车模透明度的0~100%" 80 " 车模透明度的0~100%" 81 " 车模透明度的0~100%" 82 " 车模透明度的0~100%" 83 " 车模透明度的0~100%" 84 " 车模透明度的0~100%" 85 " 车模透明度的0~100%" 86 " 车模透明度的0~100%" 87 " 车模透明度的0~100%" 88 " 车模透明度的0~100%" 89 " 车模透明度的0~100%" 90 " 车模透明度的0~100%" 91 " 车模透明度的0~100%" 92 " 车模透明度的0~100%" 93 " 车模透明度的0~100%" 94 " 车模透明度的0~100%" 95 " 车模透明度的0~100%" 96 " 车模透明度的0~100%" 97 " 车模透明度的0~100%" 98 " 车模透明度的0~100%" 99 " 车模透明度的0~100%" 100 " 车模透明度的0~100%" 255 "invalid"  ;
VAL_ 778 AVM_LicensePlate_ProvinceName 0 " none；" 1 " 京；" 2 " 津；" 3 " 沪；" 4 " 渝；" 5 " 冀；" 6 " 晋；" 7 " 辽；" 8 " 吉；" 9 " 黑；" 10 " 苏；" 11 " 浙；" 12 " 皖；" 13 " 闽；" 14 " 赣；" 15 " 鲁；" 16 " 豫；" 17 " 鄂；" 18 " 湘；" 19 " 粤；" 20 " 琼；" 21 " 川；" 22 " 贵；" 23 " 云；" 24 " 陕；" 25 " 甘；" 26 " 青；" 27 " 桂；" 28 " 蒙；" 29 " 藏；" 30 " 宁；" 31 " 新；" 63 " invalid"  ;
VAL_ 778 AVM_LicensePlate_Num1 0 " none；" 1 " A；" 2 " B；" 3 " C；" 4 " D；" 5 " E；" 6 " F；" 7 " G；" 8 " H；" 9 " I；" 10 " J；" 11 " K；" 12 " L；" 13 " M；" 14 " N；" 15 " O；" 16 " P；" 17 " Q；" 18 " R；" 19 " S；" 20 " T；" 21 " U；" 22 " V；" 23 " W；" 24 " X；" 25 " Y；" 26 " Z；" 27 " 0；" 28 " 1" 29 " 2；" 30 " 3；" 31 " 4；" 32 " 5；" 33 " 6" 34 " 7；" 35 " 8；" 36 " 9；" 63 " invalid"  ;
VAL_ 778 AVM_LicensePlate_Num2 0 " none；" 1 " A；" 2 " B；" 3 " C；" 4 " D；" 5 " E；" 6 " F；" 7 " G；" 8 " H；" 9 " I；" 10 " J；" 11 " K；" 12 " L；" 13 " M；" 14 " N；" 15 " O；" 16 " P；" 17 " Q；" 18 " R；" 19 " S；" 20 " T；" 21 " U；" 22 " V；" 23 " W；" 24 " X；" 25 " Y；" 26 " Z；" 27 " 0；" 28 " 1" 29 " 2；" 30 " 3；" 31 " 4；" 32 " 5；" 33 " 6" 34 " 7；" 35 " 8；" 36 " 9；" 63 " invalid"  ;
VAL_ 778 AVM_LicensePlate_Num3 0 " none；" 1 " A；" 2 " B；" 3 " C；" 4 " D；" 5 " E；" 6 " F；" 7 " G；" 8 " H；" 9 " I；" 10 " J；" 11 " K；" 12 " L；" 13 " M；" 14 " N；" 15 " O；" 16 " P；" 17 " Q；" 18 " R；" 19 " S；" 20 " T；" 21 " U；" 22 " V；" 23 " W；" 24 " X；" 25 " Y；" 26 " Z；" 27 " 0；" 28 " 1" 29 " 2；" 30 " 3；" 31 " 4；" 32 " 5；" 33 " 6" 34 " 7；" 35 " 8；" 36 " 9；" 63 " invalid"  ;
VAL_ 778 AVM_LicensePlate_Num4 0 " none；" 1 " A；" 2 " B；" 3 " C；" 4 " D；" 5 " E；" 6 " F；" 7 " G；" 8 " H；" 9 " I；" 10 " J；" 11 " K；" 12 " L；" 13 " M；" 14 " N；" 15 " O；" 16 " P；" 17 " Q；" 18 " R；" 19 " S；" 20 " T；" 21 " U；" 22 " V；" 23 " W；" 24 " X；" 25 " Y；" 26 " Z；" 27 " 0；" 28 " 1" 29 " 2；" 30 " 3；" 31 " 4；" 32 " 5；" 33 " 6" 34 " 7；" 35 " 8；" 36 " 9；" 63 " invalid"  ;
VAL_ 778 AVM_LicensePlate_Num5 0 " none；" 1 " A；" 2 " B；" 3 " C；" 4 " D；" 5 " E；" 6 " F；" 7 " G；" 8 " H；" 9 " I；" 10 " J；" 11 " K；" 12 " L；" 13 " M；" 14 " N；" 15 " O；" 16 " P；" 17 " Q；" 18 " R；" 19 " S；" 20 " T；" 21 " U；" 22 " V；" 23 " W；" 24 " X；" 25 " Y；" 26 " Z；" 27 " 0；" 28 " 1" 29 " 2；" 30 " 3；" 31 " 4；" 32 " 5；" 33 " 6" 34 " 7；" 35 " 8；" 36 " 9；" 63 " invalid"  ;
VAL_ 778 AVM_LicensePlate_Num6 0 " none；" 1 " A；" 2 " B；" 3 " C；" 4 " D；" 5 " E；" 6 " F；" 7 " G；" 8 " H；" 9 " I；" 10 " J；" 11 " K；" 12 " L；" 13 " M；" 14 " N；" 15 " O；" 16 " P；" 17 " Q；" 18 " R；" 19 " S；" 20 " T；" 21 " U；" 22 " V；" 23 " W；" 24 " X；" 25 " Y；" 26 " Z；" 27 " 0；" 28 " 1" 29 " 2；" 30 " 3；" 31 " 4；" 32 " 5；" 33 " 6" 34 " 7；" 35 " 8；" 36 " 9；" 63 " invalid"  ;
VAL_ 778 AVM_LicensePlate_Num7 0 " none；" 1 " A；" 2 " B；" 3 " C；" 4 " D；" 5 " E；" 6 " F；" 7 " G；" 8 " H；" 9 " I；" 10 " J；" 11 " K；" 12 " L；" 13 " M；" 14 " N；" 15 " O；" 16 " P；" 17 " Q；" 18 " R；" 19 " S；" 20 " T；" 21 " U；" 22 " V；" 23 " W；" 24 " X；" 25 " Y；" 26 " Z；" 27 " 0；" 28 " 1" 29 " 2；" 30 " 3；" 31 " 4；" 32 " 5；" 33 " 6" 34 " 7；" 35 " 8；" 36 " 9；" 63 " invalid"  ;
VAL_ 586 ACU_AirBagSysWrnLmpCmd 0 " Off" 1 " On"  ;
VAL_ 586 ACU_Crashinfo 0 " no crash" 1 " front crash" 2 " left side crash" 3 " right side crash" 4 "rear crash" 5 " reserved" 6 " reserved" 7 " invalid"  ;
VAL_ 352 ACC_Torque_Request_Status 0 " No request" 1 " Request"  ;
VAL_ 352 ACC_Set_Headway 0 " No gap set" 1 " Distance stage 1" 2 " Distance stage 2" 3 " Distance stage 3" 4 " Distance stage 4" 5 " Reserved" 6 " Reserved" 7 " Invalid"  ;
VAL_ 352 ACC_Standstill_Request 0 " No request" 1 " Request"  ;
VAL_ 352 ACC_Decelerate_Request_Status 0 " No request" 1 " Request"  ;
VAL_ 354 AEB_EHB_StopReq 0 " No request" 1 " Request"  ;
VAL_ 354 AEB_Jerk_Request 0 " No request" 1 " Request"  ;
VAL_ 354 AEB_Prefill_Request 0 " No request" 1 " Request"  ;
VAL_ 354 AEB_Decelerate_Request_Status 0 " No request" 1 " Request"  ;
VAL_ 354 AEB_State 0 " Unavailable state" 1 " Off" 2 " Standby" 3 " Active (no intervention)" 4 " Active"  ;
VAL_ 354 FCW_State 0 " Unavailable state" 1 " Off" 2 " Standby" 3 " Active (no intervention)" 4 " Active"  ;
VAL_ 354 ADAS_Sensorstatus 0 " No error" 1 " System Initialize摄像头初始化" 2 " Sensor blocked摄像头被遮挡" 3 " service requoired摄像头系统故障" 4 " Reserved" 5 " Reserved" 6 " Reserved" 7 " Reserved"  ;
VAL_ 354 HW_Warning_Level 0 " No warning" 1 " Warning Level 1" 2 " Warning Level 2" 3 " Reserved"  ;
VAL_ 354 FCW_Warning_Level 0 " No warning" 1 " Warning Level 1" 2 " Warning Level 2" 3 " Reserved"  ;
VAL_ 354 ACC_Override_Indicator 0 " No request" 1 " Request"  ;
VAL_ 354 ACC_CIPV_Indicator 0 " No request" 1 " Request"  ;
VAL_ 354 ACC_Auto_Cancel 0 " No request" 1 " Condition dissatisfy" 2 " Function cancel"  ;
VAL_ 354 ACC_Driver_Cancel 0 " No request" 1 " Request"  ;
VAL_ 354 ACC_State 0 " Unavailable state" 1 " Off" 2 " Standby" 3 " Active" 4 " Exit"  ;
VAL_ 354 ACC_Go_Indicator 0 " No request" 1 " Request"  ;
VAL_ 354 ACC_Takeover_Indicator 0 " No request" 1 " Request"  ;
VAL_ 356 TSR_State 0 " Unavailable state" 1 " Off" 2 " Standby" 3 " Active (no intervention)" 4 " Active"  ;
VAL_ 356 DAS_TSR_Main_Switch 0 " off" 1 " on"  ;
VAL_ 356 IHC_Mainbeam_Request 0 " On" 1 " Off"  ;
VAL_ 356 IHC_State 0 " Unavailable state" 1 " Off" 2 " Standby" 3 " Active (no intervention)" 4 " Active"  ;
VAL_ 356 LDW_Line_Detect_Status 0 " Neither side lane mark detected" 1 " Left side lane mark detected" 2 " Right side lane mark detected" 3 " Both side lane marks detected"  ;
VAL_ 356 LDW_Warning 0 " No warning" 1 " Left Warning" 2 " Right Warning" 3 " Reserved"  ;
VAL_ 356 LDW_State 0 " Unavailable state" 1 " Off" 2 " Standby" 3 " Active (no intervention)" 4 " Active"  ;
VAL_ 356 TSR_Targetspeed_Request 0 " release warning识别到限速解除" 255 " Invalid"  ;
VAL_ 356 LKA_Torque_Request_Status 0 " no torque request" 1 " torque request"  ;
VAL_ 356 LKA_State 0 " Unavailable state" 1 " Off" 2 " Standby" 3 " Active (no intervene)" 4 " Active" 5 " Exit"  ;
VAL_ 356 LKA_Takeover_Request 0 " No Request" 1 " Request"  ;
VAL_ 356 LKA_Hands_Off_Warning 0 " No warning" 1 " Warning"  ;
VAL_ 356 DAS_LDW_Main_Switch 0 " Off" 1 " On"  ;
VAL_ 356 DAS_LDW_Sensitivity 0 " Reserved" 1 " Level 1" 2 " Level 2" 3 " Level 3"  ;
VAL_ 356 DAS_FCW_Main_Switch 0 " Off" 1 " On"  ;
VAL_ 356 DAS_FCW_Sensitivity 0 " Reserved" 1 " Level 1" 2 " Level 2" 3 " Level 3"  ;
VAL_ 356 DAS_AEB_Main_Switch 0 " Off" 1 " On"  ;
VAL_ 356 DAS_IHC_Main_Switch 0 " Off" 1 " On"  ;
VAL_ 384 APA_MMI_ConnectStatus 0 " none/提示用户APA_ECU等待连接" 1 " disconnect/提示用户APA_ECU断开连接" 2 " connected" 15 " invalid/提示用户APA_ECU连接异常"  ;
VAL_ 384 APA_MMI_EcuStatus 0 " none/提示用户APA_ECU上电中" 1 " power off/提示用户APA_ECU已下电" 2 " power on" 3 " reserved" 4 " reserved" 5 " reserved" 6 " reserved" 7 " reserved" 8 " reserved" 9 " reserved" 10 " reserved" 11 " reserved" 12 " reserved" 13 " reserved" 14 " reserved" 15 " invalid/提示用户APA_ECU状态异常"  ;
VAL_ 384 APA_MMI_VideoOutputStatus 0 " none/显示MMI画面" 1 " off/显示MMI画面" 2 " on/显示APA画面" 3 " invalid/显示MMI画面"  ;
VAL_ 384 APA_MMI_3DViewModeStatus 0 " none" 1 " 2d" 2 " 3d" 3 " speed3D" 4 " Ctv_Front" 5 " Ctv_Rear" 6 " Rim_Front" 7 " Rim_Rear" 8 " reserved" 9 " reserved" 10 " reserved" 11 " reserved" 12 " reserved" 13 " reserved" 14 " reserved" 15 " invalid"  ;
VAL_ 384 APA_MMI_AVM3DViewSwitch 0 " none" 1 " 2d_front" 2 " 2d_right" 3 " 2d_left" 4 " 2d_rear" 5 " reserved" 6 " reserved" 7 " reserved" 8 " reserved" 9 " reserved" 10 " reserved" 11 " reserved" 12 " reserved" 13 " reserved" 14 " reserved" 15 " reserved" 16 " reserved" 17 " 3d_front" 18 " 3d_right" 19 " 3d_left" 20 " 3d_rear" 21 " 3d_right_front" 22 " 3d_left_front" 23 " 3d_left_rear" 24 " 3d_right_rear" 25 " reserved" 26 " reserved" 27 " reserved" 28 " reserved" 29 " reserved" 30 " reserved" 31 " reserved" 32 " reserved" 33 " reserved" 34 " reserved" 35 " reserved" 36 " reserved" 37 " reserved" 38 " reserved" 39 " reserved" 40 " reserved" 41 " reserved" 42 " reserved" 43 " reserved" 44 " reserved" 45 " reserved" 46 " reserved" 47 " reserved" 48 " reserved" 49 " reserved" 50 " reserved" 51 " reserved" 52 " reserved" 53 " reserved" 54 " reserved" 55 " reserved" 56 " reserved" 57 " reserved" 58 " reserved" 59 " reserved" 60 " reserved" 61 " reserved" 62 " reserved" 63 " reserved" 64 " reserved" 65 " reserved" 66 " reserved" 67 " reserved" 68 " reserved" 69 " reserved" 70 " reserved" 71 " reserved" 72 " reserved" 73 " reserved" 74 " reserved" 75 " reserved" 76 " reserved" 77 " reserved" 78 " reserved" 79 " reserved" 80 " reserved" 81 " reserved" 82 " reserved" 83 " reserved" 84 " reserved" 85 " reserved" 86 " reserved" 87 " reserved" 88 " reserved" 89 " reserved" 90 " reserved" 91 " reserved" 92 " reserved" 93 " reserved" 94 " reserved" 95 " reserved" 96 " reserved" 97 " reserved" 98 " reserved" 99 " reserved" 100 " reserved" 101 " reserved" 102 " reserved" 103 " reserved" 104 " reserved" 105 " reserved" 106 " reserved" 107 " reserved" 108 " reserved" 109 " reserved" 110 " reserved" 111 " reserved" 112 " reserved" 113 " reserved" 114 " reserved" 115 " reserved" 116 " reserved" 117 " reserved" 118 " reserved" 119 " reserved" 120 " reserved" 121 " reserved" 122 " reserved" 123 " reserved" 124 " reserved" 125 " reserved" 126 " reserved" 127 " reserved" 128 " reserved" 129 " reserved" 130 " reserved" 131 " reserved" 132 " reserved" 133 " reserved" 134 " reserved" 135 " reserved" 136 " reserved" 137 " reserved" 138 " reserved" 139 " reserved" 140 " reserved" 141 " reserved" 142 " reserved" 143 " reserved" 144 " reserved" 145 " reserved" 146 " reserved" 147 " reserved" 148 " reserved" 149 " reserved" 150 " reserved" 151 " reserved" 152 " reserved" 153 " reserved" 154 " reserved" 155 " reserved" 156 " reserved" 157 " reserved" 158 " reserved" 159 " reserved" 160 " reserved" 161 " reserved" 162 " reserved" 163 " reserved" 164 " reserved" 165 " reserved" 166 " reserved" 167 " reserved" 168 " reserved" 169 " reserved" 170 " reserved" 171 " reserved" 172 " reserved" 173 " reserved" 174 " reserved" 175 " reserved" 176 " reserved" 177 " reserved" 178 " reserved" 179 " reserved" 180 " reserved" 181 " reserved" 182 " reserved" 183 " reserved" 184 " reserved" 185 " reserved" 186 " reserved" 187 " reserved" 188 " reserved" 189 " reserved" 190 " reserved" 191 " reserved" 192 " reserved" 193 " reserved" 194 " reserved" 195 " reserved" 196 " reserved" 197 " reserved" 198 " reserved" 199 " reserved" 200 " reserved" 201 " reserved" 202 " reserved" 203 " reserved" 204 " reserved" 205 " reserved" 206 " reserved" 207 " reserved" 208 " reserved" 209 " reserved" 210 " reserved" 211 " reserved" 212 " reserved" 213 " reserved" 214 " reserved" 215 " reserved" 216 " reserved" 217 " reserved" 218 " reserved" 219 " reserved" 220 " reserved" 221 " reserved" 222 " reserved" 223 " reserved" 224 " reserved" 225 " reserved" 226 " reserved" 227 " reserved" 228 " reserved" 229 " reserved" 230 " reserved" 231 " reserved" 232 " reserved" 233 " reserved" 234 " reserved" 235 " reserved" 236 " reserved" 237 " reserved" 238 " reserved" 239 " reserved" 240 " reserved" 241 " reserved" 242 " reserved" 243 " reserved" 244 " reserved" 245 " reserved" 246 " reserved" 247 " reserved" 248 " reserved" 249 " reserved" 250 " reserved" 251 " reserved" 252 " reserved" 253 " reserved" 254 " reserved" 255 " reserved"  ;
VAL_ 386 APA_BSDLeftWaringSeverity 0 " level0" 1 " level1" 2 " level2" 3 " level3" 127 " invalid"  ;
VAL_ 386 APA_BSDLeftWaringValid 0 " invalid" 1 " valid"  ;
VAL_ 386 APA_BSDRightWaringSeverity 0 " level0" 1 " level1" 2 " level2" 3 " level3" 127 " invalid"  ;
VAL_ 386 APA_BSDRightWaringValid 0 " invalid" 1 " valid"  ;
VAL_ 386 APA_BSDStatus 0 " BSD not run" 1 " BSD run"  ;
VAL_ 386 APA_BSDStatusValid 0 " invalid" 1 " valid"  ;
VAL_ 784 APA_AVM_MCU_Version 0 " none" 16777215 " invalid"  ;
VAL_ 784 APA_AVM_BSP_Version 0 " none" 16777215 " invalid"  ;
VAL_ 786 APA_AVM_ZADAS_Version 0 " none" 16777215 " invalid"  ;
VAL_ 786 APA_Avm3d_licenseStatus 0 " none" 1 " no license" 2 " has license" 3 " invalid"  ;
VAL_ 786 APA_BSD_licenseStatus 0 " none" 1 " no license" 2 " has license" 3 " invalid"  ;
VAL_ 514 BMS_Relay_POS 0 " OFF断开；" 1 " ON吸合；" 2 " adhesion粘连；" 3 " reserved保留"  ;
VAL_ 514 BMS_Boot_Detection 0 " False；" 1 " Pull"  ;
VAL_ 514 BMS_A 0 " False；" 1 " Pull"  ;
VAL_ 514 BMS_Relay_HEAT 0 " OFF断开；" 1 " ON吸合；" 2 " adhesion粘连；" 3 " reserved保留"  ;
VAL_ 514 BMS_ChrgAllowance 0 " Invalid" 1 " 交流 充电允许" 2 " 交流加热允许" 3 " 直流充电允许；" 4 " 直流加热允许；" 5 " Reserved" 6 " Reserved" 7 " Reserved"  ;
VAL_ 514 BMS_Sys_ChgorDisChrgSts 0 " Invalid" 1 " Discharging" 2 " Charging（快充中）" 3 " Charging（慢充中）"  ;
VAL_ 514 BMS_FastChrgSts 0 " Invalid" 1 " Not charged未充电" 2 " 充电就绪" 3 " 充电中" 4 " charged充电完成" 5 " Error 一般故障不断继电器" 6 " 故障断继电器" 7 " Reserved保留"  ;
VAL_ 514 BMS_SlowChrgSts 0 " Invalid" 1 " Not charged未充电" 2 " 充电就绪" 3 " 充电中" 4 " charged充电完成" 5 " Error 一般故障不断继电器" 6 " 故障断继电器" 7 " Reserved保留"  ;
VAL_ 514 BMS_Battery_Coulomb_Satus 0 " Normal" 1 " Low 电池容量低" 2 " Reserved" 3 " Reserved"  ;
VAL_ 514 BMS_ChrgCouplesSt 0 " Disconnected" 1 " Quick_charge_Connect" 2 " Reserved" 3 " Reserved"  ;
VAL_ 514 BMS_req_ConnectChargeRelay 0 " no request" 1 " open" 2 " Connect" 3 " Reserved"  ;
VAL_ 514 BMS_DischgAllow 0 " prohibit" 1 " allow"  ;
VAL_ 514 BMS_request_subscribe_allow 0 " prohibit" 1 " allow"  ;
VAL_ 514 BMS_CC2 0 " disconnected未连接；" 1 " half-connected连接；"  ;
VAL_ 514 BMS_PauseContinueChrgStus 0 " invalid" 1 " 暂停充电" 2 " 继续充电" 3 " reserved"  ;
VAL_ 518 BMS_ThermalManageReq 0 " no request" 1 " heating" 2 " cooling" 3 " pump cycle"  ;
VAL_ 524 BMS_Powertrain_System_fault 0 " fault-free无故障；" 1 " First-level faults一级故障；" 2 " Second-degree faults二级故障；" 3 " Level three faults三级故障"  ;
VAL_ 524 BMS_cell_Voltage_low 0 " fault-free无故障；" 1 " First-level faults一级故障；" 2 " Second-degree faults二级故障；" 3 " Level three faults三级故障"  ;
VAL_ 524 BMS_cell_Voltage_High 0 " fault-free无故障；" 1 " First-level faults一级故障；" 2 " Second-degree faults二级故障；" 3 " Level three faults三级故障"  ;
VAL_ 524 BMS_Battery_LowTemp_warning 0 " fault-free无故障；" 1 " First-level faults一级故障；" 2 " Second-degree faults二级故障；" 3 " Level three faults三级故障"  ;
VAL_ 524 BMS_Battery_HighTemp_warning 0 " fault-free无故障；" 1 " First-level faults一级故障；" 2 " Second-degree faults二级故障；" 3 " Level three faults三级故障"  ;
VAL_ 524 BMS_SOCHigh_Warning 0 " fault-free无故障；" 1 " First-level faults一级故障；" 2 " Second-degree faults二级故障；" 3 " Level three faults三级故障"  ;
VAL_ 524 BMS_SOCLow_Warning 0 " fault-free无故障；" 1 " First-level faults一级故障；" 2 " Second-degree faults二级故障；" 3 " Level three faults三级故障"  ;
VAL_ 524 BMS_Battery_SumVoltage_High 0 " fault-free无故障；" 1 " First-level faults一级故障；" 2 " Second-degree faults二级故障；" 3 " Level three faults三级故障"  ;
VAL_ 524 BMS_Battery_SumVoltage_Low 0 " fault-free无故障；" 1 " First-level faults一级故障；" 2 " Second-degree faults二级故障；" 3 " Level three faults三级故障"  ;
VAL_ 524 BMS_HVBatCellDiffFalt 0 " fault-free无故障；" 1 " First-level faults一级故障；" 2 " Second-degree faults二级故障；" 3 " Level three faults三级故障"  ;
VAL_ 524 BMS_Err_OverVoltageFault 0 " fault-free无故障；" 1 " First-level faults一级故障；" 2 " Second-degree faults二级故障；" 3 " Level three faults三级故障"  ;
VAL_ 524 BMS_Battery_charge_Fault 0 " fault-free无故障；" 1 " First-level faults一级故障；" 2 " Second-degree faults二级故障；" 3 " Level three faults三级故障"  ;
VAL_ 524 BMS_SOCJump_Warning 0 " fault-free无故障；" 1 " First-level faults一级故障；" 2 " Second-degree faults二级故障；" 3 " Level three faults三级故障"  ;
VAL_ 524 BMS_Err_CellT_Low 0 " fault-free无故障；" 1 " First-level faults一级故障；" 2 " Second-degree faults二级故障；" 3 " Level three faults三级故障"  ;
VAL_ 524 BMS_Err_CellT_High 0 " fault-free无故障；" 1 " First-level faults一级故障；" 2 " Second-degree faults二级故障；" 3 " Level three faults三级故障"  ;
VAL_ 524 BMS_BatNotMatchFlt 0 " fault-free无故障；" 1 " fault 故障；" 2 " Reserved" 3 " Reserved"  ;
VAL_ 524 BMS_Err_ISO_LOW 0 " fault-free无故障；" 1 " First-level faults一级故障；" 2 " Second-degree faults二级故障；" 3 " Level three faults三级故障"  ;
VAL_ 524 BMS_Err_ChgCurrent_High 0 " fault-free无故障；" 1 " First-level faults一级故障；" 2 " Second-degree faults二级故障；" 3 " Level three faults三级故障"  ;
VAL_ 524 BMS_Err_DchCurrent_High 0 " fault-free无故障；" 1 " First-level faults一级故障；" 2 " Second-degree faults二级故障；" 3 " Level three faults三级故障"  ;
VAL_ 524 BMS_Err_DtT_High 0 " fault-free无故障；" 1 " First-level faults一级故障；" 2 " Second-degree faults二级故障；" 3 " Level three faults三级故障"  ;
VAL_ 524 ThermalManage_System_fault 0 " 无故障；" 1 " 一级故障；" 2 " 二级故障；" 3 " 三级故障"  ;
VAL_ 524 BMS_Err_comunicacion 0 " fault-free无故障；" 1 " Internal communication failure内部通讯故障；" 2 " External communication failure外部通讯故障；" 3 " reserved预留"  ;
VAL_ 524 BMS_Err_InterLock 0 " fault-free无故障；" 1 " Interlock faults互锁故障"  ;
VAL_ 524 BMS_Circuit_Protection 0 " normal正常；" 1 " open短路保护开启"  ;
VAL_ 524 BMS_FeedFault 0 " fault-free无故障；" 1 " First-level faults一级故障；" 2 " Second-degree faults二级故障；" 3 " Level three faults三级故障"  ;
